VERSION "eCMP INFO-DIV vehicle review 2026-11-03; 125000 bit/s; PSA-RE 67f7581e7622410efdbb29c7eda3b86982b9b450; Apache-2.0"

NS_ :

BS_:

BU_: AAS AMPLI AVP BCM BGP BSG BSI BTA BTEL BTT CDC CMB CRT DIAG_TOOL EDP_C EMF FMUX IC ICSV IDVR IVC_D MATT MDS OVIP PDS_C RAD RBG SDCM VTH WLC

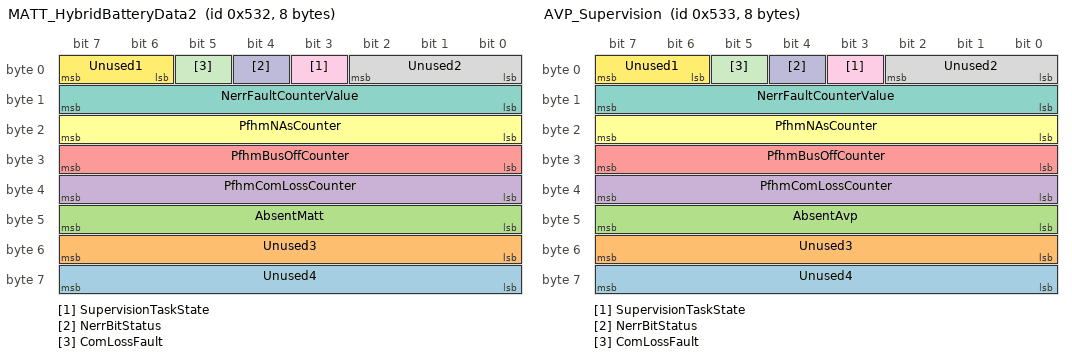
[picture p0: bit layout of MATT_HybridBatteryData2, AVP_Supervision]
BO_ 1330 MATT_HybridBatteryData2: 8 MATT
 SG_ Unused4 : 63|8@0+ (1,0) [0|255] "" Vector__XXX
 SG_ Unused3 : 55|8@0+ (1,0) [0|255] "" Vector__XXX
 SG_ AbsentMatt : 47|8@0+ (1,0) [0|255] "" Vector__XXX
 SG_ PfhmComLossCounter : 39|8@0+ (1,0) [0|255] "" Vector__XXX
 SG_ PfhmBusOffCounter : 31|8@0+ (1,0) [0|255] "" Vector__XXX
 SG_ PfhmNAsCounter : 23|8@0+ (1,0) [0|255] "" Vector__XXX
 SG_ NerrFaultCounterValue : 15|8@0+ (1,0) [0|255] "" Vector__XXX
 SG_ Unused2 : 2|3@0+ (1,0) [0|7] "" Vector__XXX
 SG_ SupervisionTaskState : 3|1@0+ (1,0) [0|1] "" Vector__XXX
 SG_ NerrBitStatus : 4|1@0+ (1,0) [0|1] "" Vector__XXX
 SG_ ComLossFault : 5|1@0+ (1,0) [0|1] "" Vector__XXX
 SG_ Unused1 : 7|2@0+ (1,0) [0|3] "" Vector__XXX

BO_ 1331 AVP_Supervision: 8 AVP
 SG_ Unused4 : 63|8@0+ (1,0) [0|255] "" Vector__XXX
 SG_ Unused3 : 55|8@0+ (1,0) [0|255] "" Vector__XXX
 SG_ AbsentAvp : 47|8@0+ (1,0) [0|255] "" Vector__XXX
 SG_ PfhmComLossCounter : 39|8@0+ (1,0) [0|255] "" Vector__XXX
 SG_ PfhmBusOffCounter : 31|8@0+ (1,0) [0|255] "" Vector__XXX
 SG_ PfhmNAsCounter : 23|8@0+ (1,0) [0|255] "" Vector__XXX
 SG_ NerrFaultCounterValue : 15|8@0+ (1,0) [0|255] "" Vector__XXX
 SG_ Unused2 : 2|3@0+ (1,0) [0|7] "" Vector__XXX
 SG_ SupervisionTaskState : 3|1@0+ (1,0) [0|1] "" Vector__XXX
 SG_ NerrBitStatus : 4|1@0+ (1,0) [0|1] "" Vector__XXX
 SG_ ComLossFault : 5|1@0+ (1,0) [0|1] "" Vector__XXX
 SG_ Unused1 : 7|2@0+ (1,0) [0|3] "" Vector__XXX

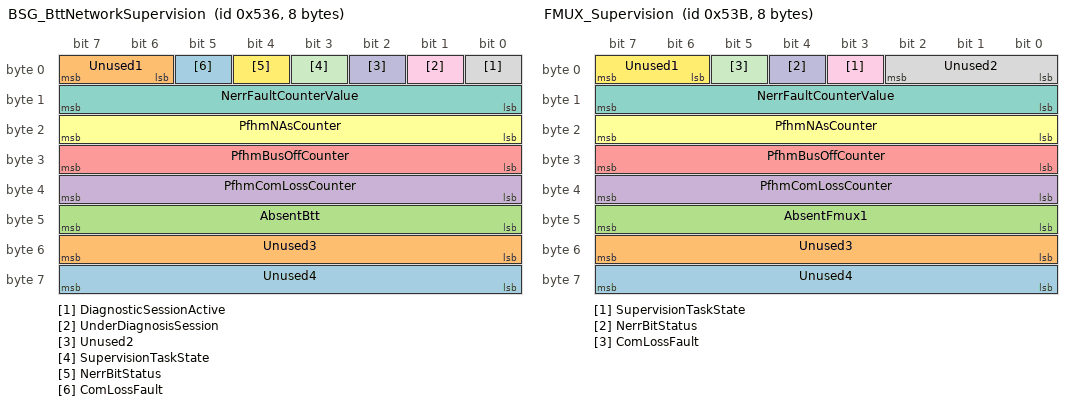
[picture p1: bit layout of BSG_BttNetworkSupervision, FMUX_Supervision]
BO_ 1334 BSG_BttNetworkSupervision: 8 BSG
 SG_ Unused4 : 63|8@0+ (1,0) [0|255] "" Vector__XXX
 SG_ Unused3 : 55|8@0+ (1,0) [0|255] "" Vector__XXX
 SG_ AbsentBtt : 47|8@0+ (1,0) [0|255] "" Vector__XXX
 SG_ PfhmComLossCounter : 39|8@0+ (1,0) [0|255] "" Vector__XXX
 SG_ PfhmBusOffCounter : 31|8@0+ (1,0) [0|255] "" Vector__XXX
 SG_ PfhmNAsCounter : 23|8@0+ (1,0) [0|255] "" Vector__XXX
 SG_ NerrFaultCounterValue : 15|8@0+ (1,0) [0|255] "" Vector__XXX
 SG_ DiagnosticSessionActive : 0|1@0+ (1,0) [0|1] "" Vector__XXX
 SG_ UnderDiagnosisSession : 1|1@0+ (1,0) [0|1] "" Vector__XXX
 SG_ Unused2 : 2|1@0+ (1,0) [0|1] "" Vector__XXX
 SG_ SupervisionTaskState : 3|1@0+ (1,0) [0|1] "" Vector__XXX
 SG_ NerrBitStatus : 4|1@0+ (1,0) [0|1] "" Vector__XXX
 SG_ ComLossFault : 5|1@0+ (1,0) [0|1] "" Vector__XXX
 SG_ Unused1 : 7|2@0+ (1,0) [0|3] "" Vector__XXX

BO_ 1339 FMUX_Supervision: 8 FMUX
 SG_ Unused4 : 63|8@0+ (1,0) [0|255] "" Vector__XXX
 SG_ Unused3 : 55|8@0+ (1,0) [0|255] "" Vector__XXX
 SG_ AbsentFmux1 : 47|8@0+ (1,0) [0|255] "" Vector__XXX
 SG_ PfhmComLossCounter : 39|8@0+ (1,0) [0|255] "" Vector__XXX
 SG_ PfhmBusOffCounter : 31|8@0+ (1,0) [0|255] "" Vector__XXX
 SG_ PfhmNAsCounter : 23|8@0+ (1,0) [0|255] "" Vector__XXX
 SG_ NerrFaultCounterValue : 15|8@0+ (1,0) [0|255] "" Vector__XXX
 SG_ Unused2 : 2|3@0+ (1,0) [0|7] "" Vector__XXX
 SG_ SupervisionTaskState : 3|1@0+ (1,0) [0|1] "" Vector__XXX
 SG_ NerrBitStatus : 4|1@0+ (1,0) [0|1] "" Vector__XXX
 SG_ ComLossFault : 5|1@0+ (1,0) [0|1] "" Vector__XXX
 SG_ Unused1 : 7|2@0+ (1,0) [0|3] "" Vector__XXX

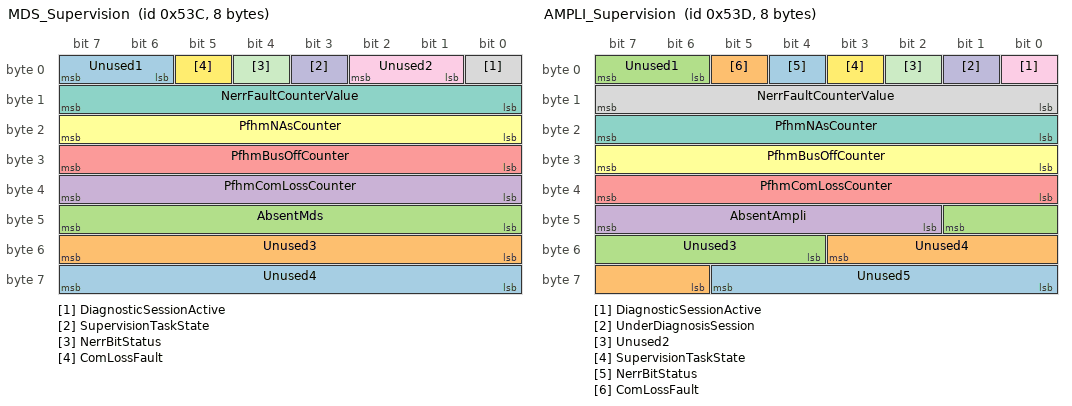
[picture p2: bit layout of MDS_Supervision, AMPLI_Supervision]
BO_ 1340 MDS_Supervision: 8 MDS
 SG_ Unused4 : 63|8@0+ (1,0) [0|255] "" Vector__XXX
 SG_ Unused3 : 55|8@0+ (1,0) [0|255] "" Vector__XXX
 SG_ AbsentMds : 47|8@0+ (1,0) [0|255] "" Vector__XXX
 SG_ PfhmComLossCounter : 39|8@0+ (1,0) [0|255] "" Vector__XXX
 SG_ PfhmBusOffCounter : 31|8@0+ (1,0) [0|255] "" Vector__XXX
 SG_ PfhmNAsCounter : 23|8@0+ (1,0) [0|255] "" Vector__XXX
 SG_ NerrFaultCounterValue : 15|8@0+ (1,0) [0|255] "" Vector__XXX
 SG_ DiagnosticSessionActive : 0|1@0+ (1,0) [0|1] "" Vector__XXX
 SG_ Unused2 : 2|2@0+ (1,0) [0|3] "" Vector__XXX
 SG_ SupervisionTaskState : 3|1@0+ (1,0) [0|1] "" Vector__XXX
 SG_ NerrBitStatus : 4|1@0+ (1,0) [0|1] "" Vector__XXX
 SG_ ComLossFault : 5|1@0+ (1,0) [0|1] "" Vector__XXX
 SG_ Unused1 : 7|2@0+ (1,0) [0|3] "" Vector__XXX

BO_ 1341 AMPLI_Supervision: 8 AMPLI
 SG_ Unused5 : 61|6@0+ (1,0) [0|63] "" Vector__XXX
 SG_ Unused4 : 51|6@0+ (1,0) [0|63] "" Vector__XXX
 SG_ Unused3 : 41|6@0+ (1,0) [0|63] "" Vector__XXX
 SG_ AbsentAmpli : 47|6@0+ (1,0) [0|63] "" Vector__XXX
 SG_ PfhmComLossCounter : 39|8@0+ (1,0) [0|255] "" Vector__XXX
 SG_ PfhmBusOffCounter : 31|8@0+ (1,0) [0|255] "" Vector__XXX
 SG_ PfhmNAsCounter : 23|8@0+ (1,0) [0|255] "" Vector__XXX
 SG_ NerrFaultCounterValue : 15|8@0+ (1,0) [0|255] "" Vector__XXX
 SG_ DiagnosticSessionActive : 0|1@0+ (1,0) [0|1] "" Vector__XXX
 SG_ UnderDiagnosisSession : 1|1@0+ (1,0) [0|1] "" Vector__XXX
 SG_ Unused2 : 2|1@0+ (1,0) [0|1] "" Vector__XXX
 SG_ SupervisionTaskState : 3|1@0+ (1,0) [0|1] "" Vector__XXX
 SG_ NerrBitStatus : 4|1@0+ (1,0) [0|1] "" Vector__XXX
 SG_ ComLossFault : 5|1@0+ (1,0) [0|1] "" Vector__XXX
 SG_ Unused1 : 7|2@0+ (1,0) [0|3] "" Vector__XXX

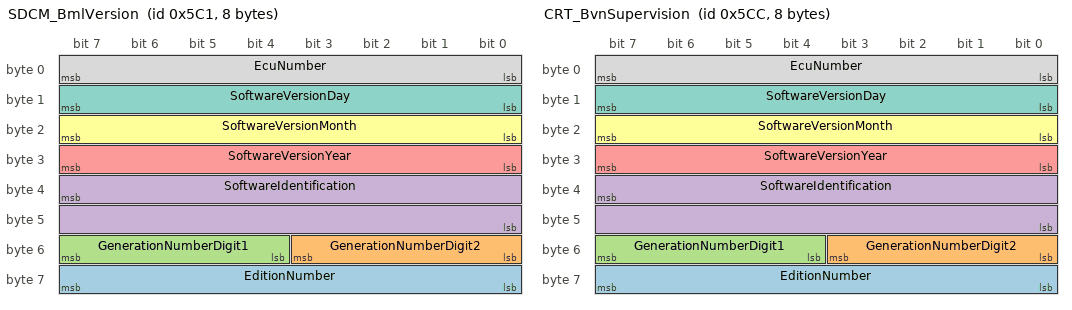
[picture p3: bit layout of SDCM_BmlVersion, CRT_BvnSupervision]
BO_ 1473 SDCM_BmlVersion: 8 SDCM
 SG_ EditionNumber : 63|8@0+ (1,0) [0|254] "" Vector__XXX
 SG_ GenerationNumberDigit2 : 51|4@0+ (1,0) [0|15] "" Vector__XXX
 SG_ GenerationNumberDigit1 : 55|4@0+ (1,0) [0|15] "" Vector__XXX
 SG_ SoftwareIdentification : 39|16@0+ (1,0) [0|65534] "" Vector__XXX
 SG_ SoftwareVersionYear : 31|8@0+ (1,2000) [2000|2200] "" Vector__XXX
 SG_ SoftwareVersionMonth : 23|8@0+ (1,0) [1|12] "month" Vector__XXX
 SG_ SoftwareVersionDay : 15|8@0+ (1,0) [1|31] "day" Vector__XXX
 SG_ EcuNumber : 7|8@0+ (1,0) [0|254] "" Vector__XXX

BO_ 1484 CRT_BvnSupervision: 8 CRT
 SG_ EditionNumber : 63|8@0+ (1,0) [0|254] "" Vector__XXX
 SG_ GenerationNumberDigit2 : 51|4@0+ (1,0) [0|15] "" Vector__XXX
 SG_ GenerationNumberDigit1 : 55|4@0+ (1,0) [0|15] "" Vector__XXX
 SG_ SoftwareIdentification : 39|16@0+ (1,0) [0|65534] "" Vector__XXX
 SG_ SoftwareVersionYear : 31|8@0+ (1,2000) [2000|2200] "" Vector__XXX
 SG_ SoftwareVersionMonth : 23|8@0+ (1,0) [1|12] "month" Vector__XXX
 SG_ SoftwareVersionDay : 15|8@0+ (1,0) [1|31] "day" Vector__XXX
 SG_ EcuNumber : 7|8@0+ (1,0) [0|254] "" Vector__XXX

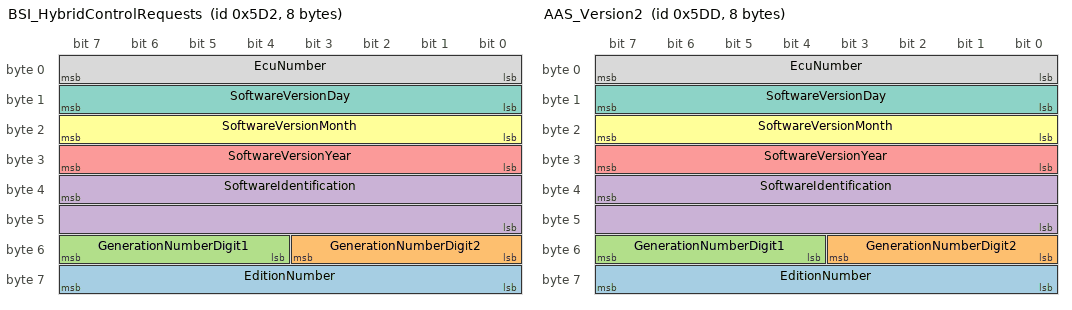
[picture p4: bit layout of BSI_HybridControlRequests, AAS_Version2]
BO_ 1490 BSI_HybridControlRequests: 8 BSI
 SG_ EditionNumber : 63|8@0+ (1,0) [0|254] "" Vector__XXX
 SG_ GenerationNumberDigit2 : 51|4@0+ (1,0) [0|15] "" Vector__XXX
 SG_ GenerationNumberDigit1 : 55|4@0+ (1,0) [0|15] "" Vector__XXX
 SG_ SoftwareIdentification : 39|16@0+ (1,0) [0|65534] "" Vector__XXX
 SG_ SoftwareVersionYear : 31|8@0+ (1,2000) [2000|2200] "" Vector__XXX
 SG_ SoftwareVersionMonth : 23|8@0+ (1,0) [1|12] "month" Vector__XXX
 SG_ SoftwareVersionDay : 15|8@0+ (1,0) [1|31] "day" Vector__XXX
 SG_ EcuNumber : 7|8@0+ (1,0) [0|254] "" Vector__XXX

BO_ 1501 AAS_Version2: 8 AAS
 SG_ EditionNumber : 63|8@0+ (1,0) [0|254] "" Vector__XXX
 SG_ GenerationNumberDigit2 : 51|4@0+ (1,0) [0|15] "" Vector__XXX
 SG_ GenerationNumberDigit1 : 55|4@0+ (1,0) [0|15] "" Vector__XXX
 SG_ SoftwareIdentification : 39|16@0+ (1,0) [0|65534] "" Vector__XXX
 SG_ SoftwareVersionYear : 31|8@0+ (1,2000) [2000|2200] "" Vector__XXX
 SG_ SoftwareVersionMonth : 23|8@0+ (1,0) [1|12] "month" Vector__XXX
 SG_ SoftwareVersionDay : 15|8@0+ (1,0) [1|31] "day" Vector__XXX
 SG_ EcuNumber : 7|8@0+ (1,0) [0|254] "" Vector__XXX

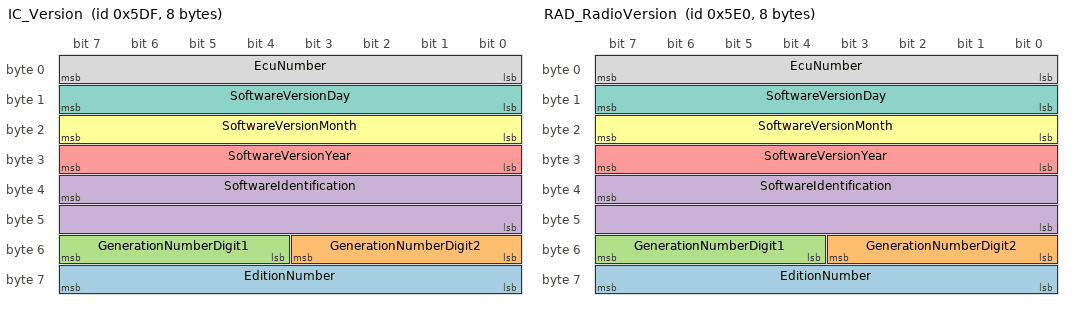
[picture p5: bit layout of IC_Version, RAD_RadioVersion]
BO_ 1503 IC_Version: 8 IC
 SG_ EditionNumber : 63|8@0+ (1,0) [0|254] "" Vector__XXX
 SG_ GenerationNumberDigit2 : 51|4@0+ (1,0) [0|15] "" Vector__XXX
 SG_ GenerationNumberDigit1 : 55|4@0+ (1,0) [0|15] "" Vector__XXX
 SG_ SoftwareIdentification : 39|16@0+ (1,0) [0|65534] "" Vector__XXX
 SG_ SoftwareVersionYear : 31|8@0+ (1,2000) [2000|2200] "" Vector__XXX
 SG_ SoftwareVersionMonth : 23|8@0+ (1,0) [1|12] "month" Vector__XXX
 SG_ SoftwareVersionDay : 15|8@0+ (1,0) [1|31] "day" Vector__XXX
 SG_ EcuNumber : 7|8@0+ (1,0) [0|254] "" Vector__XXX

BO_ 1504 RAD_RadioVersion: 8 RAD
 SG_ EditionNumber : 63|8@0+ (1,0) [0|254] "" Vector__XXX
 SG_ GenerationNumberDigit2 : 51|4@0+ (1,0) [0|15] "" Vector__XXX
 SG_ GenerationNumberDigit1 : 55|4@0+ (1,0) [0|15] "" Vector__XXX
 SG_ SoftwareIdentification : 39|16@0+ (1,0) [0|65534] "" Vector__XXX
 SG_ SoftwareVersionYear : 31|8@0+ (1,2000) [2000|2200] "" Vector__XXX
 SG_ SoftwareVersionMonth : 23|8@0+ (1,0) [1|12] "month" Vector__XXX
 SG_ SoftwareVersionDay : 15|8@0+ (1,0) [1|31] "day" Vector__XXX
 SG_ EcuNumber : 7|8@0+ (1,0) [0|254] "" Vector__XXX

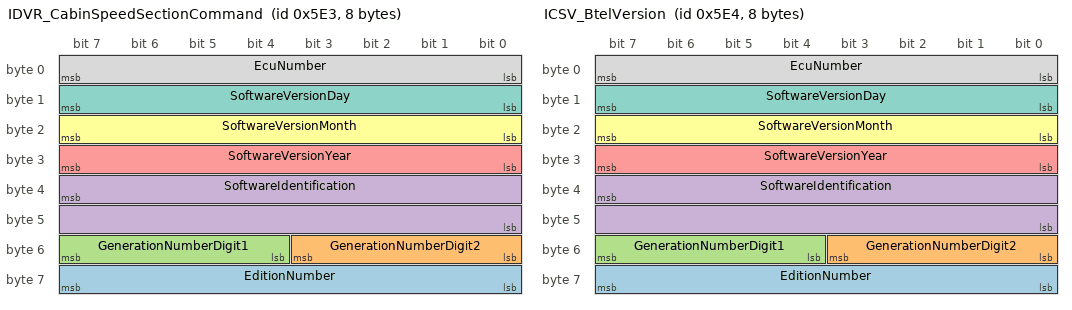
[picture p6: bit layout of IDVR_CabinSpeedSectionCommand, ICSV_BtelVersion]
BO_ 1507 IDVR_CabinSpeedSectionCommand: 8 IDVR
 SG_ EditionNumber : 63|8@0+ (1,0) [0|254] "" Vector__XXX
 SG_ GenerationNumberDigit2 : 51|4@0+ (1,0) [0|15] "" Vector__XXX
 SG_ GenerationNumberDigit1 : 55|4@0+ (1,0) [0|15] "" Vector__XXX
 SG_ SoftwareIdentification : 39|16@0+ (1,0) [0|65534] "" Vector__XXX
 SG_ SoftwareVersionYear : 31|8@0+ (1,2000) [2000|2200] "" Vector__XXX
 SG_ SoftwareVersionMonth : 23|8@0+ (1,0) [1|12] "month" Vector__XXX
 SG_ SoftwareVersionDay : 15|8@0+ (1,0) [1|31] "day" Vector__XXX
 SG_ EcuNumber : 7|8@0+ (1,0) [0|254] "" Vector__XXX

BO_ 1508 ICSV_BtelVersion: 8 ICSV
 SG_ EditionNumber : 63|8@0+ (1,0) [0|254] ""  BSI
 SG_ GenerationNumberDigit2 : 51|4@0+ (1,0) [0|15] ""  BSI
 SG_ GenerationNumberDigit1 : 55|4@0+ (1,0) [0|15] ""  BSI
 SG_ SoftwareIdentification : 39|16@0+ (1,0) [0|65534] ""  BSI
 SG_ SoftwareVersionYear : 31|8@0+ (1,2000) [2000|2200] ""  BSI
 SG_ SoftwareVersionMonth : 23|8@0+ (1,0) [1|12] "month"  BSI
 SG_ SoftwareVersionDay : 15|8@0+ (1,0) [1|31] "day"  BSI
 SG_ EcuNumber : 7|8@0+ (1,0) [0|254] ""  BSI

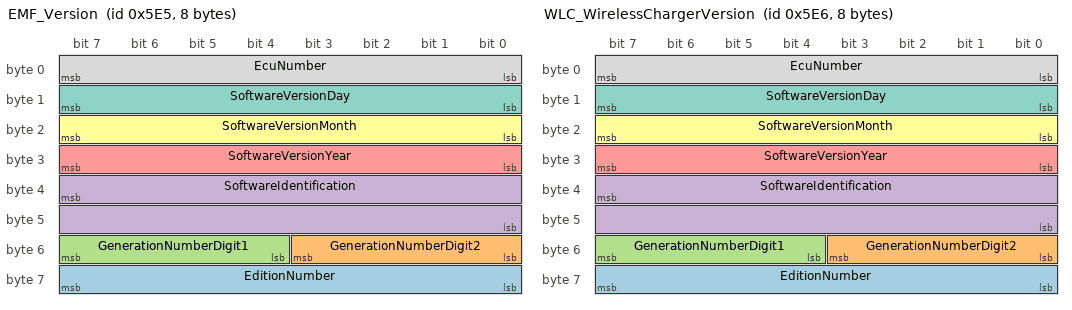
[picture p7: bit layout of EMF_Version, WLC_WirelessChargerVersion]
BO_ 1509 EMF_Version: 8 EMF
 SG_ EditionNumber : 63|8@0+ (1,0) [0|254] "" Vector__XXX
 SG_ GenerationNumberDigit2 : 51|4@0+ (1,0) [0|15] "" Vector__XXX
 SG_ GenerationNumberDigit1 : 55|4@0+ (1,0) [0|15] "" Vector__XXX
 SG_ SoftwareIdentification : 39|16@0+ (1,0) [0|65534] "" Vector__XXX
 SG_ SoftwareVersionYear : 31|8@0+ (1,2000) [2000|2200] "" Vector__XXX
 SG_ SoftwareVersionMonth : 23|8@0+ (1,0) [1|12] "month" Vector__XXX
 SG_ SoftwareVersionDay : 15|8@0+ (1,0) [1|31] "day" Vector__XXX
 SG_ EcuNumber : 7|8@0+ (1,0) [0|254] "" Vector__XXX

BO_ 1510 WLC_WirelessChargerVersion: 8 WLC
 SG_ EditionNumber : 63|8@0+ (1,0) [0|254] "" Vector__XXX
 SG_ GenerationNumberDigit2 : 51|4@0+ (1,0) [0|15] "" Vector__XXX
 SG_ GenerationNumberDigit1 : 55|4@0+ (1,0) [0|15] "" Vector__XXX
 SG_ SoftwareIdentification : 39|16@0+ (1,0) [0|65534] "" Vector__XXX
 SG_ SoftwareVersionYear : 31|8@0+ (1,2000) [2000|2200] "" Vector__XXX
 SG_ SoftwareVersionMonth : 23|8@0+ (1,0) [1|12] "month" Vector__XXX
 SG_ SoftwareVersionDay : 15|8@0+ (1,0) [1|31] "day" Vector__XXX
 SG_ EcuNumber : 7|8@0+ (1,0) [0|254] "" Vector__XXX

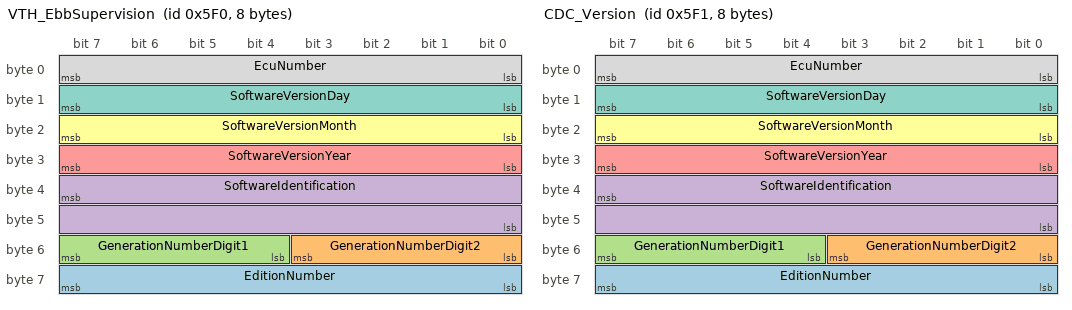
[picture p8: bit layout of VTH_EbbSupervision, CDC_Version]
BO_ 1520 VTH_EbbSupervision: 8 VTH
 SG_ EditionNumber : 63|8@0+ (1,0) [0|254] "" Vector__XXX
 SG_ GenerationNumberDigit2 : 51|4@0+ (1,0) [0|15] "" Vector__XXX
 SG_ GenerationNumberDigit1 : 55|4@0+ (1,0) [0|15] "" Vector__XXX
 SG_ SoftwareIdentification : 39|16@0+ (1,0) [0|65534] "" Vector__XXX
 SG_ SoftwareVersionYear : 31|8@0+ (1,2000) [2000|2200] "" Vector__XXX
 SG_ SoftwareVersionMonth : 23|8@0+ (1,0) [1|12] "month" Vector__XXX
 SG_ SoftwareVersionDay : 15|8@0+ (1,0) [1|31] "day" Vector__XXX
 SG_ EcuNumber : 7|8@0+ (1,0) [0|254] "" Vector__XXX

BO_ 1521 CDC_Version: 8 CDC
 SG_ EditionNumber : 63|8@0+ (1,0) [0|254] "" Vector__XXX
 SG_ GenerationNumberDigit2 : 51|4@0+ (1,0) [0|15] "" Vector__XXX
 SG_ GenerationNumberDigit1 : 55|4@0+ (1,0) [0|15] "" Vector__XXX
 SG_ SoftwareIdentification : 39|16@0+ (1,0) [0|65534] "" Vector__XXX
 SG_ SoftwareVersionYear : 31|8@0+ (1,2000) [2000|2200] "" Vector__XXX
 SG_ SoftwareVersionMonth : 23|8@0+ (1,0) [1|12] "month" Vector__XXX
 SG_ SoftwareVersionDay : 15|8@0+ (1,0) [1|31] "day" Vector__XXX
 SG_ EcuNumber : 7|8@0+ (1,0) [0|254] "" Vector__XXX

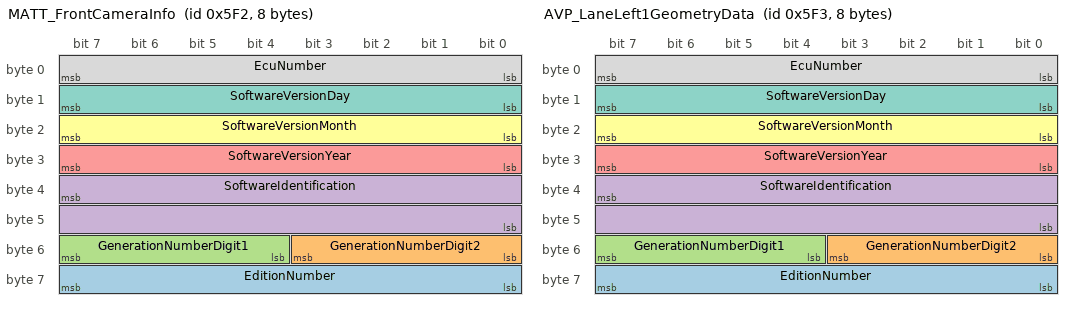
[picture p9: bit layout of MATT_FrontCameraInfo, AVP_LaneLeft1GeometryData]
BO_ 1522 MATT_FrontCameraInfo: 8 MATT
 SG_ EditionNumber : 63|8@0+ (1,0) [0|254] "" Vector__XXX
 SG_ GenerationNumberDigit2 : 51|4@0+ (1,0) [0|15] "" Vector__XXX
 SG_ GenerationNumberDigit1 : 55|4@0+ (1,0) [0|15] "" Vector__XXX
 SG_ SoftwareIdentification : 39|16@0+ (1,0) [0|65534] "" Vector__XXX
 SG_ SoftwareVersionYear : 31|8@0+ (1,2000) [2000|2200] "" Vector__XXX
 SG_ SoftwareVersionMonth : 23|8@0+ (1,0) [1|12] "month" Vector__XXX
 SG_ SoftwareVersionDay : 15|8@0+ (1,0) [1|31] "day" Vector__XXX
 SG_ EcuNumber : 7|8@0+ (1,0) [0|254] "" Vector__XXX

BO_ 1523 AVP_LaneLeft1GeometryData: 8 AVP
 SG_ EditionNumber : 63|8@0+ (1,0) [0|254] "" Vector__XXX
 SG_ GenerationNumberDigit2 : 51|4@0+ (1,0) [0|15] "" Vector__XXX
 SG_ GenerationNumberDigit1 : 55|4@0+ (1,0) [0|15] "" Vector__XXX
 SG_ SoftwareIdentification : 39|16@0+ (1,0) [0|65534] "" Vector__XXX
 SG_ SoftwareVersionYear : 31|8@0+ (1,2000) [2000|2200] "" Vector__XXX
 SG_ SoftwareVersionMonth : 23|8@0+ (1,0) [1|12] "month" Vector__XXX
 SG_ SoftwareVersionDay : 15|8@0+ (1,0) [1|31] "day" Vector__XXX
 SG_ EcuNumber : 7|8@0+ (1,0) [0|254] "" Vector__XXX

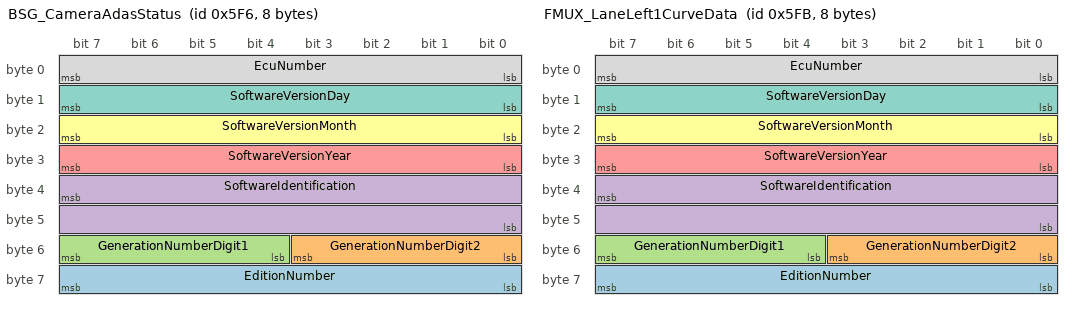
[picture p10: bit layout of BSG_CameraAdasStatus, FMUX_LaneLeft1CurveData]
BO_ 1526 BSG_CameraAdasStatus: 8 BSG
 SG_ EditionNumber : 63|8@0+ (1,0) [0|254] "" Vector__XXX
 SG_ GenerationNumberDigit2 : 51|4@0+ (1,0) [0|15] "" Vector__XXX
 SG_ GenerationNumberDigit1 : 55|4@0+ (1,0) [0|15] "" Vector__XXX
 SG_ SoftwareIdentification : 39|16@0+ (1,0) [0|65534] "" Vector__XXX
 SG_ SoftwareVersionYear : 31|8@0+ (1,2000) [2000|2200] "" Vector__XXX
 SG_ SoftwareVersionMonth : 23|8@0+ (1,0) [1|12] "month" Vector__XXX
 SG_ SoftwareVersionDay : 15|8@0+ (1,0) [1|31] "day" Vector__XXX
 SG_ EcuNumber : 7|8@0+ (1,0) [0|254] "" Vector__XXX

BO_ 1531 FMUX_LaneLeft1CurveData: 8 FMUX
 SG_ EditionNumber : 63|8@0+ (1,0) [0|254] "" Vector__XXX
 SG_ GenerationNumberDigit2 : 51|4@0+ (1,0) [0|15] "" Vector__XXX
 SG_ GenerationNumberDigit1 : 55|4@0+ (1,0) [0|15] "" Vector__XXX
 SG_ SoftwareIdentification : 39|16@0+ (1,0) [0|65534] "" Vector__XXX
 SG_ SoftwareVersionYear : 31|8@0+ (1,2000) [2000|2200] "" Vector__XXX
 SG_ SoftwareVersionMonth : 23|8@0+ (1,0) [1|12] "month" Vector__XXX
 SG_ SoftwareVersionDay : 15|8@0+ (1,0) [1|31] "day" Vector__XXX
 SG_ EcuNumber : 7|8@0+ (1,0) [0|254] "" Vector__XXX

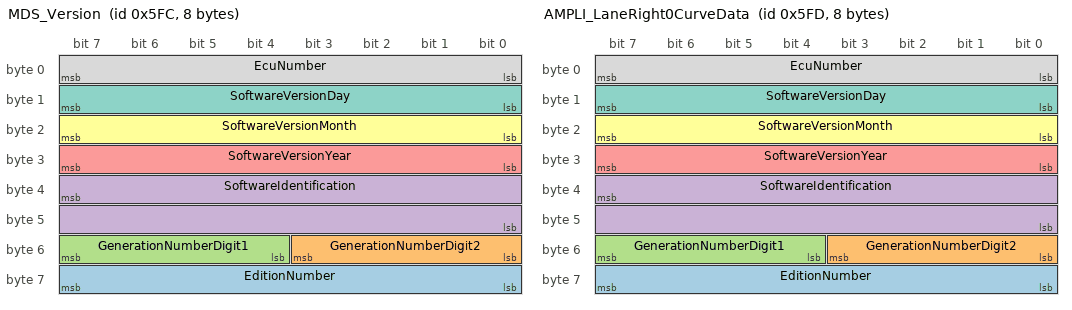
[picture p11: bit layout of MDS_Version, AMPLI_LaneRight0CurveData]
BO_ 1532 MDS_Version: 8 MDS
 SG_ EditionNumber : 63|8@0+ (1,0) [0|254] "" Vector__XXX
 SG_ GenerationNumberDigit2 : 51|4@0+ (1,0) [0|15] "" Vector__XXX
 SG_ GenerationNumberDigit1 : 55|4@0+ (1,0) [0|15] "" Vector__XXX
 SG_ SoftwareIdentification : 39|16@0+ (1,0) [0|65534] "" Vector__XXX
 SG_ SoftwareVersionYear : 31|8@0+ (1,2000) [2000|2200] "" Vector__XXX
 SG_ SoftwareVersionMonth : 23|8@0+ (1,0) [1|12] "month" Vector__XXX
 SG_ SoftwareVersionDay : 15|8@0+ (1,0) [1|31] "day" Vector__XXX
 SG_ EcuNumber : 7|8@0+ (1,0) [0|254] "" Vector__XXX

BO_ 1533 AMPLI_LaneRight0CurveData: 8 AMPLI
 SG_ EditionNumber : 63|8@0+ (1,0) [0|254] "" Vector__XXX
 SG_ GenerationNumberDigit2 : 51|4@0+ (1,0) [0|15] "" Vector__XXX
 SG_ GenerationNumberDigit1 : 55|4@0+ (1,0) [0|15] "" Vector__XXX
 SG_ SoftwareIdentification : 39|16@0+ (1,0) [0|65534] "" Vector__XXX
 SG_ SoftwareVersionYear : 31|8@0+ (1,2000) [2000|2200] "" Vector__XXX
 SG_ SoftwareVersionMonth : 23|8@0+ (1,0) [1|12] "month" Vector__XXX
 SG_ SoftwareVersionDay : 15|8@0+ (1,0) [1|31] "day" Vector__XXX
 SG_ EcuNumber : 7|8@0+ (1,0) [0|254] "" Vector__XXX

BO_ 1576 BSI_DiagResponse: 8 BSI
 SG_ FlowPadding5 m3 : 63|8@0+ (1,0) [0|255] "raw"  MDS
 SG_ FirstData6 m1 : 63|8@0+ (1,0) [0|255] "raw"  MDS
 SG_ UnknownData7 m4 : 63|8@0+ (1,0) [0|255] "raw"  MDS
 SG_ ConsecutiveData7 m2 : 63|8@0+ (1,0) [0|255] "raw"  MDS
 SG_ SingleData7 m0 : 63|8@0+ (1,0) [0|255] "raw"  MDS
 SG_ FlowPadding4 m3 : 55|8@0+ (1,0) [0|255] "raw"  MDS
 SG_ FirstData5 m1 : 55|8@0+ (1,0) [0|255] "raw"  MDS
 SG_ UnknownData6 m4 : 55|8@0+ (1,0) [0|255] "raw"  MDS
 SG_ ConsecutiveData6 m2 : 55|8@0+ (1,0) [0|255] "raw"  MDS
 SG_ SingleData6 m0 : 55|8@0+ (1,0) [0|255] "raw"  MDS
 SG_ FlowPadding3 m3 : 47|8@0+ (1,0) [0|255] "raw"  MDS
 SG_ FirstData4 m1 : 47|8@0+ (1,0) [0|255] "raw"  MDS
 SG_ UnknownData5 m4 : 47|8@0+ (1,0) [0|255] "raw"  MDS
 SG_ ConsecutiveData5 m2 : 47|8@0+ (1,0) [0|255] "raw"  MDS
 SG_ SingleData5 m0 : 47|8@0+ (1,0) [0|255] "raw"  MDS
 SG_ FlowPadding2 m3 : 39|8@0+ (1,0) [0|255] "raw"  MDS
 SG_ FirstData3 m1 : 39|8@0+ (1,0) [0|255] "raw"  MDS
 SG_ UnknownData4 m4 : 39|8@0+ (1,0) [0|255] "raw"  MDS
 SG_ ConsecutiveData4 m2 : 39|8@0+ (1,0) [0|255] "raw"  MDS
 SG_ SingleData4 m0 : 39|8@0+ (1,0) [0|255] "raw"  MDS
 SG_ FlowPadding1 m3 : 31|8@0+ (1,0) [0|255] "raw"  MDS
 SG_ FirstData2 m1 : 31|8@0+ (1,0) [0|255] "raw"  MDS
 SG_ UnknownData3 m4 : 31|8@0+ (1,0) [0|255] "raw"  MDS
 SG_ ConsecutiveData3 m2 : 31|8@0+ (1,0) [0|255] "raw"  MDS
 SG_ SingleData3 m0 : 31|8@0+ (1,0) [0|255] "raw"  MDS
 SG_ FirstData1 m1 : 23|8@0+ (1,0) [0|255] "raw"  MDS
 SG_ UnknownData2 m4 : 23|8@0+ (1,0) [0|255] "raw"  MDS
 SG_ ConsecutiveData2 m2 : 23|8@0+ (1,0) [0|255] "raw"  MDS
 SG_ SingleData2 m0 : 23|8@0+ (1,0) [0|255] "raw"  MDS
 SG_ SeparationTimeRaw m3 : 23|8@0+ (1,0) [0|255] "raw"  MDS
 SG_ UnknownData1 m4 : 15|8@0+ (1,0) [0|255] "raw"  MDS
 SG_ ConsecutiveData1 m2 : 15|8@0+ (1,0) [0|255] "raw"  MDS
 SG_ SingleData1 m0 : 15|8@0+ (1,0) [0|255] "raw"  MDS
 SG_ BlockSize m3 : 15|8@0+ (1,0) [0|255] "raw"  MDS
 SG_ UnknownPciLow m4 : 3|4@0+ (1,0) [0|15] "raw"  MDS
 SG_ FlowStatus m3 : 3|4@0+ (1,0) [0|15] "raw"  MDS
 SG_ ConsecutiveSequence m2 : 3|4@0+ (1,0) [0|15] "raw"  MDS
 SG_ FirstFrameLength m1 : 3|12@0+ (1,0) [0|4095] "raw"  MDS
 SG_ SingleFrameLength m0 : 3|4@0+ (1,0) [0|15] "raw"  MDS
 SG_ IsoTpFrameType M : 7|4@0+ (1,0) [0|15] ""  MDS

BO_ 1601 BSI_DiagResponse_2: 8 BSI
 SG_ FlowPadding5 m3 : 63|8@0+ (1,0) [0|255] "raw"  MDS
 SG_ FirstData6 m1 : 63|8@0+ (1,0) [0|255] "raw"  MDS
 SG_ UnknownData7 m4 : 63|8@0+ (1,0) [0|255] "raw"  MDS
 SG_ ConsecutiveData7 m2 : 63|8@0+ (1,0) [0|255] "raw"  MDS
 SG_ SingleData7 m0 : 63|8@0+ (1,0) [0|255] "raw"  MDS
 SG_ FlowPadding4 m3 : 55|8@0+ (1,0) [0|255] "raw"  MDS
 SG_ FirstData5 m1 : 55|8@0+ (1,0) [0|255] "raw"  MDS
 SG_ UnknownData6 m4 : 55|8@0+ (1,0) [0|255] "raw"  MDS
 SG_ ConsecutiveData6 m2 : 55|8@0+ (1,0) [0|255] "raw"  MDS
 SG_ SingleData6 m0 : 55|8@0+ (1,0) [0|255] "raw"  MDS
 SG_ FlowPadding3 m3 : 47|8@0+ (1,0) [0|255] "raw"  MDS
 SG_ FirstData4 m1 : 47|8@0+ (1,0) [0|255] "raw"  MDS
 SG_ UnknownData5 m4 : 47|8@0+ (1,0) [0|255] "raw"  MDS
 SG_ ConsecutiveData5 m2 : 47|8@0+ (1,0) [0|255] "raw"  MDS
 SG_ SingleData5 m0 : 47|8@0+ (1,0) [0|255] "raw"  MDS
 SG_ FlowPadding2 m3 : 39|8@0+ (1,0) [0|255] "raw"  MDS
 SG_ FirstData3 m1 : 39|8@0+ (1,0) [0|255] "raw"  MDS
 SG_ UnknownData4 m4 : 39|8@0+ (1,0) [0|255] "raw"  MDS
 SG_ ConsecutiveData4 m2 : 39|8@0+ (1,0) [0|255] "raw"  MDS
 SG_ SingleData4 m0 : 39|8@0+ (1,0) [0|255] "raw"  MDS
 SG_ FlowPadding1 m3 : 31|8@0+ (1,0) [0|255] "raw"  MDS
 SG_ FirstData2 m1 : 31|8@0+ (1,0) [0|255] "raw"  MDS
 SG_ UnknownData3 m4 : 31|8@0+ (1,0) [0|255] "raw"  MDS
 SG_ ConsecutiveData3 m2 : 31|8@0+ (1,0) [0|255] "raw"  MDS
 SG_ SingleData3 m0 : 31|8@0+ (1,0) [0|255] "raw"  MDS
 SG_ FirstData1 m1 : 23|8@0+ (1,0) [0|255] "raw"  MDS
 SG_ UnknownData2 m4 : 23|8@0+ (1,0) [0|255] "raw"  MDS
 SG_ ConsecutiveData2 m2 : 23|8@0+ (1,0) [0|255] "raw"  MDS
 SG_ SingleData2 m0 : 23|8@0+ (1,0) [0|255] "raw"  MDS
 SG_ SeparationTimeRaw m3 : 23|8@0+ (1,0) [0|255] "raw"  MDS
 SG_ UnknownData1 m4 : 15|8@0+ (1,0) [0|255] "raw"  MDS
 SG_ ConsecutiveData1 m2 : 15|8@0+ (1,0) [0|255] "raw"  MDS
 SG_ SingleData1 m0 : 15|8@0+ (1,0) [0|255] "raw"  MDS
 SG_ BlockSize m3 : 15|8@0+ (1,0) [0|255] "raw"  MDS
 SG_ UnknownPciLow m4 : 3|4@0+ (1,0) [0|15] "raw"  MDS
 SG_ FlowStatus m3 : 3|4@0+ (1,0) [0|15] "raw"  MDS
 SG_ ConsecutiveSequence m2 : 3|4@0+ (1,0) [0|15] "raw"  MDS
 SG_ FirstFrameLength m1 : 3|12@0+ (1,0) [0|4095] "raw"  MDS
 SG_ SingleFrameLength m0 : 3|4@0+ (1,0) [0|15] "raw"  MDS
 SG_ IsoTpFrameType M : 7|4@0+ (1,0) [0|15] ""  MDS

BO_ 1602 BSI_DiagResponse_3: 8 BSI
 SG_ FlowPadding5 m3 : 63|8@0+ (1,0) [0|255] "raw"  MDS
 SG_ FirstData6 m1 : 63|8@0+ (1,0) [0|255] "raw"  MDS
 SG_ UnknownData7 m4 : 63|8@0+ (1,0) [0|255] "raw"  MDS
 SG_ ConsecutiveData7 m2 : 63|8@0+ (1,0) [0|255] "raw"  MDS
 SG_ SingleData7 m0 : 63|8@0+ (1,0) [0|255] "raw"  MDS
 SG_ FlowPadding4 m3 : 55|8@0+ (1,0) [0|255] "raw"  MDS
 SG_ FirstData5 m1 : 55|8@0+ (1,0) [0|255] "raw"  MDS
 SG_ UnknownData6 m4 : 55|8@0+ (1,0) [0|255] "raw"  MDS
 SG_ ConsecutiveData6 m2 : 55|8@0+ (1,0) [0|255] "raw"  MDS
 SG_ SingleData6 m0 : 55|8@0+ (1,0) [0|255] "raw"  MDS
 SG_ FlowPadding3 m3 : 47|8@0+ (1,0) [0|255] "raw"  MDS
 SG_ FirstData4 m1 : 47|8@0+ (1,0) [0|255] "raw"  MDS
 SG_ UnknownData5 m4 : 47|8@0+ (1,0) [0|255] "raw"  MDS
 SG_ ConsecutiveData5 m2 : 47|8@0+ (1,0) [0|255] "raw"  MDS
 SG_ SingleData5 m0 : 47|8@0+ (1,0) [0|255] "raw"  MDS
 SG_ FlowPadding2 m3 : 39|8@0+ (1,0) [0|255] "raw"  MDS
 SG_ FirstData3 m1 : 39|8@0+ (1,0) [0|255] "raw"  MDS
 SG_ UnknownData4 m4 : 39|8@0+ (1,0) [0|255] "raw"  MDS
 SG_ ConsecutiveData4 m2 : 39|8@0+ (1,0) [0|255] "raw"  MDS
 SG_ SingleData4 m0 : 39|8@0+ (1,0) [0|255] "raw"  MDS
 SG_ FlowPadding1 m3 : 31|8@0+ (1,0) [0|255] "raw"  MDS
 SG_ FirstData2 m1 : 31|8@0+ (1,0) [0|255] "raw"  MDS
 SG_ UnknownData3 m4 : 31|8@0+ (1,0) [0|255] "raw"  MDS
 SG_ ConsecutiveData3 m2 : 31|8@0+ (1,0) [0|255] "raw"  MDS
 SG_ SingleData3 m0 : 31|8@0+ (1,0) [0|255] "raw"  MDS
 SG_ FirstData1 m1 : 23|8@0+ (1,0) [0|255] "raw"  MDS
 SG_ UnknownData2 m4 : 23|8@0+ (1,0) [0|255] "raw"  MDS
 SG_ ConsecutiveData2 m2 : 23|8@0+ (1,0) [0|255] "raw"  MDS
 SG_ SingleData2 m0 : 23|8@0+ (1,0) [0|255] "raw"  MDS
 SG_ SeparationTimeRaw m3 : 23|8@0+ (1,0) [0|255] "raw"  MDS
 SG_ UnknownData1 m4 : 15|8@0+ (1,0) [0|255] "raw"  MDS
 SG_ ConsecutiveData1 m2 : 15|8@0+ (1,0) [0|255] "raw"  MDS
 SG_ SingleData1 m0 : 15|8@0+ (1,0) [0|255] "raw"  MDS
 SG_ BlockSize m3 : 15|8@0+ (1,0) [0|255] "raw"  MDS
 SG_ UnknownPciLow m4 : 3|4@0+ (1,0) [0|15] "raw"  MDS
 SG_ FlowStatus m3 : 3|4@0+ (1,0) [0|15] "raw"  MDS
 SG_ ConsecutiveSequence m2 : 3|4@0+ (1,0) [0|15] "raw"  MDS
 SG_ FirstFrameLength m1 : 3|12@0+ (1,0) [0|4095] "raw"  MDS
 SG_ SingleFrameLength m0 : 3|4@0+ (1,0) [0|15] "raw"  MDS
 SG_ IsoTpFrameType M : 7|4@0+ (1,0) [0|15] ""  MDS

BO_ 1603 OVIP_DiagResponse: 8 OVIP
 SG_ FlowPadding5 m3 : 63|8@0+ (1,0) [0|255] "raw"  BSI,DIAG_TOOL
 SG_ FirstData6 m1 : 63|8@0+ (1,0) [0|255] "raw"  BSI,DIAG_TOOL
 SG_ UnknownData7 m4 : 63|8@0+ (1,0) [0|255] "raw"  BSI,DIAG_TOOL
 SG_ ConsecutiveData7 m2 : 63|8@0+ (1,0) [0|255] "raw"  BSI,DIAG_TOOL
 SG_ SingleData7 m0 : 63|8@0+ (1,0) [0|255] "raw"  BSI,DIAG_TOOL
 SG_ FlowPadding4 m3 : 55|8@0+ (1,0) [0|255] "raw"  BSI,DIAG_TOOL
 SG_ FirstData5 m1 : 55|8@0+ (1,0) [0|255] "raw"  BSI,DIAG_TOOL
 SG_ UnknownData6 m4 : 55|8@0+ (1,0) [0|255] "raw"  BSI,DIAG_TOOL
 SG_ ConsecutiveData6 m2 : 55|8@0+ (1,0) [0|255] "raw"  BSI,DIAG_TOOL
 SG_ SingleData6 m0 : 55|8@0+ (1,0) [0|255] "raw"  BSI,DIAG_TOOL
 SG_ FlowPadding3 m3 : 47|8@0+ (1,0) [0|255] "raw"  BSI,DIAG_TOOL
 SG_ FirstData4 m1 : 47|8@0+ (1,0) [0|255] "raw"  BSI,DIAG_TOOL
 SG_ UnknownData5 m4 : 47|8@0+ (1,0) [0|255] "raw"  BSI,DIAG_TOOL
 SG_ ConsecutiveData5 m2 : 47|8@0+ (1,0) [0|255] "raw"  BSI,DIAG_TOOL
 SG_ SingleData5 m0 : 47|8@0+ (1,0) [0|255] "raw"  BSI,DIAG_TOOL
 SG_ FlowPadding2 m3 : 39|8@0+ (1,0) [0|255] "raw"  BSI,DIAG_TOOL
 SG_ FirstData3 m1 : 39|8@0+ (1,0) [0|255] "raw"  BSI,DIAG_TOOL
 SG_ UnknownData4 m4 : 39|8@0+ (1,0) [0|255] "raw"  BSI,DIAG_TOOL
 SG_ ConsecutiveData4 m2 : 39|8@0+ (1,0) [0|255] "raw"  BSI,DIAG_TOOL
 SG_ SingleData4 m0 : 39|8@0+ (1,0) [0|255] "raw"  BSI,DIAG_TOOL
 SG_ FlowPadding1 m3 : 31|8@0+ (1,0) [0|255] "raw"  BSI,DIAG_TOOL
 SG_ FirstData2 m1 : 31|8@0+ (1,0) [0|255] "raw"  BSI,DIAG_TOOL
 SG_ UnknownData3 m4 : 31|8@0+ (1,0) [0|255] "raw"  BSI,DIAG_TOOL
 SG_ ConsecutiveData3 m2 : 31|8@0+ (1,0) [0|255] "raw"  BSI,DIAG_TOOL
 SG_ SingleData3 m0 : 31|8@0+ (1,0) [0|255] "raw"  BSI,DIAG_TOOL
 SG_ FirstData1 m1 : 23|8@0+ (1,0) [0|255] "raw"  BSI,DIAG_TOOL
 SG_ UnknownData2 m4 : 23|8@0+ (1,0) [0|255] "raw"  BSI,DIAG_TOOL
 SG_ ConsecutiveData2 m2 : 23|8@0+ (1,0) [0|255] "raw"  BSI,DIAG_TOOL
 SG_ SingleData2 m0 : 23|8@0+ (1,0) [0|255] "raw"  BSI,DIAG_TOOL
 SG_ SeparationTimeRaw m3 : 23|8@0+ (1,0) [0|255] "raw"  BSI,DIAG_TOOL
 SG_ UnknownData1 m4 : 15|8@0+ (1,0) [0|255] "raw"  BSI,DIAG_TOOL
 SG_ ConsecutiveData1 m2 : 15|8@0+ (1,0) [0|255] "raw"  BSI,DIAG_TOOL
 SG_ SingleData1 m0 : 15|8@0+ (1,0) [0|255] "raw"  BSI,DIAG_TOOL
 SG_ BlockSize m3 : 15|8@0+ (1,0) [0|255] "raw"  BSI,DIAG_TOOL
 SG_ UnknownPciLow m4 : 3|4@0+ (1,0) [0|15] "raw"  BSI,DIAG_TOOL
 SG_ FlowStatus m3 : 3|4@0+ (1,0) [0|15] "raw"  BSI,DIAG_TOOL
 SG_ ConsecutiveSequence m2 : 3|4@0+ (1,0) [0|15] "raw"  BSI,DIAG_TOOL
 SG_ FirstFrameLength m1 : 3|12@0+ (1,0) [0|4095] "raw"  BSI,DIAG_TOOL
 SG_ SingleFrameLength m0 : 3|4@0+ (1,0) [0|15] "raw"  BSI,DIAG_TOOL
 SG_ IsoTpFrameType M : 7|4@0+ (1,0) [0|15] ""  BSI,DIAG_TOOL

BO_ 1604 BSI_DiagResponse_4: 8 BSI
 SG_ FlowPadding5 m3 : 63|8@0+ (1,0) [0|255] "raw"  MDS
 SG_ FirstData6 m1 : 63|8@0+ (1,0) [0|255] "raw"  MDS
 SG_ UnknownData7 m4 : 63|8@0+ (1,0) [0|255] "raw"  MDS
 SG_ ConsecutiveData7 m2 : 63|8@0+ (1,0) [0|255] "raw"  MDS
 SG_ SingleData7 m0 : 63|8@0+ (1,0) [0|255] "raw"  MDS
 SG_ FlowPadding4 m3 : 55|8@0+ (1,0) [0|255] "raw"  MDS
 SG_ FirstData5 m1 : 55|8@0+ (1,0) [0|255] "raw"  MDS
 SG_ UnknownData6 m4 : 55|8@0+ (1,0) [0|255] "raw"  MDS
 SG_ ConsecutiveData6 m2 : 55|8@0+ (1,0) [0|255] "raw"  MDS
 SG_ SingleData6 m0 : 55|8@0+ (1,0) [0|255] "raw"  MDS
 SG_ FlowPadding3 m3 : 47|8@0+ (1,0) [0|255] "raw"  MDS
 SG_ FirstData4 m1 : 47|8@0+ (1,0) [0|255] "raw"  MDS
 SG_ UnknownData5 m4 : 47|8@0+ (1,0) [0|255] "raw"  MDS
 SG_ ConsecutiveData5 m2 : 47|8@0+ (1,0) [0|255] "raw"  MDS
 SG_ SingleData5 m0 : 47|8@0+ (1,0) [0|255] "raw"  MDS
 SG_ FlowPadding2 m3 : 39|8@0+ (1,0) [0|255] "raw"  MDS
 SG_ FirstData3 m1 : 39|8@0+ (1,0) [0|255] "raw"  MDS
 SG_ UnknownData4 m4 : 39|8@0+ (1,0) [0|255] "raw"  MDS
 SG_ ConsecutiveData4 m2 : 39|8@0+ (1,0) [0|255] "raw"  MDS
 SG_ SingleData4 m0 : 39|8@0+ (1,0) [0|255] "raw"  MDS
 SG_ FlowPadding1 m3 : 31|8@0+ (1,0) [0|255] "raw"  MDS
 SG_ FirstData2 m1 : 31|8@0+ (1,0) [0|255] "raw"  MDS
 SG_ UnknownData3 m4 : 31|8@0+ (1,0) [0|255] "raw"  MDS
 SG_ ConsecutiveData3 m2 : 31|8@0+ (1,0) [0|255] "raw"  MDS
 SG_ SingleData3 m0 : 31|8@0+ (1,0) [0|255] "raw"  MDS
 SG_ FirstData1 m1 : 23|8@0+ (1,0) [0|255] "raw"  MDS
 SG_ UnknownData2 m4 : 23|8@0+ (1,0) [0|255] "raw"  MDS
 SG_ ConsecutiveData2 m2 : 23|8@0+ (1,0) [0|255] "raw"  MDS
 SG_ SingleData2 m0 : 23|8@0+ (1,0) [0|255] "raw"  MDS
 SG_ SeparationTimeRaw m3 : 23|8@0+ (1,0) [0|255] "raw"  MDS
 SG_ UnknownData1 m4 : 15|8@0+ (1,0) [0|255] "raw"  MDS
 SG_ ConsecutiveData1 m2 : 15|8@0+ (1,0) [0|255] "raw"  MDS
 SG_ SingleData1 m0 : 15|8@0+ (1,0) [0|255] "raw"  MDS
 SG_ BlockSize m3 : 15|8@0+ (1,0) [0|255] "raw"  MDS
 SG_ UnknownPciLow m4 : 3|4@0+ (1,0) [0|15] "raw"  MDS
 SG_ FlowStatus m3 : 3|4@0+ (1,0) [0|15] "raw"  MDS
 SG_ ConsecutiveSequence m2 : 3|4@0+ (1,0) [0|15] "raw"  MDS
 SG_ FirstFrameLength m1 : 3|12@0+ (1,0) [0|4095] "raw"  MDS
 SG_ SingleFrameLength m0 : 3|4@0+ (1,0) [0|15] "raw"  MDS
 SG_ IsoTpFrameType M : 7|4@0+ (1,0) [0|15] ""  MDS

BO_ 1605 BSI_DiagResponse_5: 8 BSI
 SG_ FlowPadding5 m3 : 63|8@0+ (1,0) [0|255] "raw"  MDS
 SG_ FirstData6 m1 : 63|8@0+ (1,0) [0|255] "raw"  MDS
 SG_ UnknownData7 m4 : 63|8@0+ (1,0) [0|255] "raw"  MDS
 SG_ ConsecutiveData7 m2 : 63|8@0+ (1,0) [0|255] "raw"  MDS
 SG_ SingleData7 m0 : 63|8@0+ (1,0) [0|255] "raw"  MDS
 SG_ FlowPadding4 m3 : 55|8@0+ (1,0) [0|255] "raw"  MDS
 SG_ FirstData5 m1 : 55|8@0+ (1,0) [0|255] "raw"  MDS
 SG_ UnknownData6 m4 : 55|8@0+ (1,0) [0|255] "raw"  MDS
 SG_ ConsecutiveData6 m2 : 55|8@0+ (1,0) [0|255] "raw"  MDS
 SG_ SingleData6 m0 : 55|8@0+ (1,0) [0|255] "raw"  MDS
 SG_ FlowPadding3 m3 : 47|8@0+ (1,0) [0|255] "raw"  MDS
 SG_ FirstData4 m1 : 47|8@0+ (1,0) [0|255] "raw"  MDS
 SG_ UnknownData5 m4 : 47|8@0+ (1,0) [0|255] "raw"  MDS
 SG_ ConsecutiveData5 m2 : 47|8@0+ (1,0) [0|255] "raw"  MDS
 SG_ SingleData5 m0 : 47|8@0+ (1,0) [0|255] "raw"  MDS
 SG_ FlowPadding2 m3 : 39|8@0+ (1,0) [0|255] "raw"  MDS
 SG_ FirstData3 m1 : 39|8@0+ (1,0) [0|255] "raw"  MDS
 SG_ UnknownData4 m4 : 39|8@0+ (1,0) [0|255] "raw"  MDS
 SG_ ConsecutiveData4 m2 : 39|8@0+ (1,0) [0|255] "raw"  MDS
 SG_ SingleData4 m0 : 39|8@0+ (1,0) [0|255] "raw"  MDS
 SG_ FlowPadding1 m3 : 31|8@0+ (1,0) [0|255] "raw"  MDS
 SG_ FirstData2 m1 : 31|8@0+ (1,0) [0|255] "raw"  MDS
 SG_ UnknownData3 m4 : 31|8@0+ (1,0) [0|255] "raw"  MDS
 SG_ ConsecutiveData3 m2 : 31|8@0+ (1,0) [0|255] "raw"  MDS
 SG_ SingleData3 m0 : 31|8@0+ (1,0) [0|255] "raw"  MDS
 SG_ FirstData1 m1 : 23|8@0+ (1,0) [0|255] "raw"  MDS
 SG_ UnknownData2 m4 : 23|8@0+ (1,0) [0|255] "raw"  MDS
 SG_ ConsecutiveData2 m2 : 23|8@0+ (1,0) [0|255] "raw"  MDS
 SG_ SingleData2 m0 : 23|8@0+ (1,0) [0|255] "raw"  MDS
 SG_ SeparationTimeRaw m3 : 23|8@0+ (1,0) [0|255] "raw"  MDS
 SG_ UnknownData1 m4 : 15|8@0+ (1,0) [0|255] "raw"  MDS
 SG_ ConsecutiveData1 m2 : 15|8@0+ (1,0) [0|255] "raw"  MDS
 SG_ SingleData1 m0 : 15|8@0+ (1,0) [0|255] "raw"  MDS
 SG_ BlockSize m3 : 15|8@0+ (1,0) [0|255] "raw"  MDS
 SG_ UnknownPciLow m4 : 3|4@0+ (1,0) [0|15] "raw"  MDS
 SG_ FlowStatus m3 : 3|4@0+ (1,0) [0|15] "raw"  MDS
 SG_ ConsecutiveSequence m2 : 3|4@0+ (1,0) [0|15] "raw"  MDS
 SG_ FirstFrameLength m1 : 3|12@0+ (1,0) [0|4095] "raw"  MDS
 SG_ SingleFrameLength m0 : 3|4@0+ (1,0) [0|15] "raw"  MDS
 SG_ IsoTpFrameType M : 7|4@0+ (1,0) [0|15] ""  MDS

BO_ 1606 BSI_DiagResponse_6: 8 BSI
 SG_ FlowPadding5 m3 : 63|8@0+ (1,0) [0|255] "raw"  MDS
 SG_ FirstData6 m1 : 63|8@0+ (1,0) [0|255] "raw"  MDS
 SG_ UnknownData7 m4 : 63|8@0+ (1,0) [0|255] "raw"  MDS
 SG_ ConsecutiveData7 m2 : 63|8@0+ (1,0) [0|255] "raw"  MDS
 SG_ SingleData7 m0 : 63|8@0+ (1,0) [0|255] "raw"  MDS
 SG_ FlowPadding4 m3 : 55|8@0+ (1,0) [0|255] "raw"  MDS
 SG_ FirstData5 m1 : 55|8@0+ (1,0) [0|255] "raw"  MDS
 SG_ UnknownData6 m4 : 55|8@0+ (1,0) [0|255] "raw"  MDS
 SG_ ConsecutiveData6 m2 : 55|8@0+ (1,0) [0|255] "raw"  MDS
 SG_ SingleData6 m0 : 55|8@0+ (1,0) [0|255] "raw"  MDS
 SG_ FlowPadding3 m3 : 47|8@0+ (1,0) [0|255] "raw"  MDS
 SG_ FirstData4 m1 : 47|8@0+ (1,0) [0|255] "raw"  MDS
 SG_ UnknownData5 m4 : 47|8@0+ (1,0) [0|255] "raw"  MDS
 SG_ ConsecutiveData5 m2 : 47|8@0+ (1,0) [0|255] "raw"  MDS
 SG_ SingleData5 m0 : 47|8@0+ (1,0) [0|255] "raw"  MDS
 SG_ FlowPadding2 m3 : 39|8@0+ (1,0) [0|255] "raw"  MDS
 SG_ FirstData3 m1 : 39|8@0+ (1,0) [0|255] "raw"  MDS
 SG_ UnknownData4 m4 : 39|8@0+ (1,0) [0|255] "raw"  MDS
 SG_ ConsecutiveData4 m2 : 39|8@0+ (1,0) [0|255] "raw"  MDS
 SG_ SingleData4 m0 : 39|8@0+ (1,0) [0|255] "raw"  MDS
 SG_ FlowPadding1 m3 : 31|8@0+ (1,0) [0|255] "raw"  MDS
 SG_ FirstData2 m1 : 31|8@0+ (1,0) [0|255] "raw"  MDS
 SG_ UnknownData3 m4 : 31|8@0+ (1,0) [0|255] "raw"  MDS
 SG_ ConsecutiveData3 m2 : 31|8@0+ (1,0) [0|255] "raw"  MDS
 SG_ SingleData3 m0 : 31|8@0+ (1,0) [0|255] "raw"  MDS
 SG_ FirstData1 m1 : 23|8@0+ (1,0) [0|255] "raw"  MDS
 SG_ UnknownData2 m4 : 23|8@0+ (1,0) [0|255] "raw"  MDS
 SG_ ConsecutiveData2 m2 : 23|8@0+ (1,0) [0|255] "raw"  MDS
 SG_ SingleData2 m0 : 23|8@0+ (1,0) [0|255] "raw"  MDS
 SG_ SeparationTimeRaw m3 : 23|8@0+ (1,0) [0|255] "raw"  MDS
 SG_ UnknownData1 m4 : 15|8@0+ (1,0) [0|255] "raw"  MDS
 SG_ ConsecutiveData1 m2 : 15|8@0+ (1,0) [0|255] "raw"  MDS
 SG_ SingleData1 m0 : 15|8@0+ (1,0) [0|255] "raw"  MDS
 SG_ BlockSize m3 : 15|8@0+ (1,0) [0|255] "raw"  MDS
 SG_ UnknownPciLow m4 : 3|4@0+ (1,0) [0|15] "raw"  MDS
 SG_ FlowStatus m3 : 3|4@0+ (1,0) [0|15] "raw"  MDS
 SG_ ConsecutiveSequence m2 : 3|4@0+ (1,0) [0|15] "raw"  MDS
 SG_ FirstFrameLength m1 : 3|12@0+ (1,0) [0|4095] "raw"  MDS
 SG_ SingleFrameLength m0 : 3|4@0+ (1,0) [0|15] "raw"  MDS
 SG_ IsoTpFrameType M : 7|4@0+ (1,0) [0|15] ""  MDS

BO_ 1607 BSI_DiagResponse_7: 8 BSI
 SG_ FlowPadding5 m3 : 63|8@0+ (1,0) [0|255] "raw"  MDS
 SG_ FirstData6 m1 : 63|8@0+ (1,0) [0|255] "raw"  MDS
 SG_ UnknownData7 m4 : 63|8@0+ (1,0) [0|255] "raw"  MDS
 SG_ ConsecutiveData7 m2 : 63|8@0+ (1,0) [0|255] "raw"  MDS
 SG_ SingleData7 m0 : 63|8@0+ (1,0) [0|255] "raw"  MDS
 SG_ FlowPadding4 m3 : 55|8@0+ (1,0) [0|255] "raw"  MDS
 SG_ FirstData5 m1 : 55|8@0+ (1,0) [0|255] "raw"  MDS
 SG_ UnknownData6 m4 : 55|8@0+ (1,0) [0|255] "raw"  MDS
 SG_ ConsecutiveData6 m2 : 55|8@0+ (1,0) [0|255] "raw"  MDS
 SG_ SingleData6 m0 : 55|8@0+ (1,0) [0|255] "raw"  MDS
 SG_ FlowPadding3 m3 : 47|8@0+ (1,0) [0|255] "raw"  MDS
 SG_ FirstData4 m1 : 47|8@0+ (1,0) [0|255] "raw"  MDS
 SG_ UnknownData5 m4 : 47|8@0+ (1,0) [0|255] "raw"  MDS
 SG_ ConsecutiveData5 m2 : 47|8@0+ (1,0) [0|255] "raw"  MDS
 SG_ SingleData5 m0 : 47|8@0+ (1,0) [0|255] "raw"  MDS
 SG_ FlowPadding2 m3 : 39|8@0+ (1,0) [0|255] "raw"  MDS
 SG_ FirstData3 m1 : 39|8@0+ (1,0) [0|255] "raw"  MDS
 SG_ UnknownData4 m4 : 39|8@0+ (1,0) [0|255] "raw"  MDS
 SG_ ConsecutiveData4 m2 : 39|8@0+ (1,0) [0|255] "raw"  MDS
 SG_ SingleData4 m0 : 39|8@0+ (1,0) [0|255] "raw"  MDS
 SG_ FlowPadding1 m3 : 31|8@0+ (1,0) [0|255] "raw"  MDS
 SG_ FirstData2 m1 : 31|8@0+ (1,0) [0|255] "raw"  MDS
 SG_ UnknownData3 m4 : 31|8@0+ (1,0) [0|255] "raw"  MDS
 SG_ ConsecutiveData3 m2 : 31|8@0+ (1,0) [0|255] "raw"  MDS
 SG_ SingleData3 m0 : 31|8@0+ (1,0) [0|255] "raw"  MDS
 SG_ FirstData1 m1 : 23|8@0+ (1,0) [0|255] "raw"  MDS
 SG_ UnknownData2 m4 : 23|8@0+ (1,0) [0|255] "raw"  MDS
 SG_ ConsecutiveData2 m2 : 23|8@0+ (1,0) [0|255] "raw"  MDS
 SG_ SingleData2 m0 : 23|8@0+ (1,0) [0|255] "raw"  MDS
 SG_ SeparationTimeRaw m3 : 23|8@0+ (1,0) [0|255] "raw"  MDS
 SG_ UnknownData1 m4 : 15|8@0+ (1,0) [0|255] "raw"  MDS
 SG_ ConsecutiveData1 m2 : 15|8@0+ (1,0) [0|255] "raw"  MDS
 SG_ SingleData1 m0 : 15|8@0+ (1,0) [0|255] "raw"  MDS
 SG_ BlockSize m3 : 15|8@0+ (1,0) [0|255] "raw"  MDS
 SG_ UnknownPciLow m4 : 3|4@0+ (1,0) [0|15] "raw"  MDS
 SG_ FlowStatus m3 : 3|4@0+ (1,0) [0|15] "raw"  MDS
 SG_ ConsecutiveSequence m2 : 3|4@0+ (1,0) [0|15] "raw"  MDS
 SG_ FirstFrameLength m1 : 3|12@0+ (1,0) [0|4095] "raw"  MDS
 SG_ SingleFrameLength m0 : 3|4@0+ (1,0) [0|15] "raw"  MDS
 SG_ IsoTpFrameType M : 7|4@0+ (1,0) [0|15] ""  MDS

BO_ 1608 BSI_DiagResponse_8: 8 BSI
 SG_ FlowPadding5 m3 : 63|8@0+ (1,0) [0|255] "raw"  MDS
 SG_ FirstData6 m1 : 63|8@0+ (1,0) [0|255] "raw"  MDS
 SG_ UnknownData7 m4 : 63|8@0+ (1,0) [0|255] "raw"  MDS
 SG_ ConsecutiveData7 m2 : 63|8@0+ (1,0) [0|255] "raw"  MDS
 SG_ SingleData7 m0 : 63|8@0+ (1,0) [0|255] "raw"  MDS
 SG_ FlowPadding4 m3 : 55|8@0+ (1,0) [0|255] "raw"  MDS
 SG_ FirstData5 m1 : 55|8@0+ (1,0) [0|255] "raw"  MDS
 SG_ UnknownData6 m4 : 55|8@0+ (1,0) [0|255] "raw"  MDS
 SG_ ConsecutiveData6 m2 : 55|8@0+ (1,0) [0|255] "raw"  MDS
 SG_ SingleData6 m0 : 55|8@0+ (1,0) [0|255] "raw"  MDS
 SG_ FlowPadding3 m3 : 47|8@0+ (1,0) [0|255] "raw"  MDS
 SG_ FirstData4 m1 : 47|8@0+ (1,0) [0|255] "raw"  MDS
 SG_ UnknownData5 m4 : 47|8@0+ (1,0) [0|255] "raw"  MDS
 SG_ ConsecutiveData5 m2 : 47|8@0+ (1,0) [0|255] "raw"  MDS
 SG_ SingleData5 m0 : 47|8@0+ (1,0) [0|255] "raw"  MDS
 SG_ FlowPadding2 m3 : 39|8@0+ (1,0) [0|255] "raw"  MDS
 SG_ FirstData3 m1 : 39|8@0+ (1,0) [0|255] "raw"  MDS
 SG_ UnknownData4 m4 : 39|8@0+ (1,0) [0|255] "raw"  MDS
 SG_ ConsecutiveData4 m2 : 39|8@0+ (1,0) [0|255] "raw"  MDS
 SG_ SingleData4 m0 : 39|8@0+ (1,0) [0|255] "raw"  MDS
 SG_ FlowPadding1 m3 : 31|8@0+ (1,0) [0|255] "raw"  MDS
 SG_ FirstData2 m1 : 31|8@0+ (1,0) [0|255] "raw"  MDS
 SG_ UnknownData3 m4 : 31|8@0+ (1,0) [0|255] "raw"  MDS
 SG_ ConsecutiveData3 m2 : 31|8@0+ (1,0) [0|255] "raw"  MDS
 SG_ SingleData3 m0 : 31|8@0+ (1,0) [0|255] "raw"  MDS
 SG_ FirstData1 m1 : 23|8@0+ (1,0) [0|255] "raw"  MDS
 SG_ UnknownData2 m4 : 23|8@0+ (1,0) [0|255] "raw"  MDS
 SG_ ConsecutiveData2 m2 : 23|8@0+ (1,0) [0|255] "raw"  MDS
 SG_ SingleData2 m0 : 23|8@0+ (1,0) [0|255] "raw"  MDS
 SG_ SeparationTimeRaw m3 : 23|8@0+ (1,0) [0|255] "raw"  MDS
 SG_ UnknownData1 m4 : 15|8@0+ (1,0) [0|255] "raw"  MDS
 SG_ ConsecutiveData1 m2 : 15|8@0+ (1,0) [0|255] "raw"  MDS
 SG_ SingleData1 m0 : 15|8@0+ (1,0) [0|255] "raw"  MDS
 SG_ BlockSize m3 : 15|8@0+ (1,0) [0|255] "raw"  MDS
 SG_ UnknownPciLow m4 : 3|4@0+ (1,0) [0|15] "raw"  MDS
 SG_ FlowStatus m3 : 3|4@0+ (1,0) [0|15] "raw"  MDS
 SG_ ConsecutiveSequence m2 : 3|4@0+ (1,0) [0|15] "raw"  MDS
 SG_ FirstFrameLength m1 : 3|12@0+ (1,0) [0|4095] "raw"  MDS
 SG_ SingleFrameLength m0 : 3|4@0+ (1,0) [0|15] "raw"  MDS
 SG_ IsoTpFrameType M : 7|4@0+ (1,0) [0|15] ""  MDS

BO_ 1609 BSI_DiagResponse_9: 8 BSI
 SG_ FlowPadding5 m3 : 63|8@0+ (1,0) [0|255] "raw"  MDS
 SG_ FirstData6 m1 : 63|8@0+ (1,0) [0|255] "raw"  MDS
 SG_ UnknownData7 m4 : 63|8@0+ (1,0) [0|255] "raw"  MDS
 SG_ ConsecutiveData7 m2 : 63|8@0+ (1,0) [0|255] "raw"  MDS
 SG_ SingleData7 m0 : 63|8@0+ (1,0) [0|255] "raw"  MDS
 SG_ FlowPadding4 m3 : 55|8@0+ (1,0) [0|255] "raw"  MDS
 SG_ FirstData5 m1 : 55|8@0+ (1,0) [0|255] "raw"  MDS
 SG_ UnknownData6 m4 : 55|8@0+ (1,0) [0|255] "raw"  MDS
 SG_ ConsecutiveData6 m2 : 55|8@0+ (1,0) [0|255] "raw"  MDS
 SG_ SingleData6 m0 : 55|8@0+ (1,0) [0|255] "raw"  MDS
 SG_ FlowPadding3 m3 : 47|8@0+ (1,0) [0|255] "raw"  MDS
 SG_ FirstData4 m1 : 47|8@0+ (1,0) [0|255] "raw"  MDS
 SG_ UnknownData5 m4 : 47|8@0+ (1,0) [0|255] "raw"  MDS
 SG_ ConsecutiveData5 m2 : 47|8@0+ (1,0) [0|255] "raw"  MDS
 SG_ SingleData5 m0 : 47|8@0+ (1,0) [0|255] "raw"  MDS
 SG_ FlowPadding2 m3 : 39|8@0+ (1,0) [0|255] "raw"  MDS
 SG_ FirstData3 m1 : 39|8@0+ (1,0) [0|255] "raw"  MDS
 SG_ UnknownData4 m4 : 39|8@0+ (1,0) [0|255] "raw"  MDS
 SG_ ConsecutiveData4 m2 : 39|8@0+ (1,0) [0|255] "raw"  MDS
 SG_ SingleData4 m0 : 39|8@0+ (1,0) [0|255] "raw"  MDS
 SG_ FlowPadding1 m3 : 31|8@0+ (1,0) [0|255] "raw"  MDS
 SG_ FirstData2 m1 : 31|8@0+ (1,0) [0|255] "raw"  MDS
 SG_ UnknownData3 m4 : 31|8@0+ (1,0) [0|255] "raw"  MDS
 SG_ ConsecutiveData3 m2 : 31|8@0+ (1,0) [0|255] "raw"  MDS
 SG_ SingleData3 m0 : 31|8@0+ (1,0) [0|255] "raw"  MDS
 SG_ FirstData1 m1 : 23|8@0+ (1,0) [0|255] "raw"  MDS
 SG_ UnknownData2 m4 : 23|8@0+ (1,0) [0|255] "raw"  MDS
 SG_ ConsecutiveData2 m2 : 23|8@0+ (1,0) [0|255] "raw"  MDS
 SG_ SingleData2 m0 : 23|8@0+ (1,0) [0|255] "raw"  MDS
 SG_ SeparationTimeRaw m3 : 23|8@0+ (1,0) [0|255] "raw"  MDS
 SG_ UnknownData1 m4 : 15|8@0+ (1,0) [0|255] "raw"  MDS
 SG_ ConsecutiveData1 m2 : 15|8@0+ (1,0) [0|255] "raw"  MDS
 SG_ SingleData1 m0 : 15|8@0+ (1,0) [0|255] "raw"  MDS
 SG_ BlockSize m3 : 15|8@0+ (1,0) [0|255] "raw"  MDS
 SG_ UnknownPciLow m4 : 3|4@0+ (1,0) [0|15] "raw"  MDS
 SG_ FlowStatus m3 : 3|4@0+ (1,0) [0|15] "raw"  MDS
 SG_ ConsecutiveSequence m2 : 3|4@0+ (1,0) [0|15] "raw"  MDS
 SG_ FirstFrameLength m1 : 3|12@0+ (1,0) [0|4095] "raw"  MDS
 SG_ SingleFrameLength m0 : 3|4@0+ (1,0) [0|15] "raw"  MDS
 SG_ IsoTpFrameType M : 7|4@0+ (1,0) [0|15] ""  MDS

BO_ 1610 BSI_DiagResponse_10: 8 BSI
 SG_ FlowPadding5 m3 : 63|8@0+ (1,0) [0|255] "raw"  MDS
 SG_ FirstData6 m1 : 63|8@0+ (1,0) [0|255] "raw"  MDS
 SG_ UnknownData7 m4 : 63|8@0+ (1,0) [0|255] "raw"  MDS
 SG_ ConsecutiveData7 m2 : 63|8@0+ (1,0) [0|255] "raw"  MDS
 SG_ SingleData7 m0 : 63|8@0+ (1,0) [0|255] "raw"  MDS
 SG_ FlowPadding4 m3 : 55|8@0+ (1,0) [0|255] "raw"  MDS
 SG_ FirstData5 m1 : 55|8@0+ (1,0) [0|255] "raw"  MDS
 SG_ UnknownData6 m4 : 55|8@0+ (1,0) [0|255] "raw"  MDS
 SG_ ConsecutiveData6 m2 : 55|8@0+ (1,0) [0|255] "raw"  MDS
 SG_ SingleData6 m0 : 55|8@0+ (1,0) [0|255] "raw"  MDS
 SG_ FlowPadding3 m3 : 47|8@0+ (1,0) [0|255] "raw"  MDS
 SG_ FirstData4 m1 : 47|8@0+ (1,0) [0|255] "raw"  MDS
 SG_ UnknownData5 m4 : 47|8@0+ (1,0) [0|255] "raw"  MDS
 SG_ ConsecutiveData5 m2 : 47|8@0+ (1,0) [0|255] "raw"  MDS
 SG_ SingleData5 m0 : 47|8@0+ (1,0) [0|255] "raw"  MDS
 SG_ FlowPadding2 m3 : 39|8@0+ (1,0) [0|255] "raw"  MDS
 SG_ FirstData3 m1 : 39|8@0+ (1,0) [0|255] "raw"  MDS
 SG_ UnknownData4 m4 : 39|8@0+ (1,0) [0|255] "raw"  MDS
 SG_ ConsecutiveData4 m2 : 39|8@0+ (1,0) [0|255] "raw"  MDS
 SG_ SingleData4 m0 : 39|8@0+ (1,0) [0|255] "raw"  MDS
 SG_ FlowPadding1 m3 : 31|8@0+ (1,0) [0|255] "raw"  MDS
 SG_ FirstData2 m1 : 31|8@0+ (1,0) [0|255] "raw"  MDS
 SG_ UnknownData3 m4 : 31|8@0+ (1,0) [0|255] "raw"  MDS
 SG_ ConsecutiveData3 m2 : 31|8@0+ (1,0) [0|255] "raw"  MDS
 SG_ SingleData3 m0 : 31|8@0+ (1,0) [0|255] "raw"  MDS
 SG_ FirstData1 m1 : 23|8@0+ (1,0) [0|255] "raw"  MDS
 SG_ UnknownData2 m4 : 23|8@0+ (1,0) [0|255] "raw"  MDS
 SG_ ConsecutiveData2 m2 : 23|8@0+ (1,0) [0|255] "raw"  MDS
 SG_ SingleData2 m0 : 23|8@0+ (1,0) [0|255] "raw"  MDS
 SG_ SeparationTimeRaw m3 : 23|8@0+ (1,0) [0|255] "raw"  MDS
 SG_ UnknownData1 m4 : 15|8@0+ (1,0) [0|255] "raw"  MDS
 SG_ ConsecutiveData1 m2 : 15|8@0+ (1,0) [0|255] "raw"  MDS
 SG_ SingleData1 m0 : 15|8@0+ (1,0) [0|255] "raw"  MDS
 SG_ BlockSize m3 : 15|8@0+ (1,0) [0|255] "raw"  MDS
 SG_ UnknownPciLow m4 : 3|4@0+ (1,0) [0|15] "raw"  MDS
 SG_ FlowStatus m3 : 3|4@0+ (1,0) [0|15] "raw"  MDS
 SG_ ConsecutiveSequence m2 : 3|4@0+ (1,0) [0|15] "raw"  MDS
 SG_ FirstFrameLength m1 : 3|12@0+ (1,0) [0|4095] "raw"  MDS
 SG_ SingleFrameLength m0 : 3|4@0+ (1,0) [0|15] "raw"  MDS
 SG_ IsoTpFrameType M : 7|4@0+ (1,0) [0|15] ""  MDS

BO_TX_BU_ 1341 : AMPLI,BTEL;
BO_TX_BU_ 1504 : RAD,ICSV;
BO_TX_BU_ 1508 : ICSV,BTEL,OVIP;
CM_ BO_ 1330 "DATABASE_CANDIDATE: physical interpretation unverified; capture/layout evidence reported separately. INFO-DIV CAN, 125000 bit/s; CAN ID 0x532. PSA-RE title: HYBRID_BATTERY_DATA_2. Network supervision: diagnostic session, network management state and communication fault counters Source: https://github.com/prototux/PSA-RE/blob/67f7581e7622410efdbb29c7eda3b86982b9b450/buses/AEE2010.full/LS.INFO-DIV/532.yml. Source sender alternatives: MATT; physical TX/gateway forwarding not verified. ";
CM_ SG_ 1330 Unused4 "DATABASE_CANDIDATE: physical interpretation unverified; capture/layout evidence reported separately. PSA-RE bits 8.7-8.0. ";
CM_ SG_ 1330 Unused3 "DATABASE_CANDIDATE: physical interpretation unverified; capture/layout evidence reported separately. PSA-RE bits 7.7-7.0. ";
CM_ SG_ 1330 AbsentMatt "DATABASE_CANDIDATE: physical interpretation unverified; capture/layout evidence reported separately. PSA-RE bits 6.7-6.0. Absent computer(s) supervised by the display matrix. Upstream default raw=0 (not necessarily valid data).";
CM_ SG_ 1330 PfhmComLossCounter "DATABASE_CANDIDATE: physical interpretation unverified; capture/layout evidence reported separately. PSA-RE bits 5.7-5.0. Rolling counter incremented by 1 at each \"communication loss\" transition, reset to 0 at initialization. Upstream default raw=0 (not necessarily valid data).";
CM_ SG_ 1330 PfhmBusOffCounter "DATABASE_CANDIDATE: physical interpretation unverified; capture/layout evidence reported separately. PSA-RE bits 4.7-4.0. Rolling counter incremented by 1 at each \"bus-off\" fault, reset to 0 at initialization. Upstream default raw=0 (not necessarily valid data).";
CM_ SG_ 1330 PfhmNAsCounter "DATABASE_CANDIDATE: physical interpretation unverified; capture/layout evidence reported separately. PSA-RE bits 3.7-3.0. Rolling counter incremented at each \"message not sent\" detection, after 1 attempt on the N_As timeout; reset to 0 at initialization. Upstream default raw=0 (not necessarily valid data).";
CM_ SG_ 1330 NerrFaultCounterValue "DATABASE_CANDIDATE: physical interpretation unverified; capture/layout evidence reported separately. PSA-RE bits 2.7-2.0. Value of the NERR fault counter for the line diagnosis. Upstream default raw=0 (not necessarily valid data).";
CM_ SG_ 1330 Unused2 "DATABASE_CANDIDATE: physical interpretation unverified; capture/layout evidence reported separately. PSA-RE bits 1.2-1.0. ";
CM_ SG_ 1330 SupervisionTaskState "DATABASE_CANDIDATE: physical interpretation unverified; capture/layout evidence reported separately. PSA-RE bits 1.3. Network supervision task state. Upstream default raw=0 (not necessarily valid data).";
CM_ SG_ 1330 NerrBitStatus "DATABASE_CANDIDATE: physical interpretation unverified; capture/layout evidence reported separately. PSA-RE bits 1.4. NERR (network error) bit status. Upstream default raw=0 (not necessarily valid data).";
CM_ SG_ 1330 ComLossFault "DATABASE_CANDIDATE: physical interpretation unverified; capture/layout evidence reported separately. PSA-RE bits 1.5. Communication loss fault. Upstream default raw=0 (not necessarily valid data).";
CM_ SG_ 1330 Unused1 "DATABASE_CANDIDATE: physical interpretation unverified; capture/layout evidence reported separately. PSA-RE bits 1.7-1.6. ";
CM_ BO_ 1331 "DATABASE_CANDIDATE: physical interpretation unverified; capture/layout evidence reported separately. INFO-DIV CAN, 125000 bit/s; CAN ID 0x533. PSA-RE title: AVP_SUPERVISION. Network supervision: diagnostic session, network management state and communication fault counters Source: https://github.com/prototux/PSA-RE/blob/67f7581e7622410efdbb29c7eda3b86982b9b450/buses/AEE2010.full/LS.INFO-DIV/533.yml. Source sender alternatives: AVP; physical TX/gateway forwarding not verified. ";
CM_ SG_ 1331 Unused4 "DATABASE_CANDIDATE: physical interpretation unverified; capture/layout evidence reported separately. PSA-RE bits 8.7-8.0. ";
CM_ SG_ 1331 Unused3 "DATABASE_CANDIDATE: physical interpretation unverified; capture/layout evidence reported separately. PSA-RE bits 7.7-7.0. ";
CM_ SG_ 1331 AbsentAvp "DATABASE_CANDIDATE: physical interpretation unverified; capture/layout evidence reported separately. PSA-RE bits 6.7-6.0. Absent computer(s) supervised by the parking assistance system. Upstream default raw=0 (not necessarily valid data).";
CM_ SG_ 1331 PfhmComLossCounter "DATABASE_CANDIDATE: physical interpretation unverified; capture/layout evidence reported separately. PSA-RE bits 5.7-5.0. Rolling counter incremented by 1 at each \"communication loss\" transition, reset to 0 at initialization. Upstream default raw=0 (not necessarily valid data).";
CM_ SG_ 1331 PfhmBusOffCounter "DATABASE_CANDIDATE: physical interpretation unverified; capture/layout evidence reported separately. PSA-RE bits 4.7-4.0. Rolling counter incremented by 1 at each \"bus-off\" fault, reset to 0 at initialization. Upstream default raw=0 (not necessarily valid data).";
CM_ SG_ 1331 PfhmNAsCounter "DATABASE_CANDIDATE: physical interpretation unverified; capture/layout evidence reported separately. PSA-RE bits 3.7-3.0. Rolling counter incremented at each \"message not sent\" detection, after 1 attempt on the N_As timeout; reset to 0 at initialization. Upstream default raw=0 (not necessarily valid data).";
CM_ SG_ 1331 NerrFaultCounterValue "DATABASE_CANDIDATE: physical interpretation unverified; capture/layout evidence reported separately. PSA-RE bits 2.7-2.0. Value of the NERR fault counter for the line diagnosis. Upstream default raw=0 (not necessarily valid data).";
CM_ SG_ 1331 Unused2 "DATABASE_CANDIDATE: physical interpretation unverified; capture/layout evidence reported separately. PSA-RE bits 1.2-1.0. ";
CM_ SG_ 1331 SupervisionTaskState "DATABASE_CANDIDATE: physical interpretation unverified; capture/layout evidence reported separately. PSA-RE bits 1.3. Network supervision task state. Upstream default raw=0 (not necessarily valid data).";
CM_ SG_ 1331 NerrBitStatus "DATABASE_CANDIDATE: physical interpretation unverified; capture/layout evidence reported separately. PSA-RE bits 1.4. NERR (network error) bit status. Upstream default raw=0 (not necessarily valid data).";
CM_ SG_ 1331 ComLossFault "DATABASE_CANDIDATE: physical interpretation unverified; capture/layout evidence reported separately. PSA-RE bits 1.5. Communication loss fault. Upstream default raw=0 (not necessarily valid data).";
CM_ SG_ 1331 Unused1 "DATABASE_CANDIDATE: physical interpretation unverified; capture/layout evidence reported separately. PSA-RE bits 1.7-1.6. ";
CM_ BO_ 1334 "DATABASE_CANDIDATE: physical interpretation unverified; capture/layout evidence reported separately. INFO-DIV CAN, 125000 bit/s; CAN ID 0x536. PSA-RE title: BTT_NETWORK_SUPERVISION. Network supervision status of the BTT module: bus-off, communication loss and diagnostic session counters. Source: https://github.com/prototux/PSA-RE/blob/67f7581e7622410efdbb29c7eda3b86982b9b450/buses/AEE2010.full/LS.INFO-DIV/536.yml. Source sender alternatives: BSG; physical TX/gateway forwarding not verified. ";
CM_ SG_ 1334 Unused4 "DATABASE_CANDIDATE: physical interpretation unverified; capture/layout evidence reported separately. PSA-RE bits 8.7-8.0. ";
CM_ SG_ 1334 Unused3 "DATABASE_CANDIDATE: physical interpretation unverified; capture/layout evidence reported separately. PSA-RE bits 7.7-7.0. ";
CM_ SG_ 1334 AbsentBtt "DATABASE_CANDIDATE: physical interpretation unverified; capture/layout evidence reported separately. PSA-RE bits 6.7-6.0. Absent computer(s) supervised by BTT.";
CM_ SG_ 1334 PfhmComLossCounter "DATABASE_CANDIDATE: physical interpretation unverified; capture/layout evidence reported separately. PSA-RE bits 5.7-5.0. Rolling counter incremented by 1 at each \"communication loss\" transition, reset to 0 at initialization. Upstream default raw=0 (not necessarily valid data).";
CM_ SG_ 1334 PfhmBusOffCounter "DATABASE_CANDIDATE: physical interpretation unverified; capture/layout evidence reported separately. PSA-RE bits 4.7-4.0. Rolling counter incremented by 1 at each \"bus-off\" fault, reset to 0 at initialization. Upstream default raw=0 (not necessarily valid data).";
CM_ SG_ 1334 PfhmNAsCounter "DATABASE_CANDIDATE: physical interpretation unverified; capture/layout evidence reported separately. PSA-RE bits 3.7-3.0. Rolling counter incremented at each \"message not sent\" detection, after 1 attempt on the N_As timeout; reset to 0 at initialization. Upstream default raw=0 (not necessarily valid data).";
CM_ SG_ 1334 NerrFaultCounterValue "DATABASE_CANDIDATE: physical interpretation unverified; capture/layout evidence reported separately. PSA-RE bits 2.7-2.0. Value of the NERR fault counter for the line diagnosis. Upstream default raw=0 (not necessarily valid data).";
CM_ SG_ 1334 DiagnosticSessionActive "DATABASE_CANDIDATE: physical interpretation unverified; capture/layout evidence reported separately. PSA-RE bits 1.0. System currently performing a diagnostic activity. Upstream default raw=0 (not necessarily valid data).";
CM_ SG_ 1334 UnderDiagnosisSession "DATABASE_CANDIDATE: physical interpretation unverified; capture/layout evidence reported separately. PSA-RE bits 1.1. System currently under a diagnostic session. Upstream default raw=0 (not necessarily valid data).";
CM_ SG_ 1334 Unused2 "DATABASE_CANDIDATE: physical interpretation unverified; capture/layout evidence reported separately. PSA-RE bits 1.2. ";
CM_ SG_ 1334 SupervisionTaskState "DATABASE_CANDIDATE: physical interpretation unverified; capture/layout evidence reported separately. PSA-RE bits 1.3. Network supervision task state. Upstream default raw=0 (not necessarily valid data).";
CM_ SG_ 1334 NerrBitStatus "DATABASE_CANDIDATE: physical interpretation unverified; capture/layout evidence reported separately. PSA-RE bits 1.4. NERR (network error) bit status. Upstream default raw=0 (not necessarily valid data).";
CM_ SG_ 1334 ComLossFault "DATABASE_CANDIDATE: physical interpretation unverified; capture/layout evidence reported separately. PSA-RE bits 1.5. Communication loss fault. Upstream default raw=0 (not necessarily valid data).";
CM_ SG_ 1334 Unused1 "DATABASE_CANDIDATE: physical interpretation unverified; capture/layout evidence reported separately. PSA-RE bits 1.7-1.6. ";
CM_ BO_ 1339 "DATABASE_CANDIDATE: physical interpretation unverified; capture/layout evidence reported separately. INFO-DIV CAN, 125000 bit/s; CAN ID 0x53B. PSA-RE title: FMUX_SUPERVISION. Network supervision: diagnostic session, network management state and communication fault counters Source: https://github.com/prototux/PSA-RE/blob/67f7581e7622410efdbb29c7eda3b86982b9b450/buses/AEE2010.full/LS.INFO-DIV/53B.yml. Source sender alternatives: FMUX; physical TX/gateway forwarding not verified. Observed 587 frames in info_apka.csv,info_buzeni_obc.csv,info_charging.csv,info_standby.csv,info_start_jizda.csv,infocan.csv; DLCs [8]. ";
CM_ SG_ 1339 Unused4 "DATABASE_CANDIDATE: physical interpretation unverified; capture/layout evidence reported separately. PSA-RE bits 8.7-8.0. ";
CM_ SG_ 1339 Unused3 "DATABASE_CANDIDATE: physical interpretation unverified; capture/layout evidence reported separately. PSA-RE bits 7.7-7.0. ";
CM_ SG_ 1339 AbsentFmux1 "DATABASE_CANDIDATE: physical interpretation unverified; capture/layout evidence reported separately. PSA-RE bits 6.7-6.0. Absent computer(s) supervised by the MUX front panel. Upstream default raw=0 (not necessarily valid data).";
CM_ SG_ 1339 PfhmComLossCounter "DATABASE_CANDIDATE: physical interpretation unverified; capture/layout evidence reported separately. PSA-RE bits 5.7-5.0. Rolling counter incremented by 1 at each \"communication loss\" transition, reset to 0 at initialization. Upstream default raw=0 (not necessarily valid data).";
CM_ SG_ 1339 PfhmBusOffCounter "DATABASE_CANDIDATE: physical interpretation unverified; capture/layout evidence reported separately. PSA-RE bits 4.7-4.0. Rolling counter incremented by 1 at each \"bus-off\" fault, reset to 0 at initialization. Upstream default raw=0 (not necessarily valid data).";
CM_ SG_ 1339 PfhmNAsCounter "DATABASE_CANDIDATE: physical interpretation unverified; capture/layout evidence reported separately. PSA-RE bits 3.7-3.0. Rolling counter incremented at each \"message not sent\" detection, after 1 attempt on the N_As timeout; reset to 0 at initialization. Upstream default raw=0 (not necessarily valid data).";
CM_ SG_ 1339 NerrFaultCounterValue "DATABASE_CANDIDATE: physical interpretation unverified; capture/layout evidence reported separately. PSA-RE bits 2.7-2.0. Value of the NERR fault counter for the line diagnosis. Upstream default raw=0 (not necessarily valid data).";
CM_ SG_ 1339 Unused2 "DATABASE_CANDIDATE: physical interpretation unverified; capture/layout evidence reported separately. PSA-RE bits 1.2-1.0. ";
CM_ SG_ 1339 SupervisionTaskState "DATABASE_CANDIDATE: physical interpretation unverified; capture/layout evidence reported separately. PSA-RE bits 1.3. Network supervision task state. Upstream default raw=0 (not necessarily valid data).";
CM_ SG_ 1339 NerrBitStatus "DATABASE_CANDIDATE: physical interpretation unverified; capture/layout evidence reported separately. PSA-RE bits 1.4. NERR (network error) bit status. Upstream default raw=0 (not necessarily valid data).";
CM_ SG_ 1339 ComLossFault "DATABASE_CANDIDATE: physical interpretation unverified; capture/layout evidence reported separately. PSA-RE bits 1.5. Communication loss fault. Upstream default raw=0 (not necessarily valid data).";
CM_ SG_ 1339 Unused1 "DATABASE_CANDIDATE: physical interpretation unverified; capture/layout evidence reported separately. PSA-RE bits 1.7-1.6. ";
CM_ BO_ 1340 "DATABASE_CANDIDATE: physical interpretation unverified; capture/layout evidence reported separately. INFO-DIV CAN, 125000 bit/s; CAN ID 0x53C. PSA-RE title: MDS_SUPERVISION. Network supervision: diagnostic session, network management state and communication fault counters Source: https://github.com/prototux/PSA-RE/blob/67f7581e7622410efdbb29c7eda3b86982b9b450/buses/AEE2010.full/LS.INFO-DIV/53C.yml. Source sender alternatives: MDS; physical TX/gateway forwarding not verified. Observed 587 frames in info_apka.csv,info_buzeni_obc.csv,info_charging.csv,info_standby.csv,info_start_jizda.csv,infocan.csv; DLCs [8]. ";
CM_ SG_ 1340 Unused4 "DATABASE_CANDIDATE: physical interpretation unverified; capture/layout evidence reported separately. PSA-RE bits 8.7-8.0. ";
CM_ SG_ 1340 Unused3 "DATABASE_CANDIDATE: physical interpretation unverified; capture/layout evidence reported separately. PSA-RE bits 7.7-7.0. ";
CM_ SG_ 1340 AbsentMds "DATABASE_CANDIDATE: physical interpretation unverified; capture/layout evidence reported separately. PSA-RE bits 6.7-6.0. Absent computer(s) supervised by MDS. Upstream default raw=0 (not necessarily valid data).";
CM_ SG_ 1340 PfhmComLossCounter "DATABASE_CANDIDATE: physical interpretation unverified; capture/layout evidence reported separately. PSA-RE bits 5.7-5.0. Rolling counter incremented by 1 at each \"communication loss\" transition, reset to 0 at initialization. Upstream default raw=0 (not necessarily valid data).";
CM_ SG_ 1340 PfhmBusOffCounter "DATABASE_CANDIDATE: physical interpretation unverified; capture/layout evidence reported separately. PSA-RE bits 4.7-4.0. Rolling counter incremented by 1 at each \"bus-off\" fault, reset to 0 at initialization. Upstream default raw=0 (not necessarily valid data).";
CM_ SG_ 1340 PfhmNAsCounter "DATABASE_CANDIDATE: physical interpretation unverified; capture/layout evidence reported separately. PSA-RE bits 3.7-3.0. Rolling counter incremented at each \"message not sent\" detection, after 1 attempt on the N_As timeout; reset to 0 at initialization. Upstream default raw=0 (not necessarily valid data).";
CM_ SG_ 1340 NerrFaultCounterValue "DATABASE_CANDIDATE: physical interpretation unverified; capture/layout evidence reported separately. PSA-RE bits 2.7-2.0. Value of the NERR fault counter for the line diagnosis. Upstream default raw=0 (not necessarily valid data).";
CM_ SG_ 1340 DiagnosticSessionActive "DATABASE_CANDIDATE: physical interpretation unverified; capture/layout evidence reported separately. PSA-RE bits 1.0. System currently performing a diagnostic activity. Upstream default raw=0 (not necessarily valid data).";
CM_ SG_ 1340 Unused2 "DATABASE_CANDIDATE: physical interpretation unverified; capture/layout evidence reported separately. PSA-RE bits 1.2-1.1. ";
CM_ SG_ 1340 SupervisionTaskState "DATABASE_CANDIDATE: physical interpretation unverified; capture/layout evidence reported separately. PSA-RE bits 1.3. Network supervision task state. Upstream default raw=0 (not necessarily valid data).";
CM_ SG_ 1340 NerrBitStatus "DATABASE_CANDIDATE: physical interpretation unverified; capture/layout evidence reported separately. PSA-RE bits 1.4. NERR (network error) bit status. Upstream default raw=0 (not necessarily valid data).";
CM_ SG_ 1340 ComLossFault "DATABASE_CANDIDATE: physical interpretation unverified; capture/layout evidence reported separately. PSA-RE bits 1.5. Communication loss fault. Upstream default raw=0 (not necessarily valid data).";
CM_ SG_ 1340 Unused1 "DATABASE_CANDIDATE: physical interpretation unverified; capture/layout evidence reported separately. PSA-RE bits 1.7-1.6. ";
CM_ BO_ 1341 "DATABASE_CANDIDATE: physical interpretation unverified; capture/layout evidence reported separately. INFO-DIV CAN, 125000 bit/s; CAN ID 0x53D. PSA-RE title: AMPLI_SUPERVISION. Network supervision: diagnostic session, network management state and communication fault counters Source: https://github.com/prototux/PSA-RE/blob/67f7581e7622410efdbb29c7eda3b86982b9b450/buses/AEE2010.full/LS.INFO-DIV/53D.yml. Source sender alternatives: AMPLI,BTEL; physical TX/gateway forwarding not verified. ";
CM_ SG_ 1341 Unused5 "DATABASE_CANDIDATE: physical interpretation unverified; capture/layout evidence reported separately. PSA-RE bits 8.5-8.0. ";
CM_ SG_ 1341 Unused4 "DATABASE_CANDIDATE: physical interpretation unverified; capture/layout evidence reported separately. PSA-RE bits 7.3-8.6. ";
CM_ SG_ 1341 Unused3 "DATABASE_CANDIDATE: physical interpretation unverified; capture/layout evidence reported separately. PSA-RE bits 6.1-7.4. ";
CM_ SG_ 1341 AbsentAmpli "DATABASE_CANDIDATE: physical interpretation unverified; capture/layout evidence reported separately. PSA-RE bits 6.7-6.2. Absent computer(s) supervised by the amplifier. Upstream default raw=0 (not necessarily valid data).";
CM_ SG_ 1341 PfhmComLossCounter "DATABASE_CANDIDATE: physical interpretation unverified; capture/layout evidence reported separately. PSA-RE bits 5.7-5.0. Rolling counter incremented by 1 at each \"communication loss\" transition, reset to 0 at initialization. Upstream default raw=0 (not necessarily valid data).";
CM_ SG_ 1341 PfhmBusOffCounter "DATABASE_CANDIDATE: physical interpretation unverified; capture/layout evidence reported separately. PSA-RE bits 4.7-4.0. Rolling counter incremented by 1 at each \"bus-off\" fault, reset to 0 at initialization. Upstream default raw=0 (not necessarily valid data).";
CM_ SG_ 1341 PfhmNAsCounter "DATABASE_CANDIDATE: physical interpretation unverified; capture/layout evidence reported separately. PSA-RE bits 3.7-3.0. Rolling counter incremented at each \"message not sent\" detection, after 1 attempt on the N_As timeout; reset to 0 at initialization. Upstream default raw=0 (not necessarily valid data).";
CM_ SG_ 1341 NerrFaultCounterValue "DATABASE_CANDIDATE: physical interpretation unverified; capture/layout evidence reported separately. PSA-RE bits 2.7-2.0. Value of the NERR fault counter for the line diagnosis. Upstream default raw=0 (not necessarily valid data).";
CM_ SG_ 1341 DiagnosticSessionActive "DATABASE_CANDIDATE: physical interpretation unverified; capture/layout evidence reported separately. PSA-RE bits 1.0. System currently performing a diagnostic activity. Upstream default raw=0 (not necessarily valid data).";
CM_ SG_ 1341 UnderDiagnosisSession "DATABASE_CANDIDATE: physical interpretation unverified; capture/layout evidence reported separately. PSA-RE bits 1.1. System currently under a diagnostic session. Upstream default raw=0 (not necessarily valid data).";
CM_ SG_ 1341 Unused2 "DATABASE_CANDIDATE: physical interpretation unverified; capture/layout evidence reported separately. PSA-RE bits 1.2. ";
CM_ SG_ 1341 SupervisionTaskState "DATABASE_CANDIDATE: physical interpretation unverified; capture/layout evidence reported separately. PSA-RE bits 1.3. Network supervision task state. Upstream default raw=0 (not necessarily valid data).";
CM_ SG_ 1341 NerrBitStatus "DATABASE_CANDIDATE: physical interpretation unverified; capture/layout evidence reported separately. PSA-RE bits 1.4. NERR (network error) bit status. Upstream default raw=0 (not necessarily valid data).";
CM_ SG_ 1341 ComLossFault "DATABASE_CANDIDATE: physical interpretation unverified; capture/layout evidence reported separately. PSA-RE bits 1.5. Communication loss fault. Upstream default raw=0 (not necessarily valid data).";
CM_ SG_ 1341 Unused1 "DATABASE_CANDIDATE: physical interpretation unverified; capture/layout evidence reported separately. PSA-RE bits 1.7-1.6. ";
CM_ BO_ 1473 "DATABASE_CANDIDATE: physical interpretation unverified; capture/layout evidence reported separately. INFO-DIV CAN, 125000 bit/s; CAN ID 0x5C1. PSA-RE title: BML_VERSION. Software and calibration identification of the ECU, sent when the network switches from wake-up to normal state. Source: https://github.com/prototux/PSA-RE/blob/67f7581e7622410efdbb29c7eda3b86982b9b450/buses/AEE2010.full/LS.INFO-DIV/5C1.yml. Source sender alternatives: SDCM; physical TX/gateway forwarding not verified. Observed 12 frames in info_apka.csv,info_buzeni_obc.csv,info_charging.csv,infocan.csv; DLCs [8]. ";
CM_ SG_ 1473 EditionNumber "DATABASE_CANDIDATE: physical interpretation unverified; capture/layout evidence reported separately. PSA-RE bits 8.7-8.0. Edition number. Raw invalid=255; numeric DBC decoders may still scale it: check raw before use.";
CM_ SG_ 1473 GenerationNumberDigit2 "DATABASE_CANDIDATE: physical interpretation unverified; capture/layout evidence reported separately. PSA-RE bits 7.3-7.0. Generation number (2nd digit).";
CM_ SG_ 1473 GenerationNumberDigit1 "DATABASE_CANDIDATE: physical interpretation unverified; capture/layout evidence reported separately. PSA-RE bits 7.7-7.4. Generation number (1st digit).";
CM_ SG_ 1473 SoftwareIdentification "DATABASE_CANDIDATE: physical interpretation unverified; capture/layout evidence reported separately. PSA-RE bits 5.7-6.0. Characterizes the software identification. Raw invalid=65535; numeric DBC decoders may still scale it: check raw before use.";
CM_ SG_ 1473 SoftwareVersionYear "DATABASE_CANDIDATE: physical interpretation unverified; capture/layout evidence reported separately. PSA-RE bits 4.7-4.0. Software version, year.";
CM_ SG_ 1473 SoftwareVersionMonth "DATABASE_CANDIDATE: physical interpretation unverified; capture/layout evidence reported separately. PSA-RE bits 3.7-3.0. Software version, month.";
CM_ SG_ 1473 SoftwareVersionDay "DATABASE_CANDIDATE: physical interpretation unverified; capture/layout evidence reported separately. PSA-RE bits 2.7-2.0. Software version, day.";
CM_ SG_ 1473 EcuNumber "DATABASE_CANDIDATE: physical interpretation unverified; capture/layout evidence reported separately. PSA-RE bits 1.7-1.0. ECU number. Raw invalid=255; numeric DBC decoders may still scale it: check raw before use.";
CM_ BO_ 1484 "DATABASE_CANDIDATE: physical interpretation unverified; capture/layout evidence reported separately. INFO-DIV CAN, 125000 bit/s; CAN ID 0x5CC. PSA-RE title: BVN_SUPERVISION. Software and calibration version identification of the sending ECU Source: https://github.com/prototux/PSA-RE/blob/67f7581e7622410efdbb29c7eda3b86982b9b450/buses/AEE2010.full/LS.INFO-DIV/5CC.yml. Source sender alternatives: CRT; physical TX/gateway forwarding not verified. ";
CM_ SG_ 1484 EditionNumber "DATABASE_CANDIDATE: physical interpretation unverified; capture/layout evidence reported separately. PSA-RE bits 8.7-8.0. Edition number. Raw invalid=255; numeric DBC decoders may still scale it: check raw before use.";
CM_ SG_ 1484 GenerationNumberDigit2 "DATABASE_CANDIDATE: physical interpretation unverified; capture/layout evidence reported separately. PSA-RE bits 7.3-7.0. Generation number (2nd digit).";
CM_ SG_ 1484 GenerationNumberDigit1 "DATABASE_CANDIDATE: physical interpretation unverified; capture/layout evidence reported separately. PSA-RE bits 7.7-7.4. Generation number (1st digit).";
CM_ SG_ 1484 SoftwareIdentification "DATABASE_CANDIDATE: physical interpretation unverified; capture/layout evidence reported separately. PSA-RE bits 5.7-6.0. Characterizes the software identification. Raw invalid=65535; numeric DBC decoders may still scale it: check raw before use.";
CM_ SG_ 1484 SoftwareVersionYear "DATABASE_CANDIDATE: physical interpretation unverified; capture/layout evidence reported separately. PSA-RE bits 4.7-4.0. Software version, year.";
CM_ SG_ 1484 SoftwareVersionMonth "DATABASE_CANDIDATE: physical interpretation unverified; capture/layout evidence reported separately. PSA-RE bits 3.7-3.0. Software version, month.";
CM_ SG_ 1484 SoftwareVersionDay "DATABASE_CANDIDATE: physical interpretation unverified; capture/layout evidence reported separately. PSA-RE bits 2.7-2.0. Software version, day.";
CM_ SG_ 1484 EcuNumber "DATABASE_CANDIDATE: physical interpretation unverified; capture/layout evidence reported separately. PSA-RE bits 1.7-1.0. ECU number. Raw invalid=255; numeric DBC decoders may still scale it: check raw before use.";
CM_ BO_ 1490 "DATABASE_CANDIDATE: physical interpretation unverified; capture/layout evidence reported separately. INFO-DIV CAN, 125000 bit/s; CAN ID 0x5D2. PSA-RE title: HYBRID_CONTROL_REQUESTS. Software and calibration version identification of the sending ECU Source: https://github.com/prototux/PSA-RE/blob/67f7581e7622410efdbb29c7eda3b86982b9b450/buses/AEE2010.full/LS.INFO-DIV/5D2.yml. Source sender alternatives: BSI; physical TX/gateway forwarding not verified. Observed 12 frames in info_apka.csv,info_buzeni_obc.csv,info_charging.csv,infocan.csv; DLCs [8]. ";
CM_ SG_ 1490 EditionNumber "DATABASE_CANDIDATE: physical interpretation unverified; capture/layout evidence reported separately. PSA-RE bits 8.7-8.0. Edition number. Raw invalid=255; numeric DBC decoders may still scale it: check raw before use.";
CM_ SG_ 1490 GenerationNumberDigit2 "DATABASE_CANDIDATE: physical interpretation unverified; capture/layout evidence reported separately. PSA-RE bits 7.3-7.0. Generation number (2nd digit).";
CM_ SG_ 1490 GenerationNumberDigit1 "DATABASE_CANDIDATE: physical interpretation unverified; capture/layout evidence reported separately. PSA-RE bits 7.7-7.4. Generation number (1st digit).";
CM_ SG_ 1490 SoftwareIdentification "DATABASE_CANDIDATE: physical interpretation unverified; capture/layout evidence reported separately. PSA-RE bits 5.7-6.0. Characterizes the software identification. Raw invalid=65535; numeric DBC decoders may still scale it: check raw before use.";
CM_ SG_ 1490 SoftwareVersionYear "DATABASE_CANDIDATE: physical interpretation unverified; capture/layout evidence reported separately. PSA-RE bits 4.7-4.0. Software version, year.";
CM_ SG_ 1490 SoftwareVersionMonth "DATABASE_CANDIDATE: physical interpretation unverified; capture/layout evidence reported separately. PSA-RE bits 3.7-3.0. Software version, month.";
CM_ SG_ 1490 SoftwareVersionDay "DATABASE_CANDIDATE: physical interpretation unverified; capture/layout evidence reported separately. PSA-RE bits 2.7-2.0. Software version, day.";
CM_ SG_ 1490 EcuNumber "DATABASE_CANDIDATE: physical interpretation unverified; capture/layout evidence reported separately. PSA-RE bits 1.7-1.0. ECU number. Raw invalid=255; numeric DBC decoders may still scale it: check raw before use.";
CM_ BO_ 1501 "DATABASE_CANDIDATE: physical interpretation unverified; capture/layout evidence reported separately. INFO-DIV CAN, 125000 bit/s; CAN ID 0x5DD. PSA-RE title: AAS_VERSION_2. Software and calibration version identification of the sending ECU Source: https://github.com/prototux/PSA-RE/blob/67f7581e7622410efdbb29c7eda3b86982b9b450/buses/AEE2010.full/LS.INFO-DIV/5DD.yml. Source sender alternatives: AAS; physical TX/gateway forwarding not verified. ";
CM_ SG_ 1501 EditionNumber "DATABASE_CANDIDATE: physical interpretation unverified; capture/layout evidence reported separately. PSA-RE bits 8.7-8.0. Edition number. Raw invalid=255; numeric DBC decoders may still scale it: check raw before use.";
CM_ SG_ 1501 GenerationNumberDigit2 "DATABASE_CANDIDATE: physical interpretation unverified; capture/layout evidence reported separately. PSA-RE bits 7.3-7.0. Generation number (2nd digit).";
CM_ SG_ 1501 GenerationNumberDigit1 "DATABASE_CANDIDATE: physical interpretation unverified; capture/layout evidence reported separately. PSA-RE bits 7.7-7.4. Generation number (1st digit).";
CM_ SG_ 1501 SoftwareIdentification "DATABASE_CANDIDATE: physical interpretation unverified; capture/layout evidence reported separately. PSA-RE bits 5.7-6.0. Characterizes the software identification. Raw invalid=65535; numeric DBC decoders may still scale it: check raw before use.";
CM_ SG_ 1501 SoftwareVersionYear "DATABASE_CANDIDATE: physical interpretation unverified; capture/layout evidence reported separately. PSA-RE bits 4.7-4.0. Software version, year.";
CM_ SG_ 1501 SoftwareVersionMonth "DATABASE_CANDIDATE: physical interpretation unverified; capture/layout evidence reported separately. PSA-RE bits 3.7-3.0. Software version, month.";
CM_ SG_ 1501 SoftwareVersionDay "DATABASE_CANDIDATE: physical interpretation unverified; capture/layout evidence reported separately. PSA-RE bits 2.7-2.0. Software version, day.";
CM_ SG_ 1501 EcuNumber "DATABASE_CANDIDATE: physical interpretation unverified; capture/layout evidence reported separately. PSA-RE bits 1.7-1.0. ECU number. Raw invalid=255; numeric DBC decoders may still scale it: check raw before use.";
CM_ BO_ 1503 "DATABASE_CANDIDATE: physical interpretation unverified; capture/layout evidence reported separately. INFO-DIV CAN, 125000 bit/s; CAN ID 0x5DF. PSA-RE title: CMB_VERSION. Software and calibration version identification of the sending ECU Source: https://github.com/prototux/PSA-RE/blob/67f7581e7622410efdbb29c7eda3b86982b9b450/buses/AEE2010.full/LS.INFO-DIV/5DF.yml. Source sender alternatives: CMB; physical TX/gateway forwarding not verified. VEHICLE_SOURCE_REVIEW: Owner reports original instrument cluster unit004 connected for info_buzeni_obc.csv and absent in earlier captures. This ID is absent in info_standby.csv and fully operational info_start_jizda.csv; upstream lists CMB among possible senders. Owner approved limiting IC attribution to these nine messages. Scope: Vehicle-specific sender attribution from installation report/capture comparison and compatible source alias; does not validate signal meanings or exclude gateway forwarding. Observed 10 frames in info_buzeni_obc.csv,info_charging.csv; DLCs [8]. ";
CM_ SG_ 1503 EditionNumber "DATABASE_CANDIDATE: physical interpretation unverified; capture/layout evidence reported separately. PSA-RE bits 8.7-8.0. Edition number. Raw invalid=255; numeric DBC decoders may still scale it: check raw before use.";
CM_ SG_ 1503 GenerationNumberDigit2 "DATABASE_CANDIDATE: physical interpretation unverified; capture/layout evidence reported separately. PSA-RE bits 7.3-7.0. Generation number (2nd digit).";
CM_ SG_ 1503 GenerationNumberDigit1 "DATABASE_CANDIDATE: physical interpretation unverified; capture/layout evidence reported separately. PSA-RE bits 7.7-7.4. Generation number (1st digit).";
CM_ SG_ 1503 SoftwareIdentification "DATABASE_CANDIDATE: physical interpretation unverified; capture/layout evidence reported separately. PSA-RE bits 5.7-6.0. Characterizes the software identification. Raw invalid=65535; numeric DBC decoders may still scale it: check raw before use.";
CM_ SG_ 1503 SoftwareVersionYear "DATABASE_CANDIDATE: physical interpretation unverified; capture/layout evidence reported separately. PSA-RE bits 4.7-4.0. Software version, year.";
CM_ SG_ 1503 SoftwareVersionMonth "DATABASE_CANDIDATE: physical interpretation unverified; capture/layout evidence reported separately. PSA-RE bits 3.7-3.0. Software version, month.";
CM_ SG_ 1503 SoftwareVersionDay "DATABASE_CANDIDATE: physical interpretation unverified; capture/layout evidence reported separately. PSA-RE bits 2.7-2.0. Software version, day.";
CM_ SG_ 1503 EcuNumber "DATABASE_CANDIDATE: physical interpretation unverified; capture/layout evidence reported separately. PSA-RE bits 1.7-1.0. ECU number. Raw invalid=255; numeric DBC decoders may still scale it: check raw before use.";
CM_ BO_ 1504 "DATABASE_CANDIDATE: physical interpretation unverified; capture/layout evidence reported separately. INFO-DIV CAN, 125000 bit/s; CAN ID 0x5E0. PSA-RE title: RADIO_VERSION. Software and calibration identification of the ECU, sent once at start-up. Source: https://github.com/prototux/PSA-RE/blob/67f7581e7622410efdbb29c7eda3b86982b9b450/buses/AEE2010.full/LS.INFO-DIV/5E0.yml. Source sender alternatives: RAD,ICSV; physical TX/gateway forwarding not verified. ";
CM_ SG_ 1504 EditionNumber "DATABASE_CANDIDATE: physical interpretation unverified; capture/layout evidence reported separately. PSA-RE bits 8.7-8.0. Edition number. Raw invalid=255; numeric DBC decoders may still scale it: check raw before use.";
CM_ SG_ 1504 GenerationNumberDigit2 "DATABASE_CANDIDATE: physical interpretation unverified; capture/layout evidence reported separately. PSA-RE bits 7.3-7.0. Generation number (2nd digit).";
CM_ SG_ 1504 GenerationNumberDigit1 "DATABASE_CANDIDATE: physical interpretation unverified; capture/layout evidence reported separately. PSA-RE bits 7.7-7.4. Generation number (1st digit).";
CM_ SG_ 1504 SoftwareIdentification "DATABASE_CANDIDATE: physical interpretation unverified; capture/layout evidence reported separately. PSA-RE bits 5.7-6.0. Characterizes the software identification. Raw invalid=65535; numeric DBC decoders may still scale it: check raw before use.";
CM_ SG_ 1504 SoftwareVersionYear "DATABASE_CANDIDATE: physical interpretation unverified; capture/layout evidence reported separately. PSA-RE bits 4.7-4.0. Software version, year.";
CM_ SG_ 1504 SoftwareVersionMonth "DATABASE_CANDIDATE: physical interpretation unverified; capture/layout evidence reported separately. PSA-RE bits 3.7-3.0. Software version, month.";
CM_ SG_ 1504 SoftwareVersionDay "DATABASE_CANDIDATE: physical interpretation unverified; capture/layout evidence reported separately. PSA-RE bits 2.7-2.0. Software version, day.";
CM_ SG_ 1504 EcuNumber "DATABASE_CANDIDATE: physical interpretation unverified; capture/layout evidence reported separately. PSA-RE bits 1.7-1.0. ECU number. Raw invalid=255; numeric DBC decoders may still scale it: check raw before use.";
CM_ BO_ 1507 "DATABASE_CANDIDATE: physical interpretation unverified; capture/layout evidence reported separately. INFO-DIV CAN, 125000 bit/s; CAN ID 0x5E3. PSA-RE title: CABIN_SPEED_SECTION_COMMAND. Software and calibration version identification of the sending ECU Source: https://github.com/prototux/PSA-RE/blob/67f7581e7622410efdbb29c7eda3b86982b9b450/buses/AEE2010.full/LS.INFO-DIV/5E3.yml. Source sender alternatives: IDVR; physical TX/gateway forwarding not verified. ";
CM_ SG_ 1507 EditionNumber "DATABASE_CANDIDATE: physical interpretation unverified; capture/layout evidence reported separately. PSA-RE bits 8.7-8.0. Edition number. Raw invalid=255; numeric DBC decoders may still scale it: check raw before use.";
CM_ SG_ 1507 GenerationNumberDigit2 "DATABASE_CANDIDATE: physical interpretation unverified; capture/layout evidence reported separately. PSA-RE bits 7.3-7.0. Generation number (2nd digit).";
CM_ SG_ 1507 GenerationNumberDigit1 "DATABASE_CANDIDATE: physical interpretation unverified; capture/layout evidence reported separately. PSA-RE bits 7.7-7.4. Generation number (1st digit).";
CM_ SG_ 1507 SoftwareIdentification "DATABASE_CANDIDATE: physical interpretation unverified; capture/layout evidence reported separately. PSA-RE bits 5.7-6.0. Characterizes the software identification. Raw invalid=65535; numeric DBC decoders may still scale it: check raw before use.";
CM_ SG_ 1507 SoftwareVersionYear "DATABASE_CANDIDATE: physical interpretation unverified; capture/layout evidence reported separately. PSA-RE bits 4.7-4.0. Software version, year.";
CM_ SG_ 1507 SoftwareVersionMonth "DATABASE_CANDIDATE: physical interpretation unverified; capture/layout evidence reported separately. PSA-RE bits 3.7-3.0. Software version, month.";
CM_ SG_ 1507 SoftwareVersionDay "DATABASE_CANDIDATE: physical interpretation unverified; capture/layout evidence reported separately. PSA-RE bits 2.7-2.0. Software version, day.";
CM_ SG_ 1507 EcuNumber "DATABASE_CANDIDATE: physical interpretation unverified; capture/layout evidence reported separately. PSA-RE bits 1.7-1.0. ECU number. Raw invalid=255; numeric DBC decoders may still scale it: check raw before use.";
CM_ BO_ 1508 "DATABASE_CANDIDATE: physical interpretation unverified; capture/layout evidence reported separately. INFO-DIV CAN, 125000 bit/s; CAN ID 0x5E4. PSA-RE title: BTEL_VERSION. Software and calibration version identification of the sending ECU Source: https://github.com/prototux/PSA-RE/blob/67f7581e7622410efdbb29c7eda3b86982b9b450/buses/AEE2010.full/LS.INFO-DIV/5E4.yml. Source sender alternatives: ICSV,BTEL,OVIP; physical TX/gateway forwarding not verified. Observed 12 frames in info_apka.csv,info_buzeni_obc.csv,info_charging.csv,infocan.csv; DLCs [8]. ";
CM_ SG_ 1508 EditionNumber "DATABASE_CANDIDATE: physical interpretation unverified; capture/layout evidence reported separately. PSA-RE bits 8.7-8.0. Edition number. Raw invalid=255; numeric DBC decoders may still scale it: check raw before use.";
CM_ SG_ 1508 GenerationNumberDigit2 "DATABASE_CANDIDATE: physical interpretation unverified; capture/layout evidence reported separately. PSA-RE bits 7.3-7.0. Generation number (2nd digit).";
CM_ SG_ 1508 GenerationNumberDigit1 "DATABASE_CANDIDATE: physical interpretation unverified; capture/layout evidence reported separately. PSA-RE bits 7.7-7.4. Generation number (1st digit).";
CM_ SG_ 1508 SoftwareIdentification "DATABASE_CANDIDATE: physical interpretation unverified; capture/layout evidence reported separately. PSA-RE bits 5.7-6.0. Characterizes the software identification. Raw invalid=65535; numeric DBC decoders may still scale it: check raw before use.";
CM_ SG_ 1508 SoftwareVersionYear "DATABASE_CANDIDATE: physical interpretation unverified; capture/layout evidence reported separately. PSA-RE bits 4.7-4.0. Software version, year.";
CM_ SG_ 1508 SoftwareVersionMonth "DATABASE_CANDIDATE: physical interpretation unverified; capture/layout evidence reported separately. PSA-RE bits 3.7-3.0. Software version, month.";
CM_ SG_ 1508 SoftwareVersionDay "DATABASE_CANDIDATE: physical interpretation unverified; capture/layout evidence reported separately. PSA-RE bits 2.7-2.0. Software version, day.";
CM_ SG_ 1508 EcuNumber "DATABASE_CANDIDATE: physical interpretation unverified; capture/layout evidence reported separately. PSA-RE bits 1.7-1.0. ECU number. Raw invalid=255; numeric DBC decoders may still scale it: check raw before use.";
CM_ BO_ 1509 "DATABASE_CANDIDATE: physical interpretation unverified; capture/layout evidence reported separately. INFO-DIV CAN, 125000 bit/s; CAN ID 0x5E5. PSA-RE title: EMF_VERSION. Software and calibration version identification of the sending ECU Source: https://github.com/prototux/PSA-RE/blob/67f7581e7622410efdbb29c7eda3b86982b9b450/buses/AEE2010.full/LS.INFO-DIV/5E5.yml. Source sender alternatives: EMF; physical TX/gateway forwarding not verified. ";
CM_ SG_ 1509 EditionNumber "DATABASE_CANDIDATE: physical interpretation unverified; capture/layout evidence reported separately. PSA-RE bits 8.7-8.0. Edition number. Raw invalid=255; numeric DBC decoders may still scale it: check raw before use.";
CM_ SG_ 1509 GenerationNumberDigit2 "DATABASE_CANDIDATE: physical interpretation unverified; capture/layout evidence reported separately. PSA-RE bits 7.3-7.0. Generation number (2nd digit).";
CM_ SG_ 1509 GenerationNumberDigit1 "DATABASE_CANDIDATE: physical interpretation unverified; capture/layout evidence reported separately. PSA-RE bits 7.7-7.4. Generation number (1st digit).";
CM_ SG_ 1509 SoftwareIdentification "DATABASE_CANDIDATE: physical interpretation unverified; capture/layout evidence reported separately. PSA-RE bits 5.7-6.0. Characterizes the software identification. Raw invalid=65535; numeric DBC decoders may still scale it: check raw before use.";
CM_ SG_ 1509 SoftwareVersionYear "DATABASE_CANDIDATE: physical interpretation unverified; capture/layout evidence reported separately. PSA-RE bits 4.7-4.0. Software version, year.";
CM_ SG_ 1509 SoftwareVersionMonth "DATABASE_CANDIDATE: physical interpretation unverified; capture/layout evidence reported separately. PSA-RE bits 3.7-3.0. Software version, month.";
CM_ SG_ 1509 SoftwareVersionDay "DATABASE_CANDIDATE: physical interpretation unverified; capture/layout evidence reported separately. PSA-RE bits 2.7-2.0. Software version, day.";
CM_ SG_ 1509 EcuNumber "DATABASE_CANDIDATE: physical interpretation unverified; capture/layout evidence reported separately. PSA-RE bits 1.7-1.0. ECU number. Raw invalid=255; numeric DBC decoders may still scale it: check raw before use.";
CM_ BO_ 1510 "DATABASE_CANDIDATE: physical interpretation unverified; capture/layout evidence reported separately. INFO-DIV CAN, 125000 bit/s; CAN ID 0x5E6. PSA-RE title: WIRELESS_CHARGER_VERSION. Software and calibration identification of the ECU, sent once at start-up. Source: https://github.com/prototux/PSA-RE/blob/67f7581e7622410efdbb29c7eda3b86982b9b450/buses/AEE2010.full/LS.INFO-DIV/5E6.yml. Source sender alternatives: WLC; physical TX/gateway forwarding not verified. ";
CM_ SG_ 1510 EditionNumber "DATABASE_CANDIDATE: physical interpretation unverified; capture/layout evidence reported separately. PSA-RE bits 8.7-8.0. Edition number. Raw invalid=255; numeric DBC decoders may still scale it: check raw before use.";
CM_ SG_ 1510 GenerationNumberDigit2 "DATABASE_CANDIDATE: physical interpretation unverified; capture/layout evidence reported separately. PSA-RE bits 7.3-7.0. Generation number (2nd digit).";
CM_ SG_ 1510 GenerationNumberDigit1 "DATABASE_CANDIDATE: physical interpretation unverified; capture/layout evidence reported separately. PSA-RE bits 7.7-7.4. Generation number (1st digit).";
CM_ SG_ 1510 SoftwareIdentification "DATABASE_CANDIDATE: physical interpretation unverified; capture/layout evidence reported separately. PSA-RE bits 5.7-6.0. Characterizes the software identification. Raw invalid=65535; numeric DBC decoders may still scale it: check raw before use.";
CM_ SG_ 1510 SoftwareVersionYear "DATABASE_CANDIDATE: physical interpretation unverified; capture/layout evidence reported separately. PSA-RE bits 4.7-4.0. Software version, year.";
CM_ SG_ 1510 SoftwareVersionMonth "DATABASE_CANDIDATE: physical interpretation unverified; capture/layout evidence reported separately. PSA-RE bits 3.7-3.0. Software version, month.";
CM_ SG_ 1510 SoftwareVersionDay "DATABASE_CANDIDATE: physical interpretation unverified; capture/layout evidence reported separately. PSA-RE bits 2.7-2.0. Software version, day.";
CM_ SG_ 1510 EcuNumber "DATABASE_CANDIDATE: physical interpretation unverified; capture/layout evidence reported separately. PSA-RE bits 1.7-1.0. ECU number. Raw invalid=255; numeric DBC decoders may still scale it: check raw before use.";
CM_ BO_ 1520 "DATABASE_CANDIDATE: physical interpretation unverified; capture/layout evidence reported separately. INFO-DIV CAN, 125000 bit/s; CAN ID 0x5F0. PSA-RE title: EBB_SUPERVISION. Software and calibration identification of the ECU, sent once at start-up. Source: https://github.com/prototux/PSA-RE/blob/67f7581e7622410efdbb29c7eda3b86982b9b450/buses/AEE2010.full/LS.INFO-DIV/5F0.yml. Source sender alternatives: VTH; physical TX/gateway forwarding not verified. ";
CM_ SG_ 1520 EditionNumber "DATABASE_CANDIDATE: physical interpretation unverified; capture/layout evidence reported separately. PSA-RE bits 8.7-8.0. Edition number. Raw invalid=255; numeric DBC decoders may still scale it: check raw before use.";
CM_ SG_ 1520 GenerationNumberDigit2 "DATABASE_CANDIDATE: physical interpretation unverified; capture/layout evidence reported separately. PSA-RE bits 7.3-7.0. Generation number (2nd digit).";
CM_ SG_ 1520 GenerationNumberDigit1 "DATABASE_CANDIDATE: physical interpretation unverified; capture/layout evidence reported separately. PSA-RE bits 7.7-7.4. Generation number (1st digit).";
CM_ SG_ 1520 SoftwareIdentification "DATABASE_CANDIDATE: physical interpretation unverified; capture/layout evidence reported separately. PSA-RE bits 5.7-6.0. Characterizes the software identification. Raw invalid=65535; numeric DBC decoders may still scale it: check raw before use.";
CM_ SG_ 1520 SoftwareVersionYear "DATABASE_CANDIDATE: physical interpretation unverified; capture/layout evidence reported separately. PSA-RE bits 4.7-4.0. Software version, year.";
CM_ SG_ 1520 SoftwareVersionMonth "DATABASE_CANDIDATE: physical interpretation unverified; capture/layout evidence reported separately. PSA-RE bits 3.7-3.0. Software version, month.";
CM_ SG_ 1520 SoftwareVersionDay "DATABASE_CANDIDATE: physical interpretation unverified; capture/layout evidence reported separately. PSA-RE bits 2.7-2.0. Software version, day.";
CM_ SG_ 1520 EcuNumber "DATABASE_CANDIDATE: physical interpretation unverified; capture/layout evidence reported separately. PSA-RE bits 1.7-1.0. ECU number. Raw invalid=255; numeric DBC decoders may still scale it: check raw before use.";
CM_ BO_ 1521 "DATABASE_CANDIDATE: physical interpretation unverified; capture/layout evidence reported separately. INFO-DIV CAN, 125000 bit/s; CAN ID 0x5F1. PSA-RE title: VERSION. Software and calibration version identification of the sending ECU Source: https://github.com/prototux/PSA-RE/blob/67f7581e7622410efdbb29c7eda3b86982b9b450/buses/AEE2010.full/LS.INFO-DIV/5F1.yml. Source sender alternatives: CDC; physical TX/gateway forwarding not verified. ";
CM_ SG_ 1521 EditionNumber "DATABASE_CANDIDATE: physical interpretation unverified; capture/layout evidence reported separately. PSA-RE bits 8.7-8.0. Edition number. Raw invalid=255; numeric DBC decoders may still scale it: check raw before use.";
CM_ SG_ 1521 GenerationNumberDigit2 "DATABASE_CANDIDATE: physical interpretation unverified; capture/layout evidence reported separately. PSA-RE bits 7.3-7.0. Generation number (2nd digit).";
CM_ SG_ 1521 GenerationNumberDigit1 "DATABASE_CANDIDATE: physical interpretation unverified; capture/layout evidence reported separately. PSA-RE bits 7.7-7.4. Generation number (1st digit).";
CM_ SG_ 1521 SoftwareIdentification "DATABASE_CANDIDATE: physical interpretation unverified; capture/layout evidence reported separately. PSA-RE bits 5.7-6.0. Characterizes the software identification. Raw invalid=65535; numeric DBC decoders may still scale it: check raw before use.";
CM_ SG_ 1521 SoftwareVersionYear "DATABASE_CANDIDATE: physical interpretation unverified; capture/layout evidence reported separately. PSA-RE bits 4.7-4.0. Software version, year.";
CM_ SG_ 1521 SoftwareVersionMonth "DATABASE_CANDIDATE: physical interpretation unverified; capture/layout evidence reported separately. PSA-RE bits 3.7-3.0. Software version, month.";
CM_ SG_ 1521 SoftwareVersionDay "DATABASE_CANDIDATE: physical interpretation unverified; capture/layout evidence reported separately. PSA-RE bits 2.7-2.0. Software version, day.";
CM_ SG_ 1521 EcuNumber "DATABASE_CANDIDATE: physical interpretation unverified; capture/layout evidence reported separately. PSA-RE bits 1.7-1.0. ECU number. Raw invalid=255; numeric DBC decoders may still scale it: check raw before use.";
CM_ BO_ 1522 "DATABASE_CANDIDATE: physical interpretation unverified; capture/layout evidence reported separately. INFO-DIV CAN, 125000 bit/s; CAN ID 0x5F2. PSA-RE title: FRONT_CAMERA_INFO. Software and calibration version identification of the sending ECU Source: https://github.com/prototux/PSA-RE/blob/67f7581e7622410efdbb29c7eda3b86982b9b450/buses/AEE2010.full/LS.INFO-DIV/5F2.yml. Source sender alternatives: MATT; physical TX/gateway forwarding not verified. ";
CM_ SG_ 1522 EditionNumber "DATABASE_CANDIDATE: physical interpretation unverified; capture/layout evidence reported separately. PSA-RE bits 8.7-8.0. Edition number. Raw invalid=255; numeric DBC decoders may still scale it: check raw before use.";
CM_ SG_ 1522 GenerationNumberDigit2 "DATABASE_CANDIDATE: physical interpretation unverified; capture/layout evidence reported separately. PSA-RE bits 7.3-7.0. Generation number (2nd digit).";
CM_ SG_ 1522 GenerationNumberDigit1 "DATABASE_CANDIDATE: physical interpretation unverified; capture/layout evidence reported separately. PSA-RE bits 7.7-7.4. Generation number (1st digit).";
CM_ SG_ 1522 SoftwareIdentification "DATABASE_CANDIDATE: physical interpretation unverified; capture/layout evidence reported separately. PSA-RE bits 5.7-6.0. Characterizes the software identification. Raw invalid=65535; numeric DBC decoders may still scale it: check raw before use.";
CM_ SG_ 1522 SoftwareVersionYear "DATABASE_CANDIDATE: physical interpretation unverified; capture/layout evidence reported separately. PSA-RE bits 4.7-4.0. Software version, year.";
CM_ SG_ 1522 SoftwareVersionMonth "DATABASE_CANDIDATE: physical interpretation unverified; capture/layout evidence reported separately. PSA-RE bits 3.7-3.0. Software version, month.";
CM_ SG_ 1522 SoftwareVersionDay "DATABASE_CANDIDATE: physical interpretation unverified; capture/layout evidence reported separately. PSA-RE bits 2.7-2.0. Software version, day.";
CM_ SG_ 1522 EcuNumber "DATABASE_CANDIDATE: physical interpretation unverified; capture/layout evidence reported separately. PSA-RE bits 1.7-1.0. ECU number. Raw invalid=255; numeric DBC decoders may still scale it: check raw before use.";
CM_ BO_ 1523 "DATABASE_CANDIDATE: physical interpretation unverified; capture/layout evidence reported separately. INFO-DIV CAN, 125000 bit/s; CAN ID 0x5F3. PSA-RE title: LANE_LEFT1_GEOMETRY_DATA. Software and calibration version identification of the sending ECU Source: https://github.com/prototux/PSA-RE/blob/67f7581e7622410efdbb29c7eda3b86982b9b450/buses/AEE2010.full/LS.INFO-DIV/5F3.yml. Source sender alternatives: AVP; physical TX/gateway forwarding not verified. ";
CM_ SG_ 1523 EditionNumber "DATABASE_CANDIDATE: physical interpretation unverified; capture/layout evidence reported separately. PSA-RE bits 8.7-8.0. Edition number. Raw invalid=255; numeric DBC decoders may still scale it: check raw before use.";
CM_ SG_ 1523 GenerationNumberDigit2 "DATABASE_CANDIDATE: physical interpretation unverified; capture/layout evidence reported separately. PSA-RE bits 7.3-7.0. Generation number (2nd digit).";
CM_ SG_ 1523 GenerationNumberDigit1 "DATABASE_CANDIDATE: physical interpretation unverified; capture/layout evidence reported separately. PSA-RE bits 7.7-7.4. Generation number (1st digit).";
CM_ SG_ 1523 SoftwareIdentification "DATABASE_CANDIDATE: physical interpretation unverified; capture/layout evidence reported separately. PSA-RE bits 5.7-6.0. Characterizes the software identification. Raw invalid=65535; numeric DBC decoders may still scale it: check raw before use.";
CM_ SG_ 1523 SoftwareVersionYear "DATABASE_CANDIDATE: physical interpretation unverified; capture/layout evidence reported separately. PSA-RE bits 4.7-4.0. Software version, year.";
CM_ SG_ 1523 SoftwareVersionMonth "DATABASE_CANDIDATE: physical interpretation unverified; capture/layout evidence reported separately. PSA-RE bits 3.7-3.0. Software version, month.";
CM_ SG_ 1523 SoftwareVersionDay "DATABASE_CANDIDATE: physical interpretation unverified; capture/layout evidence reported separately. PSA-RE bits 2.7-2.0. Software version, day.";
CM_ SG_ 1523 EcuNumber "DATABASE_CANDIDATE: physical interpretation unverified; capture/layout evidence reported separately. PSA-RE bits 1.7-1.0. ECU number. Raw invalid=255; numeric DBC decoders may still scale it: check raw before use.";
CM_ BO_ 1526 "DATABASE_CANDIDATE: physical interpretation unverified; capture/layout evidence reported separately. INFO-DIV CAN, 125000 bit/s; CAN ID 0x5F6. PSA-RE title: CAMERA_ADAS_STATUS. Software version identification of the BTT module, sent once on network wake-up. Source: https://github.com/prototux/PSA-RE/blob/67f7581e7622410efdbb29c7eda3b86982b9b450/buses/AEE2010.full/LS.INFO-DIV/5F6.yml. Source sender alternatives: BSG; physical TX/gateway forwarding not verified. ";
CM_ SG_ 1526 EditionNumber "DATABASE_CANDIDATE: physical interpretation unverified; capture/layout evidence reported separately. PSA-RE bits 8.7-8.0. Edition number. Raw invalid=255; numeric DBC decoders may still scale it: check raw before use.";
CM_ SG_ 1526 GenerationNumberDigit2 "DATABASE_CANDIDATE: physical interpretation unverified; capture/layout evidence reported separately. PSA-RE bits 7.3-7.0. Generation number (2nd digit).";
CM_ SG_ 1526 GenerationNumberDigit1 "DATABASE_CANDIDATE: physical interpretation unverified; capture/layout evidence reported separately. PSA-RE bits 7.7-7.4. Generation number (1st digit).";
CM_ SG_ 1526 SoftwareIdentification "DATABASE_CANDIDATE: physical interpretation unverified; capture/layout evidence reported separately. PSA-RE bits 5.7-6.0. Characterizes the software identification. Raw invalid=65535; numeric DBC decoders may still scale it: check raw before use.";
CM_ SG_ 1526 SoftwareVersionYear "DATABASE_CANDIDATE: physical interpretation unverified; capture/layout evidence reported separately. PSA-RE bits 4.7-4.0. Software version, year.";
CM_ SG_ 1526 SoftwareVersionMonth "DATABASE_CANDIDATE: physical interpretation unverified; capture/layout evidence reported separately. PSA-RE bits 3.7-3.0. Software version, month.";
CM_ SG_ 1526 SoftwareVersionDay "DATABASE_CANDIDATE: physical interpretation unverified; capture/layout evidence reported separately. PSA-RE bits 2.7-2.0. Software version, day.";
CM_ SG_ 1526 EcuNumber "DATABASE_CANDIDATE: physical interpretation unverified; capture/layout evidence reported separately. PSA-RE bits 1.7-1.0. ECU number. Raw invalid=255; numeric DBC decoders may still scale it: check raw before use.";
CM_ BO_ 1531 "DATABASE_CANDIDATE: physical interpretation unverified; capture/layout evidence reported separately. INFO-DIV CAN, 125000 bit/s; CAN ID 0x5FB. PSA-RE title: LANE_LEFT1_CURVE_DATA. Software and calibration version identification of the sending ECU Source: https://github.com/prototux/PSA-RE/blob/67f7581e7622410efdbb29c7eda3b86982b9b450/buses/AEE2010.full/LS.INFO-DIV/5FB.yml. Source sender alternatives: FMUX; physical TX/gateway forwarding not verified. Observed 12 frames in info_apka.csv,info_buzeni_obc.csv,info_charging.csv,infocan.csv; DLCs [8]. ";
CM_ SG_ 1531 EditionNumber "DATABASE_CANDIDATE: physical interpretation unverified; capture/layout evidence reported separately. PSA-RE bits 8.7-8.0. Edition number. Raw invalid=255; numeric DBC decoders may still scale it: check raw before use.";
CM_ SG_ 1531 GenerationNumberDigit2 "DATABASE_CANDIDATE: physical interpretation unverified; capture/layout evidence reported separately. PSA-RE bits 7.3-7.0. Generation number (2nd digit).";
CM_ SG_ 1531 GenerationNumberDigit1 "DATABASE_CANDIDATE: physical interpretation unverified; capture/layout evidence reported separately. PSA-RE bits 7.7-7.4. Generation number (1st digit).";
CM_ SG_ 1531 SoftwareIdentification "DATABASE_CANDIDATE: physical interpretation unverified; capture/layout evidence reported separately. PSA-RE bits 5.7-6.0. Characterizes the software identification. Raw invalid=65535; numeric DBC decoders may still scale it: check raw before use.";
CM_ SG_ 1531 SoftwareVersionYear "DATABASE_CANDIDATE: physical interpretation unverified; capture/layout evidence reported separately. PSA-RE bits 4.7-4.0. Software version, year.";
CM_ SG_ 1531 SoftwareVersionMonth "DATABASE_CANDIDATE: physical interpretation unverified; capture/layout evidence reported separately. PSA-RE bits 3.7-3.0. Software version, month.";
CM_ SG_ 1531 SoftwareVersionDay "DATABASE_CANDIDATE: physical interpretation unverified; capture/layout evidence reported separately. PSA-RE bits 2.7-2.0. Software version, day.";
CM_ SG_ 1531 EcuNumber "DATABASE_CANDIDATE: physical interpretation unverified; capture/layout evidence reported separately. PSA-RE bits 1.7-1.0. ECU number. Raw invalid=255; numeric DBC decoders may still scale it: check raw before use.";
CM_ BO_ 1532 "DATABASE_CANDIDATE: physical interpretation unverified; capture/layout evidence reported separately. INFO-DIV CAN, 125000 bit/s; CAN ID 0x5FC. PSA-RE title: LANE_LEFT0_GEOMETRY_DATA. Software and calibration version identification of the sending ECU Source: https://github.com/prototux/PSA-RE/blob/67f7581e7622410efdbb29c7eda3b86982b9b450/buses/AEE2010.full/LS.INFO-DIV/5FC.yml. Source sender alternatives: MDS; physical TX/gateway forwarding not verified. Observed 12 frames in info_apka.csv,info_buzeni_obc.csv,info_charging.csv,infocan.csv; DLCs [8]. ";
CM_ SG_ 1532 EditionNumber "DATABASE_CANDIDATE: physical interpretation unverified; capture/layout evidence reported separately. PSA-RE bits 8.7-8.0. Edition number. Raw invalid=255; numeric DBC decoders may still scale it: check raw before use.";
CM_ SG_ 1532 GenerationNumberDigit2 "DATABASE_CANDIDATE: physical interpretation unverified; capture/layout evidence reported separately. PSA-RE bits 7.3-7.0. Generation number (2nd digit).";
CM_ SG_ 1532 GenerationNumberDigit1 "DATABASE_CANDIDATE: physical interpretation unverified; capture/layout evidence reported separately. PSA-RE bits 7.7-7.4. Generation number (1st digit).";
CM_ SG_ 1532 SoftwareIdentification "DATABASE_CANDIDATE: physical interpretation unverified; capture/layout evidence reported separately. PSA-RE bits 5.7-6.0. Characterizes the software identification. Raw invalid=65535; numeric DBC decoders may still scale it: check raw before use.";
CM_ SG_ 1532 SoftwareVersionYear "DATABASE_CANDIDATE: physical interpretation unverified; capture/layout evidence reported separately. PSA-RE bits 4.7-4.0. Software version, year.";
CM_ SG_ 1532 SoftwareVersionMonth "DATABASE_CANDIDATE: physical interpretation unverified; capture/layout evidence reported separately. PSA-RE bits 3.7-3.0. Software version, month.";
CM_ SG_ 1532 SoftwareVersionDay "DATABASE_CANDIDATE: physical interpretation unverified; capture/layout evidence reported separately. PSA-RE bits 2.7-2.0. Software version, day.";
CM_ SG_ 1532 EcuNumber "DATABASE_CANDIDATE: physical interpretation unverified; capture/layout evidence reported separately. PSA-RE bits 1.7-1.0. ECU number. Raw invalid=255; numeric DBC decoders may still scale it: check raw before use.";
CM_ BO_ 1533 "DATABASE_CANDIDATE: physical interpretation unverified; capture/layout evidence reported separately. INFO-DIV CAN, 125000 bit/s; CAN ID 0x5FD. PSA-RE title: LANE_RIGHT0_CURVE_DATA. Software and calibration version identification of the sending ECU Source: https://github.com/prototux/PSA-RE/blob/67f7581e7622410efdbb29c7eda3b86982b9b450/buses/AEE2010.full/LS.INFO-DIV/5FD.yml. Source sender alternatives: AMPLI; physical TX/gateway forwarding not verified. ";
CM_ SG_ 1533 EditionNumber "DATABASE_CANDIDATE: physical interpretation unverified; capture/layout evidence reported separately. PSA-RE bits 8.7-8.0. Edition number. Raw invalid=255; numeric DBC decoders may still scale it: check raw before use.";
CM_ SG_ 1533 GenerationNumberDigit2 "DATABASE_CANDIDATE: physical interpretation unverified; capture/layout evidence reported separately. PSA-RE bits 7.3-7.0. Generation number (2nd digit).";
CM_ SG_ 1533 GenerationNumberDigit1 "DATABASE_CANDIDATE: physical interpretation unverified; capture/layout evidence reported separately. PSA-RE bits 7.7-7.4. Generation number (1st digit).";
CM_ SG_ 1533 SoftwareIdentification "DATABASE_CANDIDATE: physical interpretation unverified; capture/layout evidence reported separately. PSA-RE bits 5.7-6.0. Characterizes the software identification. Raw invalid=65535; numeric DBC decoders may still scale it: check raw before use.";
CM_ SG_ 1533 SoftwareVersionYear "DATABASE_CANDIDATE: physical interpretation unverified; capture/layout evidence reported separately. PSA-RE bits 4.7-4.0. Software version, year.";
CM_ SG_ 1533 SoftwareVersionMonth "DATABASE_CANDIDATE: physical interpretation unverified; capture/layout evidence reported separately. PSA-RE bits 3.7-3.0. Software version, month.";
CM_ SG_ 1533 SoftwareVersionDay "DATABASE_CANDIDATE: physical interpretation unverified; capture/layout evidence reported separately. PSA-RE bits 2.7-2.0. Software version, day.";
CM_ SG_ 1533 EcuNumber "DATABASE_CANDIDATE: physical interpretation unverified; capture/layout evidence reported separately. PSA-RE bits 1.7-1.0. ECU number. Raw invalid=255; numeric DBC decoders may still scale it: check raw before use.";
CM_ BO_ 1576 "DATABASE_CANDIDATE: physical interpretation unverified; capture/layout evidence reported separately. INFO-DIV CAN, 125000 bit/s; CAN ID 0x628. PSA-RE title: HDC_VCI_DIAG_RESPONSE. Diagnostic response sent by the HDC_VCI ECU. Source: https://github.com/prototux/PSA-RE/blob/67f7581e7622410efdbb29c7eda3b86982b9b450/buses/AEE2010.full/LS.INFO-DIV/628.yml. Source sender alternatives: BSI; physical TX/gateway forwarding not verified. WIRE ISO-TP ONLY: normal addressing candidate, maximum Classical CAN DLC 8; actual DLC may be shorter. Data includes padding. No reassembly, text, DID or application-layer decoding. Original application layouts are preserved in source JSON; do not decode them at wire offsets. ";
CM_ SG_ 1576 FlowPadding5 "TRANSPORT_CANDIDATE: normal-addressing ISO-TP. PSA-RE bits 8.7-8.0. ";
CM_ SG_ 1576 FirstData6 "TRANSPORT_CANDIDATE: normal-addressing ISO-TP. PSA-RE bits 8.7-8.0. ";
CM_ SG_ 1576 UnknownData7 "TRANSPORT_CANDIDATE: normal-addressing ISO-TP. PSA-RE bits 8.7-8.0. ";
CM_ SG_ 1576 ConsecutiveData7 "TRANSPORT_CANDIDATE: normal-addressing ISO-TP. PSA-RE bits 8.7-8.0. ";
CM_ SG_ 1576 SingleData7 "TRANSPORT_CANDIDATE: normal-addressing ISO-TP. PSA-RE bits 8.7-8.0. ";
CM_ SG_ 1576 FlowPadding4 "TRANSPORT_CANDIDATE: normal-addressing ISO-TP. PSA-RE bits 7.7-7.0. ";
CM_ SG_ 1576 FirstData5 "TRANSPORT_CANDIDATE: normal-addressing ISO-TP. PSA-RE bits 7.7-7.0. ";
CM_ SG_ 1576 UnknownData6 "TRANSPORT_CANDIDATE: normal-addressing ISO-TP. PSA-RE bits 7.7-7.0. ";
CM_ SG_ 1576 ConsecutiveData6 "TRANSPORT_CANDIDATE: normal-addressing ISO-TP. PSA-RE bits 7.7-7.0. ";
CM_ SG_ 1576 SingleData6 "TRANSPORT_CANDIDATE: normal-addressing ISO-TP. PSA-RE bits 7.7-7.0. ";
CM_ SG_ 1576 FlowPadding3 "TRANSPORT_CANDIDATE: normal-addressing ISO-TP. PSA-RE bits 6.7-6.0. ";
CM_ SG_ 1576 FirstData4 "TRANSPORT_CANDIDATE: normal-addressing ISO-TP. PSA-RE bits 6.7-6.0. ";
CM_ SG_ 1576 UnknownData5 "TRANSPORT_CANDIDATE: normal-addressing ISO-TP. PSA-RE bits 6.7-6.0. ";
CM_ SG_ 1576 ConsecutiveData5 "TRANSPORT_CANDIDATE: normal-addressing ISO-TP. PSA-RE bits 6.7-6.0. ";
CM_ SG_ 1576 SingleData5 "TRANSPORT_CANDIDATE: normal-addressing ISO-TP. PSA-RE bits 6.7-6.0. ";
CM_ SG_ 1576 FlowPadding2 "TRANSPORT_CANDIDATE: normal-addressing ISO-TP. PSA-RE bits 5.7-5.0. ";
CM_ SG_ 1576 FirstData3 "TRANSPORT_CANDIDATE: normal-addressing ISO-TP. PSA-RE bits 5.7-5.0. ";
CM_ SG_ 1576 UnknownData4 "TRANSPORT_CANDIDATE: normal-addressing ISO-TP. PSA-RE bits 5.7-5.0. ";
CM_ SG_ 1576 ConsecutiveData4 "TRANSPORT_CANDIDATE: normal-addressing ISO-TP. PSA-RE bits 5.7-5.0. ";
CM_ SG_ 1576 SingleData4 "TRANSPORT_CANDIDATE: normal-addressing ISO-TP. PSA-RE bits 5.7-5.0. ";
CM_ SG_ 1576 FlowPadding1 "TRANSPORT_CANDIDATE: normal-addressing ISO-TP. PSA-RE bits 4.7-4.0. ";
CM_ SG_ 1576 FirstData2 "TRANSPORT_CANDIDATE: normal-addressing ISO-TP. PSA-RE bits 4.7-4.0. ";
CM_ SG_ 1576 UnknownData3 "TRANSPORT_CANDIDATE: normal-addressing ISO-TP. PSA-RE bits 4.7-4.0. ";
CM_ SG_ 1576 ConsecutiveData3 "TRANSPORT_CANDIDATE: normal-addressing ISO-TP. PSA-RE bits 4.7-4.0. ";
CM_ SG_ 1576 SingleData3 "TRANSPORT_CANDIDATE: normal-addressing ISO-TP. PSA-RE bits 4.7-4.0. ";
CM_ SG_ 1576 FirstData1 "TRANSPORT_CANDIDATE: normal-addressing ISO-TP. PSA-RE bits 3.7-3.0. ";
CM_ SG_ 1576 UnknownData2 "TRANSPORT_CANDIDATE: normal-addressing ISO-TP. PSA-RE bits 3.7-3.0. ";
CM_ SG_ 1576 ConsecutiveData2 "TRANSPORT_CANDIDATE: normal-addressing ISO-TP. PSA-RE bits 3.7-3.0. ";
CM_ SG_ 1576 SingleData2 "TRANSPORT_CANDIDATE: normal-addressing ISO-TP. PSA-RE bits 3.7-3.0. ";
CM_ SG_ 1576 SeparationTimeRaw "TRANSPORT_CANDIDATE: normal-addressing ISO-TP. PSA-RE bits 3.7-3.0. Raw STmin code; 0xF1..0xF9 are not milliseconds.";
CM_ SG_ 1576 UnknownData1 "TRANSPORT_CANDIDATE: normal-addressing ISO-TP. PSA-RE bits 2.7-2.0. ";
CM_ SG_ 1576 ConsecutiveData1 "TRANSPORT_CANDIDATE: normal-addressing ISO-TP. PSA-RE bits 2.7-2.0. ";
CM_ SG_ 1576 SingleData1 "TRANSPORT_CANDIDATE: normal-addressing ISO-TP. PSA-RE bits 2.7-2.0. ";
CM_ SG_ 1576 BlockSize "TRANSPORT_CANDIDATE: normal-addressing ISO-TP. PSA-RE bits 2.7-2.0. ";
CM_ SG_ 1576 UnknownPciLow "TRANSPORT_CANDIDATE: normal-addressing ISO-TP. PSA-RE bits 1.3-1.0. ";
CM_ SG_ 1576 FlowStatus "TRANSPORT_CANDIDATE: normal-addressing ISO-TP. PSA-RE bits 1.3-1.0. ";
CM_ SG_ 1576 ConsecutiveSequence "TRANSPORT_CANDIDATE: normal-addressing ISO-TP. PSA-RE bits 1.3-1.0. ";
CM_ SG_ 1576 FirstFrameLength "TRANSPORT_CANDIDATE: normal-addressing ISO-TP. PSA-RE bits 1.3-2.0. 12-bit declared PDU length; not a reassembled value.";
CM_ SG_ 1576 SingleFrameLength "TRANSPORT_CANDIDATE: normal-addressing ISO-TP. PSA-RE bits 1.3-1.0. Declared data length; not a validity check.";
CM_ SG_ 1576 IsoTpFrameType "TRANSPORT_CANDIDATE: normal-addressing ISO-TP. PSA-RE bits 1.7-1.4. PCI high nibble; normal addressing candidate.";
CM_ BO_ 1601 "DATABASE_CANDIDATE: physical interpretation unverified; capture/layout evidence reported separately. INFO-DIV CAN, 125000 bit/s; CAN ID 0x641. PSA-RE title: BML_DIAG_RESPONSE_2. Diagnostic response sent by the BML ECU. Source: https://github.com/prototux/PSA-RE/blob/67f7581e7622410efdbb29c7eda3b86982b9b450/buses/AEE2010.full/LS.INFO-DIV/641_BML_DIAG_RESPONSE_2.yml. Source sender alternatives: BSI; physical TX/gateway forwarding not verified. WIRE ISO-TP ONLY: normal addressing candidate, maximum Classical CAN DLC 8; actual DLC may be shorter. Data includes padding. No reassembly, text, DID or application-layer decoding. Original application layouts are preserved in source JSON; do not decode them at wire offsets. Unresolved alternative source layouts preserved in source JSON. ";
CM_ SG_ 1601 FlowPadding5 "TRANSPORT_CANDIDATE: normal-addressing ISO-TP. PSA-RE bits 8.7-8.0. ";
CM_ SG_ 1601 FirstData6 "TRANSPORT_CANDIDATE: normal-addressing ISO-TP. PSA-RE bits 8.7-8.0. ";
CM_ SG_ 1601 UnknownData7 "TRANSPORT_CANDIDATE: normal-addressing ISO-TP. PSA-RE bits 8.7-8.0. ";
CM_ SG_ 1601 ConsecutiveData7 "TRANSPORT_CANDIDATE: normal-addressing ISO-TP. PSA-RE bits 8.7-8.0. ";
CM_ SG_ 1601 SingleData7 "TRANSPORT_CANDIDATE: normal-addressing ISO-TP. PSA-RE bits 8.7-8.0. ";
CM_ SG_ 1601 FlowPadding4 "TRANSPORT_CANDIDATE: normal-addressing ISO-TP. PSA-RE bits 7.7-7.0. ";
CM_ SG_ 1601 FirstData5 "TRANSPORT_CANDIDATE: normal-addressing ISO-TP. PSA-RE bits 7.7-7.0. ";
CM_ SG_ 1601 UnknownData6 "TRANSPORT_CANDIDATE: normal-addressing ISO-TP. PSA-RE bits 7.7-7.0. ";
CM_ SG_ 1601 ConsecutiveData6 "TRANSPORT_CANDIDATE: normal-addressing ISO-TP. PSA-RE bits 7.7-7.0. ";
CM_ SG_ 1601 SingleData6 "TRANSPORT_CANDIDATE: normal-addressing ISO-TP. PSA-RE bits 7.7-7.0. ";
CM_ SG_ 1601 FlowPadding3 "TRANSPORT_CANDIDATE: normal-addressing ISO-TP. PSA-RE bits 6.7-6.0. ";
CM_ SG_ 1601 FirstData4 "TRANSPORT_CANDIDATE: normal-addressing ISO-TP. PSA-RE bits 6.7-6.0. ";
CM_ SG_ 1601 UnknownData5 "TRANSPORT_CANDIDATE: normal-addressing ISO-TP. PSA-RE bits 6.7-6.0. ";
CM_ SG_ 1601 ConsecutiveData5 "TRANSPORT_CANDIDATE: normal-addressing ISO-TP. PSA-RE bits 6.7-6.0. ";
CM_ SG_ 1601 SingleData5 "TRANSPORT_CANDIDATE: normal-addressing ISO-TP. PSA-RE bits 6.7-6.0. ";
CM_ SG_ 1601 FlowPadding2 "TRANSPORT_CANDIDATE: normal-addressing ISO-TP. PSA-RE bits 5.7-5.0. ";
CM_ SG_ 1601 FirstData3 "TRANSPORT_CANDIDATE: normal-addressing ISO-TP. PSA-RE bits 5.7-5.0. ";
CM_ SG_ 1601 UnknownData4 "TRANSPORT_CANDIDATE: normal-addressing ISO-TP. PSA-RE bits 5.7-5.0. ";
CM_ SG_ 1601 ConsecutiveData4 "TRANSPORT_CANDIDATE: normal-addressing ISO-TP. PSA-RE bits 5.7-5.0. ";
CM_ SG_ 1601 SingleData4 "TRANSPORT_CANDIDATE: normal-addressing ISO-TP. PSA-RE bits 5.7-5.0. ";
CM_ SG_ 1601 FlowPadding1 "TRANSPORT_CANDIDATE: normal-addressing ISO-TP. PSA-RE bits 4.7-4.0. ";
CM_ SG_ 1601 FirstData2 "TRANSPORT_CANDIDATE: normal-addressing ISO-TP. PSA-RE bits 4.7-4.0. ";
CM_ SG_ 1601 UnknownData3 "TRANSPORT_CANDIDATE: normal-addressing ISO-TP. PSA-RE bits 4.7-4.0. ";
CM_ SG_ 1601 ConsecutiveData3 "TRANSPORT_CANDIDATE: normal-addressing ISO-TP. PSA-RE bits 4.7-4.0. ";
CM_ SG_ 1601 SingleData3 "TRANSPORT_CANDIDATE: normal-addressing ISO-TP. PSA-RE bits 4.7-4.0. ";
CM_ SG_ 1601 FirstData1 "TRANSPORT_CANDIDATE: normal-addressing ISO-TP. PSA-RE bits 3.7-3.0. ";
CM_ SG_ 1601 UnknownData2 "TRANSPORT_CANDIDATE: normal-addressing ISO-TP. PSA-RE bits 3.7-3.0. ";
CM_ SG_ 1601 ConsecutiveData2 "TRANSPORT_CANDIDATE: normal-addressing ISO-TP. PSA-RE bits 3.7-3.0. ";
CM_ SG_ 1601 SingleData2 "TRANSPORT_CANDIDATE: normal-addressing ISO-TP. PSA-RE bits 3.7-3.0. ";
CM_ SG_ 1601 SeparationTimeRaw "TRANSPORT_CANDIDATE: normal-addressing ISO-TP. PSA-RE bits 3.7-3.0. Raw STmin code; 0xF1..0xF9 are not milliseconds.";
CM_ SG_ 1601 UnknownData1 "TRANSPORT_CANDIDATE: normal-addressing ISO-TP. PSA-RE bits 2.7-2.0. ";
CM_ SG_ 1601 ConsecutiveData1 "TRANSPORT_CANDIDATE: normal-addressing ISO-TP. PSA-RE bits 2.7-2.0. ";
CM_ SG_ 1601 SingleData1 "TRANSPORT_CANDIDATE: normal-addressing ISO-TP. PSA-RE bits 2.7-2.0. ";
CM_ SG_ 1601 BlockSize "TRANSPORT_CANDIDATE: normal-addressing ISO-TP. PSA-RE bits 2.7-2.0. ";
CM_ SG_ 1601 UnknownPciLow "TRANSPORT_CANDIDATE: normal-addressing ISO-TP. PSA-RE bits 1.3-1.0. ";
CM_ SG_ 1601 FlowStatus "TRANSPORT_CANDIDATE: normal-addressing ISO-TP. PSA-RE bits 1.3-1.0. ";
CM_ SG_ 1601 ConsecutiveSequence "TRANSPORT_CANDIDATE: normal-addressing ISO-TP. PSA-RE bits 1.3-1.0. ";
CM_ SG_ 1601 FirstFrameLength "TRANSPORT_CANDIDATE: normal-addressing ISO-TP. PSA-RE bits 1.3-2.0. 12-bit declared PDU length; not a reassembled value.";
CM_ SG_ 1601 SingleFrameLength "TRANSPORT_CANDIDATE: normal-addressing ISO-TP. PSA-RE bits 1.3-1.0. Declared data length; not a validity check.";
CM_ SG_ 1601 IsoTpFrameType "TRANSPORT_CANDIDATE: normal-addressing ISO-TP. PSA-RE bits 1.7-1.4. PCI high nibble; normal addressing candidate.";
CM_ BO_ 1602 "DATABASE_CANDIDATE: physical interpretation unverified; capture/layout evidence reported separately. INFO-DIV CAN, 125000 bit/s; CAN ID 0x642. PSA-RE title: HDC_DIAG_RESPONSE. Diagnostic response sent by the HDC ECU. Source: https://github.com/prototux/PSA-RE/blob/67f7581e7622410efdbb29c7eda3b86982b9b450/buses/AEE2010.full/LS.INFO-DIV/642.yml. Source sender alternatives: BSI; physical TX/gateway forwarding not verified. WIRE ISO-TP ONLY: normal addressing candidate, maximum Classical CAN DLC 8; actual DLC may be shorter. Data includes padding. No reassembly, text, DID or application-layer decoding. Original application layouts are preserved in source JSON; do not decode them at wire offsets. ";
CM_ SG_ 1602 FlowPadding5 "TRANSPORT_CANDIDATE: normal-addressing ISO-TP. PSA-RE bits 8.7-8.0. ";
CM_ SG_ 1602 FirstData6 "TRANSPORT_CANDIDATE: normal-addressing ISO-TP. PSA-RE bits 8.7-8.0. ";
CM_ SG_ 1602 UnknownData7 "TRANSPORT_CANDIDATE: normal-addressing ISO-TP. PSA-RE bits 8.7-8.0. ";
CM_ SG_ 1602 ConsecutiveData7 "TRANSPORT_CANDIDATE: normal-addressing ISO-TP. PSA-RE bits 8.7-8.0. ";
CM_ SG_ 1602 SingleData7 "TRANSPORT_CANDIDATE: normal-addressing ISO-TP. PSA-RE bits 8.7-8.0. ";
CM_ SG_ 1602 FlowPadding4 "TRANSPORT_CANDIDATE: normal-addressing ISO-TP. PSA-RE bits 7.7-7.0. ";
CM_ SG_ 1602 FirstData5 "TRANSPORT_CANDIDATE: normal-addressing ISO-TP. PSA-RE bits 7.7-7.0. ";
CM_ SG_ 1602 UnknownData6 "TRANSPORT_CANDIDATE: normal-addressing ISO-TP. PSA-RE bits 7.7-7.0. ";
CM_ SG_ 1602 ConsecutiveData6 "TRANSPORT_CANDIDATE: normal-addressing ISO-TP. PSA-RE bits 7.7-7.0. ";
CM_ SG_ 1602 SingleData6 "TRANSPORT_CANDIDATE: normal-addressing ISO-TP. PSA-RE bits 7.7-7.0. ";
CM_ SG_ 1602 FlowPadding3 "TRANSPORT_CANDIDATE: normal-addressing ISO-TP. PSA-RE bits 6.7-6.0. ";
CM_ SG_ 1602 FirstData4 "TRANSPORT_CANDIDATE: normal-addressing ISO-TP. PSA-RE bits 6.7-6.0. ";
CM_ SG_ 1602 UnknownData5 "TRANSPORT_CANDIDATE: normal-addressing ISO-TP. PSA-RE bits 6.7-6.0. ";
CM_ SG_ 1602 ConsecutiveData5 "TRANSPORT_CANDIDATE: normal-addressing ISO-TP. PSA-RE bits 6.7-6.0. ";
CM_ SG_ 1602 SingleData5 "TRANSPORT_CANDIDATE: normal-addressing ISO-TP. PSA-RE bits 6.7-6.0. ";
CM_ SG_ 1602 FlowPadding2 "TRANSPORT_CANDIDATE: normal-addressing ISO-TP. PSA-RE bits 5.7-5.0. ";
CM_ SG_ 1602 FirstData3 "TRANSPORT_CANDIDATE: normal-addressing ISO-TP. PSA-RE bits 5.7-5.0. ";
CM_ SG_ 1602 UnknownData4 "TRANSPORT_CANDIDATE: normal-addressing ISO-TP. PSA-RE bits 5.7-5.0. ";
CM_ SG_ 1602 ConsecutiveData4 "TRANSPORT_CANDIDATE: normal-addressing ISO-TP. PSA-RE bits 5.7-5.0. ";
CM_ SG_ 1602 SingleData4 "TRANSPORT_CANDIDATE: normal-addressing ISO-TP. PSA-RE bits 5.7-5.0. ";
CM_ SG_ 1602 FlowPadding1 "TRANSPORT_CANDIDATE: normal-addressing ISO-TP. PSA-RE bits 4.7-4.0. ";
CM_ SG_ 1602 FirstData2 "TRANSPORT_CANDIDATE: normal-addressing ISO-TP. PSA-RE bits 4.7-4.0. ";
CM_ SG_ 1602 UnknownData3 "TRANSPORT_CANDIDATE: normal-addressing ISO-TP. PSA-RE bits 4.7-4.0. ";
CM_ SG_ 1602 ConsecutiveData3 "TRANSPORT_CANDIDATE: normal-addressing ISO-TP. PSA-RE bits 4.7-4.0. ";
CM_ SG_ 1602 SingleData3 "TRANSPORT_CANDIDATE: normal-addressing ISO-TP. PSA-RE bits 4.7-4.0. ";
CM_ SG_ 1602 FirstData1 "TRANSPORT_CANDIDATE: normal-addressing ISO-TP. PSA-RE bits 3.7-3.0. ";
CM_ SG_ 1602 UnknownData2 "TRANSPORT_CANDIDATE: normal-addressing ISO-TP. PSA-RE bits 3.7-3.0. ";
CM_ SG_ 1602 ConsecutiveData2 "TRANSPORT_CANDIDATE: normal-addressing ISO-TP. PSA-RE bits 3.7-3.0. ";
CM_ SG_ 1602 SingleData2 "TRANSPORT_CANDIDATE: normal-addressing ISO-TP. PSA-RE bits 3.7-3.0. ";
CM_ SG_ 1602 SeparationTimeRaw "TRANSPORT_CANDIDATE: normal-addressing ISO-TP. PSA-RE bits 3.7-3.0. Raw STmin code; 0xF1..0xF9 are not milliseconds.";
CM_ SG_ 1602 UnknownData1 "TRANSPORT_CANDIDATE: normal-addressing ISO-TP. PSA-RE bits 2.7-2.0. ";
CM_ SG_ 1602 ConsecutiveData1 "TRANSPORT_CANDIDATE: normal-addressing ISO-TP. PSA-RE bits 2.7-2.0. ";
CM_ SG_ 1602 SingleData1 "TRANSPORT_CANDIDATE: normal-addressing ISO-TP. PSA-RE bits 2.7-2.0. ";
CM_ SG_ 1602 BlockSize "TRANSPORT_CANDIDATE: normal-addressing ISO-TP. PSA-RE bits 2.7-2.0. ";
CM_ SG_ 1602 UnknownPciLow "TRANSPORT_CANDIDATE: normal-addressing ISO-TP. PSA-RE bits 1.3-1.0. ";
CM_ SG_ 1602 FlowStatus "TRANSPORT_CANDIDATE: normal-addressing ISO-TP. PSA-RE bits 1.3-1.0. ";
CM_ SG_ 1602 ConsecutiveSequence "TRANSPORT_CANDIDATE: normal-addressing ISO-TP. PSA-RE bits 1.3-1.0. ";
CM_ SG_ 1602 FirstFrameLength "TRANSPORT_CANDIDATE: normal-addressing ISO-TP. PSA-RE bits 1.3-2.0. 12-bit declared PDU length; not a reassembled value.";
CM_ SG_ 1602 SingleFrameLength "TRANSPORT_CANDIDATE: normal-addressing ISO-TP. PSA-RE bits 1.3-1.0. Declared data length; not a validity check.";
CM_ SG_ 1602 IsoTpFrameType "TRANSPORT_CANDIDATE: normal-addressing ISO-TP. PSA-RE bits 1.7-1.4. PCI high nibble; normal addressing candidate.";
CM_ BO_ 1603 "DATABASE_CANDIDATE: physical interpretation unverified; capture/layout evidence reported separately. INFO-DIV CAN, 125000 bit/s; CAN ID 0x643. PSA-RE title: LVDS_DIAG_RESPONSE. Diagnostic response sent by the LVDS ECU. Source: https://github.com/prototux/PSA-RE/blob/67f7581e7622410efdbb29c7eda3b86982b9b450/buses/AEE2010.full/LS.INFO-DIV/643.yml. Source sender alternatives: OVIP; physical TX/gateway forwarding not verified. WIRE ISO-TP ONLY: normal addressing candidate, maximum Classical CAN DLC 8; actual DLC may be shorter. Data includes padding. No reassembly, text, DID or application-layer decoding. Original application layouts are preserved in source JSON; do not decode them at wire offsets. ";
CM_ SG_ 1603 FlowPadding5 "TRANSPORT_CANDIDATE: normal-addressing ISO-TP. PSA-RE bits 8.7-8.0. ";
CM_ SG_ 1603 FirstData6 "TRANSPORT_CANDIDATE: normal-addressing ISO-TP. PSA-RE bits 8.7-8.0. ";
CM_ SG_ 1603 UnknownData7 "TRANSPORT_CANDIDATE: normal-addressing ISO-TP. PSA-RE bits 8.7-8.0. ";
CM_ SG_ 1603 ConsecutiveData7 "TRANSPORT_CANDIDATE: normal-addressing ISO-TP. PSA-RE bits 8.7-8.0. ";
CM_ SG_ 1603 SingleData7 "TRANSPORT_CANDIDATE: normal-addressing ISO-TP. PSA-RE bits 8.7-8.0. ";
CM_ SG_ 1603 FlowPadding4 "TRANSPORT_CANDIDATE: normal-addressing ISO-TP. PSA-RE bits 7.7-7.0. ";
CM_ SG_ 1603 FirstData5 "TRANSPORT_CANDIDATE: normal-addressing ISO-TP. PSA-RE bits 7.7-7.0. ";
CM_ SG_ 1603 UnknownData6 "TRANSPORT_CANDIDATE: normal-addressing ISO-TP. PSA-RE bits 7.7-7.0. ";
CM_ SG_ 1603 ConsecutiveData6 "TRANSPORT_CANDIDATE: normal-addressing ISO-TP. PSA-RE bits 7.7-7.0. ";
CM_ SG_ 1603 SingleData6 "TRANSPORT_CANDIDATE: normal-addressing ISO-TP. PSA-RE bits 7.7-7.0. ";
CM_ SG_ 1603 FlowPadding3 "TRANSPORT_CANDIDATE: normal-addressing ISO-TP. PSA-RE bits 6.7-6.0. ";
CM_ SG_ 1603 FirstData4 "TRANSPORT_CANDIDATE: normal-addressing ISO-TP. PSA-RE bits 6.7-6.0. ";
CM_ SG_ 1603 UnknownData5 "TRANSPORT_CANDIDATE: normal-addressing ISO-TP. PSA-RE bits 6.7-6.0. ";
CM_ SG_ 1603 ConsecutiveData5 "TRANSPORT_CANDIDATE: normal-addressing ISO-TP. PSA-RE bits 6.7-6.0. ";
CM_ SG_ 1603 SingleData5 "TRANSPORT_CANDIDATE: normal-addressing ISO-TP. PSA-RE bits 6.7-6.0. ";
CM_ SG_ 1603 FlowPadding2 "TRANSPORT_CANDIDATE: normal-addressing ISO-TP. PSA-RE bits 5.7-5.0. ";
CM_ SG_ 1603 FirstData3 "TRANSPORT_CANDIDATE: normal-addressing ISO-TP. PSA-RE bits 5.7-5.0. ";
CM_ SG_ 1603 UnknownData4 "TRANSPORT_CANDIDATE: normal-addressing ISO-TP. PSA-RE bits 5.7-5.0. ";
CM_ SG_ 1603 ConsecutiveData4 "TRANSPORT_CANDIDATE: normal-addressing ISO-TP. PSA-RE bits 5.7-5.0. ";
CM_ SG_ 1603 SingleData4 "TRANSPORT_CANDIDATE: normal-addressing ISO-TP. PSA-RE bits 5.7-5.0. ";
CM_ SG_ 1603 FlowPadding1 "TRANSPORT_CANDIDATE: normal-addressing ISO-TP. PSA-RE bits 4.7-4.0. ";
CM_ SG_ 1603 FirstData2 "TRANSPORT_CANDIDATE: normal-addressing ISO-TP. PSA-RE bits 4.7-4.0. ";
CM_ SG_ 1603 UnknownData3 "TRANSPORT_CANDIDATE: normal-addressing ISO-TP. PSA-RE bits 4.7-4.0. ";
CM_ SG_ 1603 ConsecutiveData3 "TRANSPORT_CANDIDATE: normal-addressing ISO-TP. PSA-RE bits 4.7-4.0. ";
CM_ SG_ 1603 SingleData3 "TRANSPORT_CANDIDATE: normal-addressing ISO-TP. PSA-RE bits 4.7-4.0. ";
CM_ SG_ 1603 FirstData1 "TRANSPORT_CANDIDATE: normal-addressing ISO-TP. PSA-RE bits 3.7-3.0. ";
CM_ SG_ 1603 UnknownData2 "TRANSPORT_CANDIDATE: normal-addressing ISO-TP. PSA-RE bits 3.7-3.0. ";
CM_ SG_ 1603 ConsecutiveData2 "TRANSPORT_CANDIDATE: normal-addressing ISO-TP. PSA-RE bits 3.7-3.0. ";
CM_ SG_ 1603 SingleData2 "TRANSPORT_CANDIDATE: normal-addressing ISO-TP. PSA-RE bits 3.7-3.0. ";
CM_ SG_ 1603 SeparationTimeRaw "TRANSPORT_CANDIDATE: normal-addressing ISO-TP. PSA-RE bits 3.7-3.0. Raw STmin code; 0xF1..0xF9 are not milliseconds.";
CM_ SG_ 1603 UnknownData1 "TRANSPORT_CANDIDATE: normal-addressing ISO-TP. PSA-RE bits 2.7-2.0. ";
CM_ SG_ 1603 ConsecutiveData1 "TRANSPORT_CANDIDATE: normal-addressing ISO-TP. PSA-RE bits 2.7-2.0. ";
CM_ SG_ 1603 SingleData1 "TRANSPORT_CANDIDATE: normal-addressing ISO-TP. PSA-RE bits 2.7-2.0. ";
CM_ SG_ 1603 BlockSize "TRANSPORT_CANDIDATE: normal-addressing ISO-TP. PSA-RE bits 2.7-2.0. ";
CM_ SG_ 1603 UnknownPciLow "TRANSPORT_CANDIDATE: normal-addressing ISO-TP. PSA-RE bits 1.3-1.0. ";
CM_ SG_ 1603 FlowStatus "TRANSPORT_CANDIDATE: normal-addressing ISO-TP. PSA-RE bits 1.3-1.0. ";
CM_ SG_ 1603 ConsecutiveSequence "TRANSPORT_CANDIDATE: normal-addressing ISO-TP. PSA-RE bits 1.3-1.0. ";
CM_ SG_ 1603 FirstFrameLength "TRANSPORT_CANDIDATE: normal-addressing ISO-TP. PSA-RE bits 1.3-2.0. 12-bit declared PDU length; not a reassembled value.";
CM_ SG_ 1603 SingleFrameLength "TRANSPORT_CANDIDATE: normal-addressing ISO-TP. PSA-RE bits 1.3-1.0. Declared data length; not a validity check.";
CM_ SG_ 1603 IsoTpFrameType "TRANSPORT_CANDIDATE: normal-addressing ISO-TP. PSA-RE bits 1.7-1.4. PCI high nibble; normal addressing candidate.";
CM_ BO_ 1604 "DATABASE_CANDIDATE: physical interpretation unverified; capture/layout evidence reported separately. INFO-DIV CAN, 125000 bit/s; CAN ID 0x644. PSA-RE title: ON_CAN_DIAG_RESPONSE_6. Diagnostic response sent by the RBG ECU. Source: https://github.com/prototux/PSA-RE/blob/67f7581e7622410efdbb29c7eda3b86982b9b450/buses/AEE2010.full/LS.INFO-DIV/644.yml. Source sender alternatives: BSI; physical TX/gateway forwarding not verified. WIRE ISO-TP ONLY: normal addressing candidate, maximum Classical CAN DLC 8; actual DLC may be shorter. Data includes padding. No reassembly, text, DID or application-layer decoding. Original application layouts are preserved in source JSON; do not decode them at wire offsets. ";
CM_ SG_ 1604 FlowPadding5 "TRANSPORT_CANDIDATE: normal-addressing ISO-TP. PSA-RE bits 8.7-8.0. ";
CM_ SG_ 1604 FirstData6 "TRANSPORT_CANDIDATE: normal-addressing ISO-TP. PSA-RE bits 8.7-8.0. ";
CM_ SG_ 1604 UnknownData7 "TRANSPORT_CANDIDATE: normal-addressing ISO-TP. PSA-RE bits 8.7-8.0. ";
CM_ SG_ 1604 ConsecutiveData7 "TRANSPORT_CANDIDATE: normal-addressing ISO-TP. PSA-RE bits 8.7-8.0. ";
CM_ SG_ 1604 SingleData7 "TRANSPORT_CANDIDATE: normal-addressing ISO-TP. PSA-RE bits 8.7-8.0. ";
CM_ SG_ 1604 FlowPadding4 "TRANSPORT_CANDIDATE: normal-addressing ISO-TP. PSA-RE bits 7.7-7.0. ";
CM_ SG_ 1604 FirstData5 "TRANSPORT_CANDIDATE: normal-addressing ISO-TP. PSA-RE bits 7.7-7.0. ";
CM_ SG_ 1604 UnknownData6 "TRANSPORT_CANDIDATE: normal-addressing ISO-TP. PSA-RE bits 7.7-7.0. ";
CM_ SG_ 1604 ConsecutiveData6 "TRANSPORT_CANDIDATE: normal-addressing ISO-TP. PSA-RE bits 7.7-7.0. ";
CM_ SG_ 1604 SingleData6 "TRANSPORT_CANDIDATE: normal-addressing ISO-TP. PSA-RE bits 7.7-7.0. ";
CM_ SG_ 1604 FlowPadding3 "TRANSPORT_CANDIDATE: normal-addressing ISO-TP. PSA-RE bits 6.7-6.0. ";
CM_ SG_ 1604 FirstData4 "TRANSPORT_CANDIDATE: normal-addressing ISO-TP. PSA-RE bits 6.7-6.0. ";
CM_ SG_ 1604 UnknownData5 "TRANSPORT_CANDIDATE: normal-addressing ISO-TP. PSA-RE bits 6.7-6.0. ";
CM_ SG_ 1604 ConsecutiveData5 "TRANSPORT_CANDIDATE: normal-addressing ISO-TP. PSA-RE bits 6.7-6.0. ";
CM_ SG_ 1604 SingleData5 "TRANSPORT_CANDIDATE: normal-addressing ISO-TP. PSA-RE bits 6.7-6.0. ";
CM_ SG_ 1604 FlowPadding2 "TRANSPORT_CANDIDATE: normal-addressing ISO-TP. PSA-RE bits 5.7-5.0. ";
CM_ SG_ 1604 FirstData3 "TRANSPORT_CANDIDATE: normal-addressing ISO-TP. PSA-RE bits 5.7-5.0. ";
CM_ SG_ 1604 UnknownData4 "TRANSPORT_CANDIDATE: normal-addressing ISO-TP. PSA-RE bits 5.7-5.0. ";
CM_ SG_ 1604 ConsecutiveData4 "TRANSPORT_CANDIDATE: normal-addressing ISO-TP. PSA-RE bits 5.7-5.0. ";
CM_ SG_ 1604 SingleData4 "TRANSPORT_CANDIDATE: normal-addressing ISO-TP. PSA-RE bits 5.7-5.0. ";
CM_ SG_ 1604 FlowPadding1 "TRANSPORT_CANDIDATE: normal-addressing ISO-TP. PSA-RE bits 4.7-4.0. ";
CM_ SG_ 1604 FirstData2 "TRANSPORT_CANDIDATE: normal-addressing ISO-TP. PSA-RE bits 4.7-4.0. ";
CM_ SG_ 1604 UnknownData3 "TRANSPORT_CANDIDATE: normal-addressing ISO-TP. PSA-RE bits 4.7-4.0. ";
CM_ SG_ 1604 ConsecutiveData3 "TRANSPORT_CANDIDATE: normal-addressing ISO-TP. PSA-RE bits 4.7-4.0. ";
CM_ SG_ 1604 SingleData3 "TRANSPORT_CANDIDATE: normal-addressing ISO-TP. PSA-RE bits 4.7-4.0. ";
CM_ SG_ 1604 FirstData1 "TRANSPORT_CANDIDATE: normal-addressing ISO-TP. PSA-RE bits 3.7-3.0. ";
CM_ SG_ 1604 UnknownData2 "TRANSPORT_CANDIDATE: normal-addressing ISO-TP. PSA-RE bits 3.7-3.0. ";
CM_ SG_ 1604 ConsecutiveData2 "TRANSPORT_CANDIDATE: normal-addressing ISO-TP. PSA-RE bits 3.7-3.0. ";
CM_ SG_ 1604 SingleData2 "TRANSPORT_CANDIDATE: normal-addressing ISO-TP. PSA-RE bits 3.7-3.0. ";
CM_ SG_ 1604 SeparationTimeRaw "TRANSPORT_CANDIDATE: normal-addressing ISO-TP. PSA-RE bits 3.7-3.0. Raw STmin code; 0xF1..0xF9 are not milliseconds.";
CM_ SG_ 1604 UnknownData1 "TRANSPORT_CANDIDATE: normal-addressing ISO-TP. PSA-RE bits 2.7-2.0. ";
CM_ SG_ 1604 ConsecutiveData1 "TRANSPORT_CANDIDATE: normal-addressing ISO-TP. PSA-RE bits 2.7-2.0. ";
CM_ SG_ 1604 SingleData1 "TRANSPORT_CANDIDATE: normal-addressing ISO-TP. PSA-RE bits 2.7-2.0. ";
CM_ SG_ 1604 BlockSize "TRANSPORT_CANDIDATE: normal-addressing ISO-TP. PSA-RE bits 2.7-2.0. ";
CM_ SG_ 1604 UnknownPciLow "TRANSPORT_CANDIDATE: normal-addressing ISO-TP. PSA-RE bits 1.3-1.0. ";
CM_ SG_ 1604 FlowStatus "TRANSPORT_CANDIDATE: normal-addressing ISO-TP. PSA-RE bits 1.3-1.0. ";
CM_ SG_ 1604 ConsecutiveSequence "TRANSPORT_CANDIDATE: normal-addressing ISO-TP. PSA-RE bits 1.3-1.0. ";
CM_ SG_ 1604 FirstFrameLength "TRANSPORT_CANDIDATE: normal-addressing ISO-TP. PSA-RE bits 1.3-2.0. 12-bit declared PDU length; not a reassembled value.";
CM_ SG_ 1604 SingleFrameLength "TRANSPORT_CANDIDATE: normal-addressing ISO-TP. PSA-RE bits 1.3-1.0. Declared data length; not a validity check.";
CM_ SG_ 1604 IsoTpFrameType "TRANSPORT_CANDIDATE: normal-addressing ISO-TP. PSA-RE bits 1.7-1.4. PCI high nibble; normal addressing candidate.";
CM_ BO_ 1605 "DATABASE_CANDIDATE: physical interpretation unverified; capture/layout evidence reported separately. INFO-DIV CAN, 125000 bit/s; CAN ID 0x645. PSA-RE title: LCE_DIAG_RESPONSE. Diagnostic response sent by the LCE ECU. Source: https://github.com/prototux/PSA-RE/blob/67f7581e7622410efdbb29c7eda3b86982b9b450/buses/AEE2010.full/LS.INFO-DIV/645.yml. Source sender alternatives: BSI; physical TX/gateway forwarding not verified. WIRE ISO-TP ONLY: normal addressing candidate, maximum Classical CAN DLC 8; actual DLC may be shorter. Data includes padding. No reassembly, text, DID or application-layer decoding. Original application layouts are preserved in source JSON; do not decode them at wire offsets. ";
CM_ SG_ 1605 FlowPadding5 "TRANSPORT_CANDIDATE: normal-addressing ISO-TP. PSA-RE bits 8.7-8.0. ";
CM_ SG_ 1605 FirstData6 "TRANSPORT_CANDIDATE: normal-addressing ISO-TP. PSA-RE bits 8.7-8.0. ";
CM_ SG_ 1605 UnknownData7 "TRANSPORT_CANDIDATE: normal-addressing ISO-TP. PSA-RE bits 8.7-8.0. ";
CM_ SG_ 1605 ConsecutiveData7 "TRANSPORT_CANDIDATE: normal-addressing ISO-TP. PSA-RE bits 8.7-8.0. ";
CM_ SG_ 1605 SingleData7 "TRANSPORT_CANDIDATE: normal-addressing ISO-TP. PSA-RE bits 8.7-8.0. ";
CM_ SG_ 1605 FlowPadding4 "TRANSPORT_CANDIDATE: normal-addressing ISO-TP. PSA-RE bits 7.7-7.0. ";
CM_ SG_ 1605 FirstData5 "TRANSPORT_CANDIDATE: normal-addressing ISO-TP. PSA-RE bits 7.7-7.0. ";
CM_ SG_ 1605 UnknownData6 "TRANSPORT_CANDIDATE: normal-addressing ISO-TP. PSA-RE bits 7.7-7.0. ";
CM_ SG_ 1605 ConsecutiveData6 "TRANSPORT_CANDIDATE: normal-addressing ISO-TP. PSA-RE bits 7.7-7.0. ";
CM_ SG_ 1605 SingleData6 "TRANSPORT_CANDIDATE: normal-addressing ISO-TP. PSA-RE bits 7.7-7.0. ";
CM_ SG_ 1605 FlowPadding3 "TRANSPORT_CANDIDATE: normal-addressing ISO-TP. PSA-RE bits 6.7-6.0. ";
CM_ SG_ 1605 FirstData4 "TRANSPORT_CANDIDATE: normal-addressing ISO-TP. PSA-RE bits 6.7-6.0. ";
CM_ SG_ 1605 UnknownData5 "TRANSPORT_CANDIDATE: normal-addressing ISO-TP. PSA-RE bits 6.7-6.0. ";
CM_ SG_ 1605 ConsecutiveData5 "TRANSPORT_CANDIDATE: normal-addressing ISO-TP. PSA-RE bits 6.7-6.0. ";
CM_ SG_ 1605 SingleData5 "TRANSPORT_CANDIDATE: normal-addressing ISO-TP. PSA-RE bits 6.7-6.0. ";
CM_ SG_ 1605 FlowPadding2 "TRANSPORT_CANDIDATE: normal-addressing ISO-TP. PSA-RE bits 5.7-5.0. ";
CM_ SG_ 1605 FirstData3 "TRANSPORT_CANDIDATE: normal-addressing ISO-TP. PSA-RE bits 5.7-5.0. ";
CM_ SG_ 1605 UnknownData4 "TRANSPORT_CANDIDATE: normal-addressing ISO-TP. PSA-RE bits 5.7-5.0. ";
CM_ SG_ 1605 ConsecutiveData4 "TRANSPORT_CANDIDATE: normal-addressing ISO-TP. PSA-RE bits 5.7-5.0. ";
CM_ SG_ 1605 SingleData4 "TRANSPORT_CANDIDATE: normal-addressing ISO-TP. PSA-RE bits 5.7-5.0. ";
CM_ SG_ 1605 FlowPadding1 "TRANSPORT_CANDIDATE: normal-addressing ISO-TP. PSA-RE bits 4.7-4.0. ";
CM_ SG_ 1605 FirstData2 "TRANSPORT_CANDIDATE: normal-addressing ISO-TP. PSA-RE bits 4.7-4.0. ";
CM_ SG_ 1605 UnknownData3 "TRANSPORT_CANDIDATE: normal-addressing ISO-TP. PSA-RE bits 4.7-4.0. ";
CM_ SG_ 1605 ConsecutiveData3 "TRANSPORT_CANDIDATE: normal-addressing ISO-TP. PSA-RE bits 4.7-4.0. ";
CM_ SG_ 1605 SingleData3 "TRANSPORT_CANDIDATE: normal-addressing ISO-TP. PSA-RE bits 4.7-4.0. ";
CM_ SG_ 1605 FirstData1 "TRANSPORT_CANDIDATE: normal-addressing ISO-TP. PSA-RE bits 3.7-3.0. ";
CM_ SG_ 1605 UnknownData2 "TRANSPORT_CANDIDATE: normal-addressing ISO-TP. PSA-RE bits 3.7-3.0. ";
CM_ SG_ 1605 ConsecutiveData2 "TRANSPORT_CANDIDATE: normal-addressing ISO-TP. PSA-RE bits 3.7-3.0. ";
CM_ SG_ 1605 SingleData2 "TRANSPORT_CANDIDATE: normal-addressing ISO-TP. PSA-RE bits 3.7-3.0. ";
CM_ SG_ 1605 SeparationTimeRaw "TRANSPORT_CANDIDATE: normal-addressing ISO-TP. PSA-RE bits 3.7-3.0. Raw STmin code; 0xF1..0xF9 are not milliseconds.";
CM_ SG_ 1605 UnknownData1 "TRANSPORT_CANDIDATE: normal-addressing ISO-TP. PSA-RE bits 2.7-2.0. ";
CM_ SG_ 1605 ConsecutiveData1 "TRANSPORT_CANDIDATE: normal-addressing ISO-TP. PSA-RE bits 2.7-2.0. ";
CM_ SG_ 1605 SingleData1 "TRANSPORT_CANDIDATE: normal-addressing ISO-TP. PSA-RE bits 2.7-2.0. ";
CM_ SG_ 1605 BlockSize "TRANSPORT_CANDIDATE: normal-addressing ISO-TP. PSA-RE bits 2.7-2.0. ";
CM_ SG_ 1605 UnknownPciLow "TRANSPORT_CANDIDATE: normal-addressing ISO-TP. PSA-RE bits 1.3-1.0. ";
CM_ SG_ 1605 FlowStatus "TRANSPORT_CANDIDATE: normal-addressing ISO-TP. PSA-RE bits 1.3-1.0. ";
CM_ SG_ 1605 ConsecutiveSequence "TRANSPORT_CANDIDATE: normal-addressing ISO-TP. PSA-RE bits 1.3-1.0. ";
CM_ SG_ 1605 FirstFrameLength "TRANSPORT_CANDIDATE: normal-addressing ISO-TP. PSA-RE bits 1.3-2.0. 12-bit declared PDU length; not a reassembled value.";
CM_ SG_ 1605 SingleFrameLength "TRANSPORT_CANDIDATE: normal-addressing ISO-TP. PSA-RE bits 1.3-1.0. Declared data length; not a validity check.";
CM_ SG_ 1605 IsoTpFrameType "TRANSPORT_CANDIDATE: normal-addressing ISO-TP. PSA-RE bits 1.7-1.4. PCI high nibble; normal addressing candidate.";
CM_ BO_ 1606 "DATABASE_CANDIDATE: physical interpretation unverified; capture/layout evidence reported separately. INFO-DIV CAN, 125000 bit/s; CAN ID 0x646. PSA-RE title: RHF_DIAG_RESPONSE. Diagnostic response sent by the RHF ECU. Source: https://github.com/prototux/PSA-RE/blob/67f7581e7622410efdbb29c7eda3b86982b9b450/buses/AEE2010.full/LS.INFO-DIV/646.yml. Source sender alternatives: BSI; physical TX/gateway forwarding not verified. WIRE ISO-TP ONLY: normal addressing candidate, maximum Classical CAN DLC 8; actual DLC may be shorter. Data includes padding. No reassembly, text, DID or application-layer decoding. Original application layouts are preserved in source JSON; do not decode them at wire offsets. ";
CM_ SG_ 1606 FlowPadding5 "TRANSPORT_CANDIDATE: normal-addressing ISO-TP. PSA-RE bits 8.7-8.0. ";
CM_ SG_ 1606 FirstData6 "TRANSPORT_CANDIDATE: normal-addressing ISO-TP. PSA-RE bits 8.7-8.0. ";
CM_ SG_ 1606 UnknownData7 "TRANSPORT_CANDIDATE: normal-addressing ISO-TP. PSA-RE bits 8.7-8.0. ";
CM_ SG_ 1606 ConsecutiveData7 "TRANSPORT_CANDIDATE: normal-addressing ISO-TP. PSA-RE bits 8.7-8.0. ";
CM_ SG_ 1606 SingleData7 "TRANSPORT_CANDIDATE: normal-addressing ISO-TP. PSA-RE bits 8.7-8.0. ";
CM_ SG_ 1606 FlowPadding4 "TRANSPORT_CANDIDATE: normal-addressing ISO-TP. PSA-RE bits 7.7-7.0. ";
CM_ SG_ 1606 FirstData5 "TRANSPORT_CANDIDATE: normal-addressing ISO-TP. PSA-RE bits 7.7-7.0. ";
CM_ SG_ 1606 UnknownData6 "TRANSPORT_CANDIDATE: normal-addressing ISO-TP. PSA-RE bits 7.7-7.0. ";
CM_ SG_ 1606 ConsecutiveData6 "TRANSPORT_CANDIDATE: normal-addressing ISO-TP. PSA-RE bits 7.7-7.0. ";
CM_ SG_ 1606 SingleData6 "TRANSPORT_CANDIDATE: normal-addressing ISO-TP. PSA-RE bits 7.7-7.0. ";
CM_ SG_ 1606 FlowPadding3 "TRANSPORT_CANDIDATE: normal-addressing ISO-TP. PSA-RE bits 6.7-6.0. ";
CM_ SG_ 1606 FirstData4 "TRANSPORT_CANDIDATE: normal-addressing ISO-TP. PSA-RE bits 6.7-6.0. ";
CM_ SG_ 1606 UnknownData5 "TRANSPORT_CANDIDATE: normal-addressing ISO-TP. PSA-RE bits 6.7-6.0. ";
CM_ SG_ 1606 ConsecutiveData5 "TRANSPORT_CANDIDATE: normal-addressing ISO-TP. PSA-RE bits 6.7-6.0. ";
CM_ SG_ 1606 SingleData5 "TRANSPORT_CANDIDATE: normal-addressing ISO-TP. PSA-RE bits 6.7-6.0. ";
CM_ SG_ 1606 FlowPadding2 "TRANSPORT_CANDIDATE: normal-addressing ISO-TP. PSA-RE bits 5.7-5.0. ";
CM_ SG_ 1606 FirstData3 "TRANSPORT_CANDIDATE: normal-addressing ISO-TP. PSA-RE bits 5.7-5.0. ";
CM_ SG_ 1606 UnknownData4 "TRANSPORT_CANDIDATE: normal-addressing ISO-TP. PSA-RE bits 5.7-5.0. ";
CM_ SG_ 1606 ConsecutiveData4 "TRANSPORT_CANDIDATE: normal-addressing ISO-TP. PSA-RE bits 5.7-5.0. ";
CM_ SG_ 1606 SingleData4 "TRANSPORT_CANDIDATE: normal-addressing ISO-TP. PSA-RE bits 5.7-5.0. ";
CM_ SG_ 1606 FlowPadding1 "TRANSPORT_CANDIDATE: normal-addressing ISO-TP. PSA-RE bits 4.7-4.0. ";
CM_ SG_ 1606 FirstData2 "TRANSPORT_CANDIDATE: normal-addressing ISO-TP. PSA-RE bits 4.7-4.0. ";
CM_ SG_ 1606 UnknownData3 "TRANSPORT_CANDIDATE: normal-addressing ISO-TP. PSA-RE bits 4.7-4.0. ";
CM_ SG_ 1606 ConsecutiveData3 "TRANSPORT_CANDIDATE: normal-addressing ISO-TP. PSA-RE bits 4.7-4.0. ";
CM_ SG_ 1606 SingleData3 "TRANSPORT_CANDIDATE: normal-addressing ISO-TP. PSA-RE bits 4.7-4.0. ";
CM_ SG_ 1606 FirstData1 "TRANSPORT_CANDIDATE: normal-addressing ISO-TP. PSA-RE bits 3.7-3.0. ";
CM_ SG_ 1606 UnknownData2 "TRANSPORT_CANDIDATE: normal-addressing ISO-TP. PSA-RE bits 3.7-3.0. ";
CM_ SG_ 1606 ConsecutiveData2 "TRANSPORT_CANDIDATE: normal-addressing ISO-TP. PSA-RE bits 3.7-3.0. ";
CM_ SG_ 1606 SingleData2 "TRANSPORT_CANDIDATE: normal-addressing ISO-TP. PSA-RE bits 3.7-3.0. ";
CM_ SG_ 1606 SeparationTimeRaw "TRANSPORT_CANDIDATE: normal-addressing ISO-TP. PSA-RE bits 3.7-3.0. Raw STmin code; 0xF1..0xF9 are not milliseconds.";
CM_ SG_ 1606 UnknownData1 "TRANSPORT_CANDIDATE: normal-addressing ISO-TP. PSA-RE bits 2.7-2.0. ";
CM_ SG_ 1606 ConsecutiveData1 "TRANSPORT_CANDIDATE: normal-addressing ISO-TP. PSA-RE bits 2.7-2.0. ";
CM_ SG_ 1606 SingleData1 "TRANSPORT_CANDIDATE: normal-addressing ISO-TP. PSA-RE bits 2.7-2.0. ";
CM_ SG_ 1606 BlockSize "TRANSPORT_CANDIDATE: normal-addressing ISO-TP. PSA-RE bits 2.7-2.0. ";
CM_ SG_ 1606 UnknownPciLow "TRANSPORT_CANDIDATE: normal-addressing ISO-TP. PSA-RE bits 1.3-1.0. ";
CM_ SG_ 1606 FlowStatus "TRANSPORT_CANDIDATE: normal-addressing ISO-TP. PSA-RE bits 1.3-1.0. ";
CM_ SG_ 1606 ConsecutiveSequence "TRANSPORT_CANDIDATE: normal-addressing ISO-TP. PSA-RE bits 1.3-1.0. ";
CM_ SG_ 1606 FirstFrameLength "TRANSPORT_CANDIDATE: normal-addressing ISO-TP. PSA-RE bits 1.3-2.0. 12-bit declared PDU length; not a reassembled value.";
CM_ SG_ 1606 SingleFrameLength "TRANSPORT_CANDIDATE: normal-addressing ISO-TP. PSA-RE bits 1.3-1.0. Declared data length; not a validity check.";
CM_ SG_ 1606 IsoTpFrameType "TRANSPORT_CANDIDATE: normal-addressing ISO-TP. PSA-RE bits 1.7-1.4. PCI high nibble; normal addressing candidate.";
CM_ BO_ 1607 "DATABASE_CANDIDATE: physical interpretation unverified; capture/layout evidence reported separately. INFO-DIV CAN, 125000 bit/s; CAN ID 0x647. PSA-RE title: BSM_DIAG_RESPONSE. Diagnostic response sent by the BSM ECU. Source: https://github.com/prototux/PSA-RE/blob/67f7581e7622410efdbb29c7eda3b86982b9b450/buses/AEE2010.full/LS.INFO-DIV/647.yml. Source sender alternatives: BSI; physical TX/gateway forwarding not verified. WIRE ISO-TP ONLY: normal addressing candidate, maximum Classical CAN DLC 8; actual DLC may be shorter. Data includes padding. No reassembly, text, DID or application-layer decoding. Original application layouts are preserved in source JSON; do not decode them at wire offsets. ";
CM_ SG_ 1607 FlowPadding5 "TRANSPORT_CANDIDATE: normal-addressing ISO-TP. PSA-RE bits 8.7-8.0. ";
CM_ SG_ 1607 FirstData6 "TRANSPORT_CANDIDATE: normal-addressing ISO-TP. PSA-RE bits 8.7-8.0. ";
CM_ SG_ 1607 UnknownData7 "TRANSPORT_CANDIDATE: normal-addressing ISO-TP. PSA-RE bits 8.7-8.0. ";
CM_ SG_ 1607 ConsecutiveData7 "TRANSPORT_CANDIDATE: normal-addressing ISO-TP. PSA-RE bits 8.7-8.0. ";
CM_ SG_ 1607 SingleData7 "TRANSPORT_CANDIDATE: normal-addressing ISO-TP. PSA-RE bits 8.7-8.0. ";
CM_ SG_ 1607 FlowPadding4 "TRANSPORT_CANDIDATE: normal-addressing ISO-TP. PSA-RE bits 7.7-7.0. ";
CM_ SG_ 1607 FirstData5 "TRANSPORT_CANDIDATE: normal-addressing ISO-TP. PSA-RE bits 7.7-7.0. ";
CM_ SG_ 1607 UnknownData6 "TRANSPORT_CANDIDATE: normal-addressing ISO-TP. PSA-RE bits 7.7-7.0. ";
CM_ SG_ 1607 ConsecutiveData6 "TRANSPORT_CANDIDATE: normal-addressing ISO-TP. PSA-RE bits 7.7-7.0. ";
CM_ SG_ 1607 SingleData6 "TRANSPORT_CANDIDATE: normal-addressing ISO-TP. PSA-RE bits 7.7-7.0. ";
CM_ SG_ 1607 FlowPadding3 "TRANSPORT_CANDIDATE: normal-addressing ISO-TP. PSA-RE bits 6.7-6.0. ";
CM_ SG_ 1607 FirstData4 "TRANSPORT_CANDIDATE: normal-addressing ISO-TP. PSA-RE bits 6.7-6.0. ";
CM_ SG_ 1607 UnknownData5 "TRANSPORT_CANDIDATE: normal-addressing ISO-TP. PSA-RE bits 6.7-6.0. ";
CM_ SG_ 1607 ConsecutiveData5 "TRANSPORT_CANDIDATE: normal-addressing ISO-TP. PSA-RE bits 6.7-6.0. ";
CM_ SG_ 1607 SingleData5 "TRANSPORT_CANDIDATE: normal-addressing ISO-TP. PSA-RE bits 6.7-6.0. ";
CM_ SG_ 1607 FlowPadding2 "TRANSPORT_CANDIDATE: normal-addressing ISO-TP. PSA-RE bits 5.7-5.0. ";
CM_ SG_ 1607 FirstData3 "TRANSPORT_CANDIDATE: normal-addressing ISO-TP. PSA-RE bits 5.7-5.0. ";
CM_ SG_ 1607 UnknownData4 "TRANSPORT_CANDIDATE: normal-addressing ISO-TP. PSA-RE bits 5.7-5.0. ";
CM_ SG_ 1607 ConsecutiveData4 "TRANSPORT_CANDIDATE: normal-addressing ISO-TP. PSA-RE bits 5.7-5.0. ";
CM_ SG_ 1607 SingleData4 "TRANSPORT_CANDIDATE: normal-addressing ISO-TP. PSA-RE bits 5.7-5.0. ";
CM_ SG_ 1607 FlowPadding1 "TRANSPORT_CANDIDATE: normal-addressing ISO-TP. PSA-RE bits 4.7-4.0. ";
CM_ SG_ 1607 FirstData2 "TRANSPORT_CANDIDATE: normal-addressing ISO-TP. PSA-RE bits 4.7-4.0. ";
CM_ SG_ 1607 UnknownData3 "TRANSPORT_CANDIDATE: normal-addressing ISO-TP. PSA-RE bits 4.7-4.0. ";
CM_ SG_ 1607 ConsecutiveData3 "TRANSPORT_CANDIDATE: normal-addressing ISO-TP. PSA-RE bits 4.7-4.0. ";
CM_ SG_ 1607 SingleData3 "TRANSPORT_CANDIDATE: normal-addressing ISO-TP. PSA-RE bits 4.7-4.0. ";
CM_ SG_ 1607 FirstData1 "TRANSPORT_CANDIDATE: normal-addressing ISO-TP. PSA-RE bits 3.7-3.0. ";
CM_ SG_ 1607 UnknownData2 "TRANSPORT_CANDIDATE: normal-addressing ISO-TP. PSA-RE bits 3.7-3.0. ";
CM_ SG_ 1607 ConsecutiveData2 "TRANSPORT_CANDIDATE: normal-addressing ISO-TP. PSA-RE bits 3.7-3.0. ";
CM_ SG_ 1607 SingleData2 "TRANSPORT_CANDIDATE: normal-addressing ISO-TP. PSA-RE bits 3.7-3.0. ";
CM_ SG_ 1607 SeparationTimeRaw "TRANSPORT_CANDIDATE: normal-addressing ISO-TP. PSA-RE bits 3.7-3.0. Raw STmin code; 0xF1..0xF9 are not milliseconds.";
CM_ SG_ 1607 UnknownData1 "TRANSPORT_CANDIDATE: normal-addressing ISO-TP. PSA-RE bits 2.7-2.0. ";
CM_ SG_ 1607 ConsecutiveData1 "TRANSPORT_CANDIDATE: normal-addressing ISO-TP. PSA-RE bits 2.7-2.0. ";
CM_ SG_ 1607 SingleData1 "TRANSPORT_CANDIDATE: normal-addressing ISO-TP. PSA-RE bits 2.7-2.0. ";
CM_ SG_ 1607 BlockSize "TRANSPORT_CANDIDATE: normal-addressing ISO-TP. PSA-RE bits 2.7-2.0. ";
CM_ SG_ 1607 UnknownPciLow "TRANSPORT_CANDIDATE: normal-addressing ISO-TP. PSA-RE bits 1.3-1.0. ";
CM_ SG_ 1607 FlowStatus "TRANSPORT_CANDIDATE: normal-addressing ISO-TP. PSA-RE bits 1.3-1.0. ";
CM_ SG_ 1607 ConsecutiveSequence "TRANSPORT_CANDIDATE: normal-addressing ISO-TP. PSA-RE bits 1.3-1.0. ";
CM_ SG_ 1607 FirstFrameLength "TRANSPORT_CANDIDATE: normal-addressing ISO-TP. PSA-RE bits 1.3-2.0. 12-bit declared PDU length; not a reassembled value.";
CM_ SG_ 1607 SingleFrameLength "TRANSPORT_CANDIDATE: normal-addressing ISO-TP. PSA-RE bits 1.3-1.0. Declared data length; not a validity check.";
CM_ SG_ 1607 IsoTpFrameType "TRANSPORT_CANDIDATE: normal-addressing ISO-TP. PSA-RE bits 1.7-1.4. PCI high nibble; normal addressing candidate.";
CM_ BO_ 1608 "DATABASE_CANDIDATE: physical interpretation unverified; capture/layout evidence reported separately. INFO-DIV CAN, 125000 bit/s; CAN ID 0x648. PSA-RE title: BSG_TC_DIAG_RESPONSE. Diagnostic response sent by the BSG ECU. Source: https://github.com/prototux/PSA-RE/blob/67f7581e7622410efdbb29c7eda3b86982b9b450/buses/AEE2010.full/LS.INFO-DIV/648.yml. Source sender alternatives: BSI; physical TX/gateway forwarding not verified. WIRE ISO-TP ONLY: normal addressing candidate, maximum Classical CAN DLC 8; actual DLC may be shorter. Data includes padding. No reassembly, text, DID or application-layer decoding. Original application layouts are preserved in source JSON; do not decode them at wire offsets. ";
CM_ SG_ 1608 FlowPadding5 "TRANSPORT_CANDIDATE: normal-addressing ISO-TP. PSA-RE bits 8.7-8.0. ";
CM_ SG_ 1608 FirstData6 "TRANSPORT_CANDIDATE: normal-addressing ISO-TP. PSA-RE bits 8.7-8.0. ";
CM_ SG_ 1608 UnknownData7 "TRANSPORT_CANDIDATE: normal-addressing ISO-TP. PSA-RE bits 8.7-8.0. ";
CM_ SG_ 1608 ConsecutiveData7 "TRANSPORT_CANDIDATE: normal-addressing ISO-TP. PSA-RE bits 8.7-8.0. ";
CM_ SG_ 1608 SingleData7 "TRANSPORT_CANDIDATE: normal-addressing ISO-TP. PSA-RE bits 8.7-8.0. ";
CM_ SG_ 1608 FlowPadding4 "TRANSPORT_CANDIDATE: normal-addressing ISO-TP. PSA-RE bits 7.7-7.0. ";
CM_ SG_ 1608 FirstData5 "TRANSPORT_CANDIDATE: normal-addressing ISO-TP. PSA-RE bits 7.7-7.0. ";
CM_ SG_ 1608 UnknownData6 "TRANSPORT_CANDIDATE: normal-addressing ISO-TP. PSA-RE bits 7.7-7.0. ";
CM_ SG_ 1608 ConsecutiveData6 "TRANSPORT_CANDIDATE: normal-addressing ISO-TP. PSA-RE bits 7.7-7.0. ";
CM_ SG_ 1608 SingleData6 "TRANSPORT_CANDIDATE: normal-addressing ISO-TP. PSA-RE bits 7.7-7.0. ";
CM_ SG_ 1608 FlowPadding3 "TRANSPORT_CANDIDATE: normal-addressing ISO-TP. PSA-RE bits 6.7-6.0. ";
CM_ SG_ 1608 FirstData4 "TRANSPORT_CANDIDATE: normal-addressing ISO-TP. PSA-RE bits 6.7-6.0. ";
CM_ SG_ 1608 UnknownData5 "TRANSPORT_CANDIDATE: normal-addressing ISO-TP. PSA-RE bits 6.7-6.0. ";
CM_ SG_ 1608 ConsecutiveData5 "TRANSPORT_CANDIDATE: normal-addressing ISO-TP. PSA-RE bits 6.7-6.0. ";
CM_ SG_ 1608 SingleData5 "TRANSPORT_CANDIDATE: normal-addressing ISO-TP. PSA-RE bits 6.7-6.0. ";
CM_ SG_ 1608 FlowPadding2 "TRANSPORT_CANDIDATE: normal-addressing ISO-TP. PSA-RE bits 5.7-5.0. ";
CM_ SG_ 1608 FirstData3 "TRANSPORT_CANDIDATE: normal-addressing ISO-TP. PSA-RE bits 5.7-5.0. ";
CM_ SG_ 1608 UnknownData4 "TRANSPORT_CANDIDATE: normal-addressing ISO-TP. PSA-RE bits 5.7-5.0. ";
CM_ SG_ 1608 ConsecutiveData4 "TRANSPORT_CANDIDATE: normal-addressing ISO-TP. PSA-RE bits 5.7-5.0. ";
CM_ SG_ 1608 SingleData4 "TRANSPORT_CANDIDATE: normal-addressing ISO-TP. PSA-RE bits 5.7-5.0. ";
CM_ SG_ 1608 FlowPadding1 "TRANSPORT_CANDIDATE: normal-addressing ISO-TP. PSA-RE bits 4.7-4.0. ";
CM_ SG_ 1608 FirstData2 "TRANSPORT_CANDIDATE: normal-addressing ISO-TP. PSA-RE bits 4.7-4.0. ";
CM_ SG_ 1608 UnknownData3 "TRANSPORT_CANDIDATE: normal-addressing ISO-TP. PSA-RE bits 4.7-4.0. ";
CM_ SG_ 1608 ConsecutiveData3 "TRANSPORT_CANDIDATE: normal-addressing ISO-TP. PSA-RE bits 4.7-4.0. ";
CM_ SG_ 1608 SingleData3 "TRANSPORT_CANDIDATE: normal-addressing ISO-TP. PSA-RE bits 4.7-4.0. ";
CM_ SG_ 1608 FirstData1 "TRANSPORT_CANDIDATE: normal-addressing ISO-TP. PSA-RE bits 3.7-3.0. ";
CM_ SG_ 1608 UnknownData2 "TRANSPORT_CANDIDATE: normal-addressing ISO-TP. PSA-RE bits 3.7-3.0. ";
CM_ SG_ 1608 ConsecutiveData2 "TRANSPORT_CANDIDATE: normal-addressing ISO-TP. PSA-RE bits 3.7-3.0. ";
CM_ SG_ 1608 SingleData2 "TRANSPORT_CANDIDATE: normal-addressing ISO-TP. PSA-RE bits 3.7-3.0. ";
CM_ SG_ 1608 SeparationTimeRaw "TRANSPORT_CANDIDATE: normal-addressing ISO-TP. PSA-RE bits 3.7-3.0. Raw STmin code; 0xF1..0xF9 are not milliseconds.";
CM_ SG_ 1608 UnknownData1 "TRANSPORT_CANDIDATE: normal-addressing ISO-TP. PSA-RE bits 2.7-2.0. ";
CM_ SG_ 1608 ConsecutiveData1 "TRANSPORT_CANDIDATE: normal-addressing ISO-TP. PSA-RE bits 2.7-2.0. ";
CM_ SG_ 1608 SingleData1 "TRANSPORT_CANDIDATE: normal-addressing ISO-TP. PSA-RE bits 2.7-2.0. ";
CM_ SG_ 1608 BlockSize "TRANSPORT_CANDIDATE: normal-addressing ISO-TP. PSA-RE bits 2.7-2.0. ";
CM_ SG_ 1608 UnknownPciLow "TRANSPORT_CANDIDATE: normal-addressing ISO-TP. PSA-RE bits 1.3-1.0. ";
CM_ SG_ 1608 FlowStatus "TRANSPORT_CANDIDATE: normal-addressing ISO-TP. PSA-RE bits 1.3-1.0. ";
CM_ SG_ 1608 ConsecutiveSequence "TRANSPORT_CANDIDATE: normal-addressing ISO-TP. PSA-RE bits 1.3-1.0. ";
CM_ SG_ 1608 FirstFrameLength "TRANSPORT_CANDIDATE: normal-addressing ISO-TP. PSA-RE bits 1.3-2.0. 12-bit declared PDU length; not a reassembled value.";
CM_ SG_ 1608 SingleFrameLength "TRANSPORT_CANDIDATE: normal-addressing ISO-TP. PSA-RE bits 1.3-1.0. Declared data length; not a validity check.";
CM_ SG_ 1608 IsoTpFrameType "TRANSPORT_CANDIDATE: normal-addressing ISO-TP. PSA-RE bits 1.7-1.4. PCI high nibble; normal addressing candidate.";
CM_ BO_ 1609 "DATABASE_CANDIDATE: physical interpretation unverified; capture/layout evidence reported separately. INFO-DIV CAN, 125000 bit/s; CAN ID 0x649. PSA-RE title: BDCP_DIAG_RESPONSE. Diagnostic response sent by the BDCP ECU. Source: https://github.com/prototux/PSA-RE/blob/67f7581e7622410efdbb29c7eda3b86982b9b450/buses/AEE2010.full/LS.INFO-DIV/649.yml. Source sender alternatives: BSI; physical TX/gateway forwarding not verified. WIRE ISO-TP ONLY: normal addressing candidate, maximum Classical CAN DLC 8; actual DLC may be shorter. Data includes padding. No reassembly, text, DID or application-layer decoding. Original application layouts are preserved in source JSON; do not decode them at wire offsets. ";
CM_ SG_ 1609 FlowPadding5 "TRANSPORT_CANDIDATE: normal-addressing ISO-TP. PSA-RE bits 8.7-8.0. ";
CM_ SG_ 1609 FirstData6 "TRANSPORT_CANDIDATE: normal-addressing ISO-TP. PSA-RE bits 8.7-8.0. ";
CM_ SG_ 1609 UnknownData7 "TRANSPORT_CANDIDATE: normal-addressing ISO-TP. PSA-RE bits 8.7-8.0. ";
CM_ SG_ 1609 ConsecutiveData7 "TRANSPORT_CANDIDATE: normal-addressing ISO-TP. PSA-RE bits 8.7-8.0. ";
CM_ SG_ 1609 SingleData7 "TRANSPORT_CANDIDATE: normal-addressing ISO-TP. PSA-RE bits 8.7-8.0. ";
CM_ SG_ 1609 FlowPadding4 "TRANSPORT_CANDIDATE: normal-addressing ISO-TP. PSA-RE bits 7.7-7.0. ";
CM_ SG_ 1609 FirstData5 "TRANSPORT_CANDIDATE: normal-addressing ISO-TP. PSA-RE bits 7.7-7.0. ";
CM_ SG_ 1609 UnknownData6 "TRANSPORT_CANDIDATE: normal-addressing ISO-TP. PSA-RE bits 7.7-7.0. ";
CM_ SG_ 1609 ConsecutiveData6 "TRANSPORT_CANDIDATE: normal-addressing ISO-TP. PSA-RE bits 7.7-7.0. ";
CM_ SG_ 1609 SingleData6 "TRANSPORT_CANDIDATE: normal-addressing ISO-TP. PSA-RE bits 7.7-7.0. ";
CM_ SG_ 1609 FlowPadding3 "TRANSPORT_CANDIDATE: normal-addressing ISO-TP. PSA-RE bits 6.7-6.0. ";
CM_ SG_ 1609 FirstData4 "TRANSPORT_CANDIDATE: normal-addressing ISO-TP. PSA-RE bits 6.7-6.0. ";
CM_ SG_ 1609 UnknownData5 "TRANSPORT_CANDIDATE: normal-addressing ISO-TP. PSA-RE bits 6.7-6.0. ";
CM_ SG_ 1609 ConsecutiveData5 "TRANSPORT_CANDIDATE: normal-addressing ISO-TP. PSA-RE bits 6.7-6.0. ";
CM_ SG_ 1609 SingleData5 "TRANSPORT_CANDIDATE: normal-addressing ISO-TP. PSA-RE bits 6.7-6.0. ";
CM_ SG_ 1609 FlowPadding2 "TRANSPORT_CANDIDATE: normal-addressing ISO-TP. PSA-RE bits 5.7-5.0. ";
CM_ SG_ 1609 FirstData3 "TRANSPORT_CANDIDATE: normal-addressing ISO-TP. PSA-RE bits 5.7-5.0. ";
CM_ SG_ 1609 UnknownData4 "TRANSPORT_CANDIDATE: normal-addressing ISO-TP. PSA-RE bits 5.7-5.0. ";
CM_ SG_ 1609 ConsecutiveData4 "TRANSPORT_CANDIDATE: normal-addressing ISO-TP. PSA-RE bits 5.7-5.0. ";
CM_ SG_ 1609 SingleData4 "TRANSPORT_CANDIDATE: normal-addressing ISO-TP. PSA-RE bits 5.7-5.0. ";
CM_ SG_ 1609 FlowPadding1 "TRANSPORT_CANDIDATE: normal-addressing ISO-TP. PSA-RE bits 4.7-4.0. ";
CM_ SG_ 1609 FirstData2 "TRANSPORT_CANDIDATE: normal-addressing ISO-TP. PSA-RE bits 4.7-4.0. ";
CM_ SG_ 1609 UnknownData3 "TRANSPORT_CANDIDATE: normal-addressing ISO-TP. PSA-RE bits 4.7-4.0. ";
CM_ SG_ 1609 ConsecutiveData3 "TRANSPORT_CANDIDATE: normal-addressing ISO-TP. PSA-RE bits 4.7-4.0. ";
CM_ SG_ 1609 SingleData3 "TRANSPORT_CANDIDATE: normal-addressing ISO-TP. PSA-RE bits 4.7-4.0. ";
CM_ SG_ 1609 FirstData1 "TRANSPORT_CANDIDATE: normal-addressing ISO-TP. PSA-RE bits 3.7-3.0. ";
CM_ SG_ 1609 UnknownData2 "TRANSPORT_CANDIDATE: normal-addressing ISO-TP. PSA-RE bits 3.7-3.0. ";
CM_ SG_ 1609 ConsecutiveData2 "TRANSPORT_CANDIDATE: normal-addressing ISO-TP. PSA-RE bits 3.7-3.0. ";
CM_ SG_ 1609 SingleData2 "TRANSPORT_CANDIDATE: normal-addressing ISO-TP. PSA-RE bits 3.7-3.0. ";
CM_ SG_ 1609 SeparationTimeRaw "TRANSPORT_CANDIDATE: normal-addressing ISO-TP. PSA-RE bits 3.7-3.0. Raw STmin code; 0xF1..0xF9 are not milliseconds.";
CM_ SG_ 1609 UnknownData1 "TRANSPORT_CANDIDATE: normal-addressing ISO-TP. PSA-RE bits 2.7-2.0. ";
CM_ SG_ 1609 ConsecutiveData1 "TRANSPORT_CANDIDATE: normal-addressing ISO-TP. PSA-RE bits 2.7-2.0. ";
CM_ SG_ 1609 SingleData1 "TRANSPORT_CANDIDATE: normal-addressing ISO-TP. PSA-RE bits 2.7-2.0. ";
CM_ SG_ 1609 BlockSize "TRANSPORT_CANDIDATE: normal-addressing ISO-TP. PSA-RE bits 2.7-2.0. ";
CM_ SG_ 1609 UnknownPciLow "TRANSPORT_CANDIDATE: normal-addressing ISO-TP. PSA-RE bits 1.3-1.0. ";
CM_ SG_ 1609 FlowStatus "TRANSPORT_CANDIDATE: normal-addressing ISO-TP. PSA-RE bits 1.3-1.0. ";
CM_ SG_ 1609 ConsecutiveSequence "TRANSPORT_CANDIDATE: normal-addressing ISO-TP. PSA-RE bits 1.3-1.0. ";
CM_ SG_ 1609 FirstFrameLength "TRANSPORT_CANDIDATE: normal-addressing ISO-TP. PSA-RE bits 1.3-2.0. 12-bit declared PDU length; not a reassembled value.";
CM_ SG_ 1609 SingleFrameLength "TRANSPORT_CANDIDATE: normal-addressing ISO-TP. PSA-RE bits 1.3-1.0. Declared data length; not a validity check.";
CM_ SG_ 1609 IsoTpFrameType "TRANSPORT_CANDIDATE: normal-addressing ISO-TP. PSA-RE bits 1.7-1.4. PCI high nibble; normal addressing candidate.";
CM_ BO_ 1610 "DATABASE_CANDIDATE: physical interpretation unverified; capture/layout evidence reported separately. INFO-DIV CAN, 125000 bit/s; CAN ID 0x64A. PSA-RE title: ON_CAN_DIAG_RESPONSE_7. Diagnostic response sent by the CDPL_CMF ECU. Source: https://github.com/prototux/PSA-RE/blob/67f7581e7622410efdbb29c7eda3b86982b9b450/buses/AEE2010.full/LS.INFO-DIV/64A.yml. Source sender alternatives: BSI; physical TX/gateway forwarding not verified. WIRE ISO-TP ONLY: normal addressing candidate, maximum Classical CAN DLC 8; actual DLC may be shorter. Data includes padding. No reassembly, text, DID or application-layer decoding. Original application layouts are preserved in source JSON; do not decode them at wire offsets. ";
CM_ SG_ 1610 FlowPadding5 "TRANSPORT_CANDIDATE: normal-addressing ISO-TP. PSA-RE bits 8.7-8.0. ";
CM_ SG_ 1610 FirstData6 "TRANSPORT_CANDIDATE: normal-addressing ISO-TP. PSA-RE bits 8.7-8.0. ";
CM_ SG_ 1610 UnknownData7 "TRANSPORT_CANDIDATE: normal-addressing ISO-TP. PSA-RE bits 8.7-8.0. ";
CM_ SG_ 1610 ConsecutiveData7 "TRANSPORT_CANDIDATE: normal-addressing ISO-TP. PSA-RE bits 8.7-8.0. ";
CM_ SG_ 1610 SingleData7 "TRANSPORT_CANDIDATE: normal-addressing ISO-TP. PSA-RE bits 8.7-8.0. ";
CM_ SG_ 1610 FlowPadding4 "TRANSPORT_CANDIDATE: normal-addressing ISO-TP. PSA-RE bits 7.7-7.0. ";
CM_ SG_ 1610 FirstData5 "TRANSPORT_CANDIDATE: normal-addressing ISO-TP. PSA-RE bits 7.7-7.0. ";
CM_ SG_ 1610 UnknownData6 "TRANSPORT_CANDIDATE: normal-addressing ISO-TP. PSA-RE bits 7.7-7.0. ";
CM_ SG_ 1610 ConsecutiveData6 "TRANSPORT_CANDIDATE: normal-addressing ISO-TP. PSA-RE bits 7.7-7.0. ";
CM_ SG_ 1610 SingleData6 "TRANSPORT_CANDIDATE: normal-addressing ISO-TP. PSA-RE bits 7.7-7.0. ";
CM_ SG_ 1610 FlowPadding3 "TRANSPORT_CANDIDATE: normal-addressing ISO-TP. PSA-RE bits 6.7-6.0. ";
CM_ SG_ 1610 FirstData4 "TRANSPORT_CANDIDATE: normal-addressing ISO-TP. PSA-RE bits 6.7-6.0. ";
CM_ SG_ 1610 UnknownData5 "TRANSPORT_CANDIDATE: normal-addressing ISO-TP. PSA-RE bits 6.7-6.0. ";
CM_ SG_ 1610 ConsecutiveData5 "TRANSPORT_CANDIDATE: normal-addressing ISO-TP. PSA-RE bits 6.7-6.0. ";
CM_ SG_ 1610 SingleData5 "TRANSPORT_CANDIDATE: normal-addressing ISO-TP. PSA-RE bits 6.7-6.0. ";
CM_ SG_ 1610 FlowPadding2 "TRANSPORT_CANDIDATE: normal-addressing ISO-TP. PSA-RE bits 5.7-5.0. ";
CM_ SG_ 1610 FirstData3 "TRANSPORT_CANDIDATE: normal-addressing ISO-TP. PSA-RE bits 5.7-5.0. ";
CM_ SG_ 1610 UnknownData4 "TRANSPORT_CANDIDATE: normal-addressing ISO-TP. PSA-RE bits 5.7-5.0. ";
CM_ SG_ 1610 ConsecutiveData4 "TRANSPORT_CANDIDATE: normal-addressing ISO-TP. PSA-RE bits 5.7-5.0. ";
CM_ SG_ 1610 SingleData4 "TRANSPORT_CANDIDATE: normal-addressing ISO-TP. PSA-RE bits 5.7-5.0. ";
CM_ SG_ 1610 FlowPadding1 "TRANSPORT_CANDIDATE: normal-addressing ISO-TP. PSA-RE bits 4.7-4.0. ";
CM_ SG_ 1610 FirstData2 "TRANSPORT_CANDIDATE: normal-addressing ISO-TP. PSA-RE bits 4.7-4.0. ";
CM_ SG_ 1610 UnknownData3 "TRANSPORT_CANDIDATE: normal-addressing ISO-TP. PSA-RE bits 4.7-4.0. ";
CM_ SG_ 1610 ConsecutiveData3 "TRANSPORT_CANDIDATE: normal-addressing ISO-TP. PSA-RE bits 4.7-4.0. ";
CM_ SG_ 1610 SingleData3 "TRANSPORT_CANDIDATE: normal-addressing ISO-TP. PSA-RE bits 4.7-4.0. ";
CM_ SG_ 1610 FirstData1 "TRANSPORT_CANDIDATE: normal-addressing ISO-TP. PSA-RE bits 3.7-3.0. ";
CM_ SG_ 1610 UnknownData2 "TRANSPORT_CANDIDATE: normal-addressing ISO-TP. PSA-RE bits 3.7-3.0. ";
CM_ SG_ 1610 ConsecutiveData2 "TRANSPORT_CANDIDATE: normal-addressing ISO-TP. PSA-RE bits 3.7-3.0. ";
CM_ SG_ 1610 SingleData2 "TRANSPORT_CANDIDATE: normal-addressing ISO-TP. PSA-RE bits 3.7-3.0. ";
CM_ SG_ 1610 SeparationTimeRaw "TRANSPORT_CANDIDATE: normal-addressing ISO-TP. PSA-RE bits 3.7-3.0. Raw STmin code; 0xF1..0xF9 are not milliseconds.";
CM_ SG_ 1610 UnknownData1 "TRANSPORT_CANDIDATE: normal-addressing ISO-TP. PSA-RE bits 2.7-2.0. ";
CM_ SG_ 1610 ConsecutiveData1 "TRANSPORT_CANDIDATE: normal-addressing ISO-TP. PSA-RE bits 2.7-2.0. ";
CM_ SG_ 1610 SingleData1 "TRANSPORT_CANDIDATE: normal-addressing ISO-TP. PSA-RE bits 2.7-2.0. ";
CM_ SG_ 1610 BlockSize "TRANSPORT_CANDIDATE: normal-addressing ISO-TP. PSA-RE bits 2.7-2.0. ";
CM_ SG_ 1610 UnknownPciLow "TRANSPORT_CANDIDATE: normal-addressing ISO-TP. PSA-RE bits 1.3-1.0. ";
CM_ SG_ 1610 FlowStatus "TRANSPORT_CANDIDATE: normal-addressing ISO-TP. PSA-RE bits 1.3-1.0. ";
CM_ SG_ 1610 ConsecutiveSequence "TRANSPORT_CANDIDATE: normal-addressing ISO-TP. PSA-RE bits 1.3-1.0. ";
CM_ SG_ 1610 FirstFrameLength "TRANSPORT_CANDIDATE: normal-addressing ISO-TP. PSA-RE bits 1.3-2.0. 12-bit declared PDU length; not a reassembled value.";
CM_ SG_ 1610 SingleFrameLength "TRANSPORT_CANDIDATE: normal-addressing ISO-TP. PSA-RE bits 1.3-1.0. Declared data length; not a validity check.";
CM_ SG_ 1610 IsoTpFrameType "TRANSPORT_CANDIDATE: normal-addressing ISO-TP. PSA-RE bits 1.7-1.4. PCI high nibble; normal addressing candidate.";
VAL_ 1330 AbsentMatt 0 "No control unit absent" 18 "BSI absent" ;
VAL_ 1330 SupervisionTaskState 0 "NM disabled" 1 "NM enabled" ;
VAL_ 1330 NerrBitStatus 0 "No fault detected" 1 "Fault present" ;
VAL_ 1330 ComLossFault 0 "No fault detected" 1 "Fault present" ;
VAL_ 1331 AbsentAvp 0 "No control unit absent" 18 "BSI absent" ;
VAL_ 1331 SupervisionTaskState 0 "NM disabled" 1 "NM enabled" ;
VAL_ 1331 NerrBitStatus 0 "No fault detected" 1 "Fault present" ;
VAL_ 1331 ComLossFault 0 "No fault detected" 1 "Fault present" ;
VAL_ 1334 AbsentBtt 0 "No control unit absent" 18 "BSI absent" ;
VAL_ 1334 DiagnosticSessionActive 0 "Excluding diagnostic activity" 1 "Diagnostic activity in progress" ;
VAL_ 1334 UnderDiagnosisSession 0 "Outside diagnostic mode" 1 "Under diagnostic" ;
VAL_ 1334 SupervisionTaskState 0 "NM disabled" 1 "NM enabled" ;
VAL_ 1334 NerrBitStatus 0 "No fault detected" 1 "Fault present" ;
VAL_ 1334 ComLossFault 0 "No fault detected" 1 "Fault present" ;
VAL_ 1339 AbsentFmux1 0 "No control unit absent" 18 "BSI absent" ;
VAL_ 1339 SupervisionTaskState 0 "NM disabled" 1 "NM enabled" ;
VAL_ 1339 NerrBitStatus 0 "No fault detected" 1 "Fault present" ;
VAL_ 1339 ComLossFault 0 "No fault detected" 1 "Fault present" ;
VAL_ 1340 AbsentMds 0 "No control unit absent" 18 "BSI absent" ;
VAL_ 1340 DiagnosticSessionActive 0 "Excluding diagnostic activity" 1 "Diagnostic activity in progress" ;
VAL_ 1340 SupervisionTaskState 0 "NM disabled" 1 "NM enabled" ;
VAL_ 1340 NerrBitStatus 0 "No fault detected" 1 "Fault present" ;
VAL_ 1340 ComLossFault 0 "No fault detected" 1 "Fault present" ;
VAL_ 1341 AbsentAmpli 0 "No control unit absent" 18 "Body computer absent" ;
VAL_ 1341 DiagnosticSessionActive 0 "Excluding diagnostic activity" 1 "Diagnostic activity in progress" ;
VAL_ 1341 UnderDiagnosisSession 0 "Outside diagnostic mode" 1 "Under diagnostic" ;
VAL_ 1341 SupervisionTaskState 0 "NM disabled" 1 "NM enabled" ;
VAL_ 1341 NerrBitStatus 0 "No fault detected" 1 "Fault present" ;
VAL_ 1341 ComLossFault 0 "No fault detected" 1 "Fault present" ;
VAL_ 1473 EditionNumber 255 "Not_available" ;
VAL_ 1473 GenerationNumberDigit2 15 "Forced value" ;
VAL_ 1473 SoftwareIdentification 65535 "Not_available" ;
VAL_ 1473 EcuNumber 255 "Not_available" ;
VAL_ 1484 EditionNumber 255 "Not_available" ;
VAL_ 1484 GenerationNumberDigit2 15 "Forced value" ;
VAL_ 1484 SoftwareIdentification 65535 "Not_available" ;
VAL_ 1484 EcuNumber 255 "Not_available" ;
VAL_ 1490 EditionNumber 255 "Not_available" ;
VAL_ 1490 GenerationNumberDigit2 15 "Forced value" ;
VAL_ 1490 SoftwareIdentification 65535 "Not_available" ;
VAL_ 1490 EcuNumber 255 "Not_available" ;
VAL_ 1501 EditionNumber 255 "Not_available" ;
VAL_ 1501 GenerationNumberDigit2 15 "Forced value" ;
VAL_ 1501 SoftwareIdentification 65535 "Not_available" ;
VAL_ 1501 EcuNumber 255 "Not_available" ;
VAL_ 1503 EditionNumber 255 "Not_available" ;
VAL_ 1503 GenerationNumberDigit2 15 "Forced value" ;
VAL_ 1503 SoftwareIdentification 65535 "Not_available" ;
VAL_ 1503 EcuNumber 255 "Not_available" ;
VAL_ 1504 EditionNumber 255 "Not_available" ;
VAL_ 1504 GenerationNumberDigit2 15 "Forced value" ;
VAL_ 1504 SoftwareIdentification 65535 "Not_available" ;
VAL_ 1504 EcuNumber 255 "Not_available" ;
VAL_ 1507 EditionNumber 255 "Not_available" ;
VAL_ 1507 GenerationNumberDigit2 15 "Forced value" ;
VAL_ 1507 SoftwareIdentification 65535 "Not_available" ;
VAL_ 1507 EcuNumber 255 "Not_available" ;
VAL_ 1508 EditionNumber 255 "Not_available" ;
VAL_ 1508 GenerationNumberDigit2 15 "Forced value" ;
VAL_ 1508 SoftwareIdentification 65535 "Not_available" ;
VAL_ 1508 EcuNumber 255 "Not_available" ;
VAL_ 1509 EditionNumber 255 "Not_available" ;
VAL_ 1509 GenerationNumberDigit2 15 "Forced value" ;
VAL_ 1509 SoftwareIdentification 65535 "Not_available" ;
VAL_ 1509 EcuNumber 255 "Not_available" ;
VAL_ 1510 EditionNumber 255 "Not_available" ;
VAL_ 1510 GenerationNumberDigit2 15 "Forced value" ;
VAL_ 1510 SoftwareIdentification 65535 "Not_available" ;
VAL_ 1510 EcuNumber 255 "Not_available" ;
VAL_ 1520 EditionNumber 255 "Not_available" ;
VAL_ 1520 GenerationNumberDigit2 15 "Forced value" ;
VAL_ 1520 SoftwareIdentification 65535 "Not_available" ;
VAL_ 1520 EcuNumber 255 "Not_available" ;
VAL_ 1521 EditionNumber 255 "Not_available" ;
VAL_ 1521 GenerationNumberDigit2 15 "Forced value" ;
VAL_ 1521 SoftwareIdentification 65535 "Not_available" ;
VAL_ 1521 EcuNumber 255 "Not_available" ;
VAL_ 1522 EditionNumber 255 "Not_available" ;
VAL_ 1522 GenerationNumberDigit2 15 "Forced value" ;
VAL_ 1522 SoftwareIdentification 65535 "Not_available" ;
VAL_ 1522 EcuNumber 255 "Not_available" ;
VAL_ 1523 EditionNumber 255 "Not_available" ;
VAL_ 1523 GenerationNumberDigit2 15 "Forced value" ;
VAL_ 1523 SoftwareIdentification 65535 "Not_available" ;
VAL_ 1523 EcuNumber 255 "Not_available" ;
VAL_ 1526 EditionNumber 255 "Not_available" ;
VAL_ 1526 GenerationNumberDigit2 15 "Forced value" ;
VAL_ 1526 SoftwareIdentification 65535 "Not_available" ;
VAL_ 1526 EcuNumber 255 "Not_available" ;
VAL_ 1531 EditionNumber 255 "Not_available" ;
VAL_ 1531 GenerationNumberDigit2 15 "Forced value" ;
VAL_ 1531 SoftwareIdentification 65535 "Not_available" ;
VAL_ 1531 EcuNumber 255 "Not_available" ;
VAL_ 1532 EditionNumber 255 "Not_available" ;
VAL_ 1532 GenerationNumberDigit2 15 "Forced value" ;
VAL_ 1532 SoftwareIdentification 65535 "Not_available" ;
VAL_ 1532 EcuNumber 255 "Not_available" ;
VAL_ 1533 EditionNumber 255 "Not_available" ;
VAL_ 1533 GenerationNumberDigit2 15 "Forced value" ;
VAL_ 1533 SoftwareIdentification 65535 "Not_available" ;
VAL_ 1533 EcuNumber 255 "Not_available" ;
VAL_ 1576 FlowStatus 0 "ContinueToSend" 1 "Wait" 2 "Overflow" ;
VAL_ 1576 IsoTpFrameType 0 "SingleFrame" 1 "FirstFrame" 2 "ConsecutiveFrame" 3 "FlowControl" ;
VAL_ 1601 FlowStatus 0 "ContinueToSend" 1 "Wait" 2 "Overflow" ;
VAL_ 1601 IsoTpFrameType 0 "SingleFrame" 1 "FirstFrame" 2 "ConsecutiveFrame" 3 "FlowControl" ;
VAL_ 1602 FlowStatus 0 "ContinueToSend" 1 "Wait" 2 "Overflow" ;
VAL_ 1602 IsoTpFrameType 0 "SingleFrame" 1 "FirstFrame" 2 "ConsecutiveFrame" 3 "FlowControl" ;
VAL_ 1603 FlowStatus 0 "ContinueToSend" 1 "Wait" 2 "Overflow" ;
VAL_ 1603 IsoTpFrameType 0 "SingleFrame" 1 "FirstFrame" 2 "ConsecutiveFrame" 3 "FlowControl" ;
VAL_ 1604 FlowStatus 0 "ContinueToSend" 1 "Wait" 2 "Overflow" ;
VAL_ 1604 IsoTpFrameType 0 "SingleFrame" 1 "FirstFrame" 2 "ConsecutiveFrame" 3 "FlowControl" ;
VAL_ 1605 FlowStatus 0 "ContinueToSend" 1 "Wait" 2 "Overflow" ;
VAL_ 1605 IsoTpFrameType 0 "SingleFrame" 1 "FirstFrame" 2 "ConsecutiveFrame" 3 "FlowControl" ;
VAL_ 1606 FlowStatus 0 "ContinueToSend" 1 "Wait" 2 "Overflow" ;
VAL_ 1606 IsoTpFrameType 0 "SingleFrame" 1 "FirstFrame" 2 "ConsecutiveFrame" 3 "FlowControl" ;
VAL_ 1607 FlowStatus 0 "ContinueToSend" 1 "Wait" 2 "Overflow" ;
VAL_ 1607 IsoTpFrameType 0 "SingleFrame" 1 "FirstFrame" 2 "ConsecutiveFrame" 3 "FlowControl" ;
VAL_ 1608 FlowStatus 0 "ContinueToSend" 1 "Wait" 2 "Overflow" ;
VAL_ 1608 IsoTpFrameType 0 "SingleFrame" 1 "FirstFrame" 2 "ConsecutiveFrame" 3 "FlowControl" ;
VAL_ 1609 FlowStatus 0 "ContinueToSend" 1 "Wait" 2 "Overflow" ;
VAL_ 1609 IsoTpFrameType 0 "SingleFrame" 1 "FirstFrame" 2 "ConsecutiveFrame" 3 "FlowControl" ;
VAL_ 1610 FlowStatus 0 "ContinueToSend" 1 "Wait" 2 "Overflow" ;
VAL_ 1610 IsoTpFrameType 0 "SingleFrame" 1 "FirstFrame" 2 "ConsecutiveFrame" 3 "FlowControl" ;
SG_MUL_VAL_ 1576 SingleFrameLength IsoTpFrameType 0-0;
SG_MUL_VAL_ 1576 FirstFrameLength IsoTpFrameType 1-1;
SG_MUL_VAL_ 1576 ConsecutiveSequence IsoTpFrameType 2-2;
SG_MUL_VAL_ 1576 FlowStatus IsoTpFrameType 3-3;
SG_MUL_VAL_ 1576 UnknownPciLow IsoTpFrameType 4-15;
SG_MUL_VAL_ 1576 BlockSize IsoTpFrameType 3-3;
SG_MUL_VAL_ 1576 SingleData1 IsoTpFrameType 0-0;
SG_MUL_VAL_ 1576 ConsecutiveData1 IsoTpFrameType 2-2;
SG_MUL_VAL_ 1576 UnknownData1 IsoTpFrameType 4-15;
SG_MUL_VAL_ 1576 SeparationTimeRaw IsoTpFrameType 3-3;
SG_MUL_VAL_ 1576 SingleData2 IsoTpFrameType 0-0;
SG_MUL_VAL_ 1576 ConsecutiveData2 IsoTpFrameType 2-2;
SG_MUL_VAL_ 1576 UnknownData2 IsoTpFrameType 4-15;
SG_MUL_VAL_ 1576 FirstData1 IsoTpFrameType 1-1;
SG_MUL_VAL_ 1576 SingleData3 IsoTpFrameType 0-0;
SG_MUL_VAL_ 1576 ConsecutiveData3 IsoTpFrameType 2-2;
SG_MUL_VAL_ 1576 UnknownData3 IsoTpFrameType 4-15;
SG_MUL_VAL_ 1576 FirstData2 IsoTpFrameType 1-1;
SG_MUL_VAL_ 1576 FlowPadding1 IsoTpFrameType 3-3;
SG_MUL_VAL_ 1576 SingleData4 IsoTpFrameType 0-0;
SG_MUL_VAL_ 1576 ConsecutiveData4 IsoTpFrameType 2-2;
SG_MUL_VAL_ 1576 UnknownData4 IsoTpFrameType 4-15;
SG_MUL_VAL_ 1576 FirstData3 IsoTpFrameType 1-1;
SG_MUL_VAL_ 1576 FlowPadding2 IsoTpFrameType 3-3;
SG_MUL_VAL_ 1576 SingleData5 IsoTpFrameType 0-0;
SG_MUL_VAL_ 1576 ConsecutiveData5 IsoTpFrameType 2-2;
SG_MUL_VAL_ 1576 UnknownData5 IsoTpFrameType 4-15;
SG_MUL_VAL_ 1576 FirstData4 IsoTpFrameType 1-1;
SG_MUL_VAL_ 1576 FlowPadding3 IsoTpFrameType 3-3;
SG_MUL_VAL_ 1576 SingleData6 IsoTpFrameType 0-0;
SG_MUL_VAL_ 1576 ConsecutiveData6 IsoTpFrameType 2-2;
SG_MUL_VAL_ 1576 UnknownData6 IsoTpFrameType 4-15;
SG_MUL_VAL_ 1576 FirstData5 IsoTpFrameType 1-1;
SG_MUL_VAL_ 1576 FlowPadding4 IsoTpFrameType 3-3;
SG_MUL_VAL_ 1576 SingleData7 IsoTpFrameType 0-0;
SG_MUL_VAL_ 1576 ConsecutiveData7 IsoTpFrameType 2-2;
SG_MUL_VAL_ 1576 UnknownData7 IsoTpFrameType 4-15;
SG_MUL_VAL_ 1576 FirstData6 IsoTpFrameType 1-1;
SG_MUL_VAL_ 1576 FlowPadding5 IsoTpFrameType 3-3;
SG_MUL_VAL_ 1601 SingleFrameLength IsoTpFrameType 0-0;
SG_MUL_VAL_ 1601 FirstFrameLength IsoTpFrameType 1-1;
SG_MUL_VAL_ 1601 ConsecutiveSequence IsoTpFrameType 2-2;
SG_MUL_VAL_ 1601 FlowStatus IsoTpFrameType 3-3;
SG_MUL_VAL_ 1601 UnknownPciLow IsoTpFrameType 4-15;
SG_MUL_VAL_ 1601 BlockSize IsoTpFrameType 3-3;
SG_MUL_VAL_ 1601 SingleData1 IsoTpFrameType 0-0;
SG_MUL_VAL_ 1601 ConsecutiveData1 IsoTpFrameType 2-2;
SG_MUL_VAL_ 1601 UnknownData1 IsoTpFrameType 4-15;
SG_MUL_VAL_ 1601 SeparationTimeRaw IsoTpFrameType 3-3;
SG_MUL_VAL_ 1601 SingleData2 IsoTpFrameType 0-0;
SG_MUL_VAL_ 1601 ConsecutiveData2 IsoTpFrameType 2-2;
SG_MUL_VAL_ 1601 UnknownData2 IsoTpFrameType 4-15;
SG_MUL_VAL_ 1601 FirstData1 IsoTpFrameType 1-1;
SG_MUL_VAL_ 1601 SingleData3 IsoTpFrameType 0-0;
SG_MUL_VAL_ 1601 ConsecutiveData3 IsoTpFrameType 2-2;
SG_MUL_VAL_ 1601 UnknownData3 IsoTpFrameType 4-15;
SG_MUL_VAL_ 1601 FirstData2 IsoTpFrameType 1-1;
SG_MUL_VAL_ 1601 FlowPadding1 IsoTpFrameType 3-3;
SG_MUL_VAL_ 1601 SingleData4 IsoTpFrameType 0-0;
SG_MUL_VAL_ 1601 ConsecutiveData4 IsoTpFrameType 2-2;
SG_MUL_VAL_ 1601 UnknownData4 IsoTpFrameType 4-15;
SG_MUL_VAL_ 1601 FirstData3 IsoTpFrameType 1-1;
SG_MUL_VAL_ 1601 FlowPadding2 IsoTpFrameType 3-3;
SG_MUL_VAL_ 1601 SingleData5 IsoTpFrameType 0-0;
SG_MUL_VAL_ 1601 ConsecutiveData5 IsoTpFrameType 2-2;
SG_MUL_VAL_ 1601 UnknownData5 IsoTpFrameType 4-15;
SG_MUL_VAL_ 1601 FirstData4 IsoTpFrameType 1-1;
SG_MUL_VAL_ 1601 FlowPadding3 IsoTpFrameType 3-3;
SG_MUL_VAL_ 1601 SingleData6 IsoTpFrameType 0-0;
SG_MUL_VAL_ 1601 ConsecutiveData6 IsoTpFrameType 2-2;
SG_MUL_VAL_ 1601 UnknownData6 IsoTpFrameType 4-15;
SG_MUL_VAL_ 1601 FirstData5 IsoTpFrameType 1-1;
SG_MUL_VAL_ 1601 FlowPadding4 IsoTpFrameType 3-3;
SG_MUL_VAL_ 1601 SingleData7 IsoTpFrameType 0-0;
SG_MUL_VAL_ 1601 ConsecutiveData7 IsoTpFrameType 2-2;
SG_MUL_VAL_ 1601 UnknownData7 IsoTpFrameType 4-15;
SG_MUL_VAL_ 1601 FirstData6 IsoTpFrameType 1-1;
SG_MUL_VAL_ 1601 FlowPadding5 IsoTpFrameType 3-3;
SG_MUL_VAL_ 1602 SingleFrameLength IsoTpFrameType 0-0;
SG_MUL_VAL_ 1602 FirstFrameLength IsoTpFrameType 1-1;
SG_MUL_VAL_ 1602 ConsecutiveSequence IsoTpFrameType 2-2;
SG_MUL_VAL_ 1602 FlowStatus IsoTpFrameType 3-3;
SG_MUL_VAL_ 1602 UnknownPciLow IsoTpFrameType 4-15;
SG_MUL_VAL_ 1602 BlockSize IsoTpFrameType 3-3;
SG_MUL_VAL_ 1602 SingleData1 IsoTpFrameType 0-0;
SG_MUL_VAL_ 1602 ConsecutiveData1 IsoTpFrameType 2-2;
SG_MUL_VAL_ 1602 UnknownData1 IsoTpFrameType 4-15;
SG_MUL_VAL_ 1602 SeparationTimeRaw IsoTpFrameType 3-3;
SG_MUL_VAL_ 1602 SingleData2 IsoTpFrameType 0-0;
SG_MUL_VAL_ 1602 ConsecutiveData2 IsoTpFrameType 2-2;
SG_MUL_VAL_ 1602 UnknownData2 IsoTpFrameType 4-15;
SG_MUL_VAL_ 1602 FirstData1 IsoTpFrameType 1-1;
SG_MUL_VAL_ 1602 SingleData3 IsoTpFrameType 0-0;
SG_MUL_VAL_ 1602 ConsecutiveData3 IsoTpFrameType 2-2;
SG_MUL_VAL_ 1602 UnknownData3 IsoTpFrameType 4-15;
SG_MUL_VAL_ 1602 FirstData2 IsoTpFrameType 1-1;
SG_MUL_VAL_ 1602 FlowPadding1 IsoTpFrameType 3-3;
SG_MUL_VAL_ 1602 SingleData4 IsoTpFrameType 0-0;
SG_MUL_VAL_ 1602 ConsecutiveData4 IsoTpFrameType 2-2;
SG_MUL_VAL_ 1602 UnknownData4 IsoTpFrameType 4-15;
SG_MUL_VAL_ 1602 FirstData3 IsoTpFrameType 1-1;
SG_MUL_VAL_ 1602 FlowPadding2 IsoTpFrameType 3-3;
SG_MUL_VAL_ 1602 SingleData5 IsoTpFrameType 0-0;
SG_MUL_VAL_ 1602 ConsecutiveData5 IsoTpFrameType 2-2;
SG_MUL_VAL_ 1602 UnknownData5 IsoTpFrameType 4-15;
SG_MUL_VAL_ 1602 FirstData4 IsoTpFrameType 1-1;
SG_MUL_VAL_ 1602 FlowPadding3 IsoTpFrameType 3-3;
SG_MUL_VAL_ 1602 SingleData6 IsoTpFrameType 0-0;
SG_MUL_VAL_ 1602 ConsecutiveData6 IsoTpFrameType 2-2;
SG_MUL_VAL_ 1602 UnknownData6 IsoTpFrameType 4-15;
SG_MUL_VAL_ 1602 FirstData5 IsoTpFrameType 1-1;
SG_MUL_VAL_ 1602 FlowPadding4 IsoTpFrameType 3-3;
SG_MUL_VAL_ 1602 SingleData7 IsoTpFrameType 0-0;
SG_MUL_VAL_ 1602 ConsecutiveData7 IsoTpFrameType 2-2;
SG_MUL_VAL_ 1602 UnknownData7 IsoTpFrameType 4-15;
SG_MUL_VAL_ 1602 FirstData6 IsoTpFrameType 1-1;
SG_MUL_VAL_ 1602 FlowPadding5 IsoTpFrameType 3-3;
SG_MUL_VAL_ 1603 SingleFrameLength IsoTpFrameType 0-0;
SG_MUL_VAL_ 1603 FirstFrameLength IsoTpFrameType 1-1;
SG_MUL_VAL_ 1603 ConsecutiveSequence IsoTpFrameType 2-2;
SG_MUL_VAL_ 1603 FlowStatus IsoTpFrameType 3-3;
SG_MUL_VAL_ 1603 UnknownPciLow IsoTpFrameType 4-15;
SG_MUL_VAL_ 1603 BlockSize IsoTpFrameType 3-3;
SG_MUL_VAL_ 1603 SingleData1 IsoTpFrameType 0-0;
SG_MUL_VAL_ 1603 ConsecutiveData1 IsoTpFrameType 2-2;
SG_MUL_VAL_ 1603 UnknownData1 IsoTpFrameType 4-15;
SG_MUL_VAL_ 1603 SeparationTimeRaw IsoTpFrameType 3-3;
SG_MUL_VAL_ 1603 SingleData2 IsoTpFrameType 0-0;
SG_MUL_VAL_ 1603 ConsecutiveData2 IsoTpFrameType 2-2;
SG_MUL_VAL_ 1603 UnknownData2 IsoTpFrameType 4-15;
SG_MUL_VAL_ 1603 FirstData1 IsoTpFrameType 1-1;
SG_MUL_VAL_ 1603 SingleData3 IsoTpFrameType 0-0;
SG_MUL_VAL_ 1603 ConsecutiveData3 IsoTpFrameType 2-2;
SG_MUL_VAL_ 1603 UnknownData3 IsoTpFrameType 4-15;
SG_MUL_VAL_ 1603 FirstData2 IsoTpFrameType 1-1;
SG_MUL_VAL_ 1603 FlowPadding1 IsoTpFrameType 3-3;
SG_MUL_VAL_ 1603 SingleData4 IsoTpFrameType 0-0;
SG_MUL_VAL_ 1603 ConsecutiveData4 IsoTpFrameType 2-2;
SG_MUL_VAL_ 1603 UnknownData4 IsoTpFrameType 4-15;
SG_MUL_VAL_ 1603 FirstData3 IsoTpFrameType 1-1;
SG_MUL_VAL_ 1603 FlowPadding2 IsoTpFrameType 3-3;
SG_MUL_VAL_ 1603 SingleData5 IsoTpFrameType 0-0;
SG_MUL_VAL_ 1603 ConsecutiveData5 IsoTpFrameType 2-2;
SG_MUL_VAL_ 1603 UnknownData5 IsoTpFrameType 4-15;
SG_MUL_VAL_ 1603 FirstData4 IsoTpFrameType 1-1;
SG_MUL_VAL_ 1603 FlowPadding3 IsoTpFrameType 3-3;
SG_MUL_VAL_ 1603 SingleData6 IsoTpFrameType 0-0;
SG_MUL_VAL_ 1603 ConsecutiveData6 IsoTpFrameType 2-2;
SG_MUL_VAL_ 1603 UnknownData6 IsoTpFrameType 4-15;
SG_MUL_VAL_ 1603 FirstData5 IsoTpFrameType 1-1;
SG_MUL_VAL_ 1603 FlowPadding4 IsoTpFrameType 3-3;
SG_MUL_VAL_ 1603 SingleData7 IsoTpFrameType 0-0;
SG_MUL_VAL_ 1603 ConsecutiveData7 IsoTpFrameType 2-2;
SG_MUL_VAL_ 1603 UnknownData7 IsoTpFrameType 4-15;
SG_MUL_VAL_ 1603 FirstData6 IsoTpFrameType 1-1;
SG_MUL_VAL_ 1603 FlowPadding5 IsoTpFrameType 3-3;
SG_MUL_VAL_ 1604 SingleFrameLength IsoTpFrameType 0-0;
SG_MUL_VAL_ 1604 FirstFrameLength IsoTpFrameType 1-1;
SG_MUL_VAL_ 1604 ConsecutiveSequence IsoTpFrameType 2-2;
SG_MUL_VAL_ 1604 FlowStatus IsoTpFrameType 3-3;
SG_MUL_VAL_ 1604 UnknownPciLow IsoTpFrameType 4-15;
SG_MUL_VAL_ 1604 BlockSize IsoTpFrameType 3-3;
SG_MUL_VAL_ 1604 SingleData1 IsoTpFrameType 0-0;
SG_MUL_VAL_ 1604 ConsecutiveData1 IsoTpFrameType 2-2;
SG_MUL_VAL_ 1604 UnknownData1 IsoTpFrameType 4-15;
SG_MUL_VAL_ 1604 SeparationTimeRaw IsoTpFrameType 3-3;
SG_MUL_VAL_ 1604 SingleData2 IsoTpFrameType 0-0;
SG_MUL_VAL_ 1604 ConsecutiveData2 IsoTpFrameType 2-2;
SG_MUL_VAL_ 1604 UnknownData2 IsoTpFrameType 4-15;
SG_MUL_VAL_ 1604 FirstData1 IsoTpFrameType 1-1;
SG_MUL_VAL_ 1604 SingleData3 IsoTpFrameType 0-0;
SG_MUL_VAL_ 1604 ConsecutiveData3 IsoTpFrameType 2-2;
SG_MUL_VAL_ 1604 UnknownData3 IsoTpFrameType 4-15;
SG_MUL_VAL_ 1604 FirstData2 IsoTpFrameType 1-1;
SG_MUL_VAL_ 1604 FlowPadding1 IsoTpFrameType 3-3;
SG_MUL_VAL_ 1604 SingleData4 IsoTpFrameType 0-0;
SG_MUL_VAL_ 1604 ConsecutiveData4 IsoTpFrameType 2-2;
SG_MUL_VAL_ 1604 UnknownData4 IsoTpFrameType 4-15;
SG_MUL_VAL_ 1604 FirstData3 IsoTpFrameType 1-1;
SG_MUL_VAL_ 1604 FlowPadding2 IsoTpFrameType 3-3;
SG_MUL_VAL_ 1604 SingleData5 IsoTpFrameType 0-0;
SG_MUL_VAL_ 1604 ConsecutiveData5 IsoTpFrameType 2-2;
SG_MUL_VAL_ 1604 UnknownData5 IsoTpFrameType 4-15;
SG_MUL_VAL_ 1604 FirstData4 IsoTpFrameType 1-1;
SG_MUL_VAL_ 1604 FlowPadding3 IsoTpFrameType 3-3;
SG_MUL_VAL_ 1604 SingleData6 IsoTpFrameType 0-0;
SG_MUL_VAL_ 1604 ConsecutiveData6 IsoTpFrameType 2-2;
SG_MUL_VAL_ 1604 UnknownData6 IsoTpFrameType 4-15;
SG_MUL_VAL_ 1604 FirstData5 IsoTpFrameType 1-1;
SG_MUL_VAL_ 1604 FlowPadding4 IsoTpFrameType 3-3;
SG_MUL_VAL_ 1604 SingleData7 IsoTpFrameType 0-0;
SG_MUL_VAL_ 1604 ConsecutiveData7 IsoTpFrameType 2-2;
SG_MUL_VAL_ 1604 UnknownData7 IsoTpFrameType 4-15;
SG_MUL_VAL_ 1604 FirstData6 IsoTpFrameType 1-1;
SG_MUL_VAL_ 1604 FlowPadding5 IsoTpFrameType 3-3;
SG_MUL_VAL_ 1605 SingleFrameLength IsoTpFrameType 0-0;
SG_MUL_VAL_ 1605 FirstFrameLength IsoTpFrameType 1-1;
SG_MUL_VAL_ 1605 ConsecutiveSequence IsoTpFrameType 2-2;
SG_MUL_VAL_ 1605 FlowStatus IsoTpFrameType 3-3;
SG_MUL_VAL_ 1605 UnknownPciLow IsoTpFrameType 4-15;
SG_MUL_VAL_ 1605 BlockSize IsoTpFrameType 3-3;
SG_MUL_VAL_ 1605 SingleData1 IsoTpFrameType 0-0;
SG_MUL_VAL_ 1605 ConsecutiveData1 IsoTpFrameType 2-2;
SG_MUL_VAL_ 1605 UnknownData1 IsoTpFrameType 4-15;
SG_MUL_VAL_ 1605 SeparationTimeRaw IsoTpFrameType 3-3;
SG_MUL_VAL_ 1605 SingleData2 IsoTpFrameType 0-0;
SG_MUL_VAL_ 1605 ConsecutiveData2 IsoTpFrameType 2-2;
SG_MUL_VAL_ 1605 UnknownData2 IsoTpFrameType 4-15;
SG_MUL_VAL_ 1605 FirstData1 IsoTpFrameType 1-1;
SG_MUL_VAL_ 1605 SingleData3 IsoTpFrameType 0-0;
SG_MUL_VAL_ 1605 ConsecutiveData3 IsoTpFrameType 2-2;
SG_MUL_VAL_ 1605 UnknownData3 IsoTpFrameType 4-15;
SG_MUL_VAL_ 1605 FirstData2 IsoTpFrameType 1-1;
SG_MUL_VAL_ 1605 FlowPadding1 IsoTpFrameType 3-3;
SG_MUL_VAL_ 1605 SingleData4 IsoTpFrameType 0-0;
SG_MUL_VAL_ 1605 ConsecutiveData4 IsoTpFrameType 2-2;
SG_MUL_VAL_ 1605 UnknownData4 IsoTpFrameType 4-15;
SG_MUL_VAL_ 1605 FirstData3 IsoTpFrameType 1-1;
SG_MUL_VAL_ 1605 FlowPadding2 IsoTpFrameType 3-3;
SG_MUL_VAL_ 1605 SingleData5 IsoTpFrameType 0-0;
SG_MUL_VAL_ 1605 ConsecutiveData5 IsoTpFrameType 2-2;
SG_MUL_VAL_ 1605 UnknownData5 IsoTpFrameType 4-15;
SG_MUL_VAL_ 1605 FirstData4 IsoTpFrameType 1-1;
SG_MUL_VAL_ 1605 FlowPadding3 IsoTpFrameType 3-3;
SG_MUL_VAL_ 1605 SingleData6 IsoTpFrameType 0-0;
SG_MUL_VAL_ 1605 ConsecutiveData6 IsoTpFrameType 2-2;
SG_MUL_VAL_ 1605 UnknownData6 IsoTpFrameType 4-15;
SG_MUL_VAL_ 1605 FirstData5 IsoTpFrameType 1-1;
SG_MUL_VAL_ 1605 FlowPadding4 IsoTpFrameType 3-3;
SG_MUL_VAL_ 1605 SingleData7 IsoTpFrameType 0-0;
SG_MUL_VAL_ 1605 ConsecutiveData7 IsoTpFrameType 2-2;
SG_MUL_VAL_ 1605 UnknownData7 IsoTpFrameType 4-15;
SG_MUL_VAL_ 1605 FirstData6 IsoTpFrameType 1-1;
SG_MUL_VAL_ 1605 FlowPadding5 IsoTpFrameType 3-3;
SG_MUL_VAL_ 1606 SingleFrameLength IsoTpFrameType 0-0;
SG_MUL_VAL_ 1606 FirstFrameLength IsoTpFrameType 1-1;
SG_MUL_VAL_ 1606 ConsecutiveSequence IsoTpFrameType 2-2;
SG_MUL_VAL_ 1606 FlowStatus IsoTpFrameType 3-3;
SG_MUL_VAL_ 1606 UnknownPciLow IsoTpFrameType 4-15;
SG_MUL_VAL_ 1606 BlockSize IsoTpFrameType 3-3;
SG_MUL_VAL_ 1606 SingleData1 IsoTpFrameType 0-0;
SG_MUL_VAL_ 1606 ConsecutiveData1 IsoTpFrameType 2-2;
SG_MUL_VAL_ 1606 UnknownData1 IsoTpFrameType 4-15;
SG_MUL_VAL_ 1606 SeparationTimeRaw IsoTpFrameType 3-3;
SG_MUL_VAL_ 1606 SingleData2 IsoTpFrameType 0-0;
SG_MUL_VAL_ 1606 ConsecutiveData2 IsoTpFrameType 2-2;
SG_MUL_VAL_ 1606 UnknownData2 IsoTpFrameType 4-15;
SG_MUL_VAL_ 1606 FirstData1 IsoTpFrameType 1-1;
SG_MUL_VAL_ 1606 SingleData3 IsoTpFrameType 0-0;
SG_MUL_VAL_ 1606 ConsecutiveData3 IsoTpFrameType 2-2;
SG_MUL_VAL_ 1606 UnknownData3 IsoTpFrameType 4-15;
SG_MUL_VAL_ 1606 FirstData2 IsoTpFrameType 1-1;
SG_MUL_VAL_ 1606 FlowPadding1 IsoTpFrameType 3-3;
SG_MUL_VAL_ 1606 SingleData4 IsoTpFrameType 0-0;
SG_MUL_VAL_ 1606 ConsecutiveData4 IsoTpFrameType 2-2;
SG_MUL_VAL_ 1606 UnknownData4 IsoTpFrameType 4-15;
SG_MUL_VAL_ 1606 FirstData3 IsoTpFrameType 1-1;
SG_MUL_VAL_ 1606 FlowPadding2 IsoTpFrameType 3-3;
SG_MUL_VAL_ 1606 SingleData5 IsoTpFrameType 0-0;
SG_MUL_VAL_ 1606 ConsecutiveData5 IsoTpFrameType 2-2;
SG_MUL_VAL_ 1606 UnknownData5 IsoTpFrameType 4-15;
SG_MUL_VAL_ 1606 FirstData4 IsoTpFrameType 1-1;
SG_MUL_VAL_ 1606 FlowPadding3 IsoTpFrameType 3-3;
SG_MUL_VAL_ 1606 SingleData6 IsoTpFrameType 0-0;
SG_MUL_VAL_ 1606 ConsecutiveData6 IsoTpFrameType 2-2;
SG_MUL_VAL_ 1606 UnknownData6 IsoTpFrameType 4-15;
SG_MUL_VAL_ 1606 FirstData5 IsoTpFrameType 1-1;
SG_MUL_VAL_ 1606 FlowPadding4 IsoTpFrameType 3-3;
SG_MUL_VAL_ 1606 SingleData7 IsoTpFrameType 0-0;
SG_MUL_VAL_ 1606 ConsecutiveData7 IsoTpFrameType 2-2;
SG_MUL_VAL_ 1606 UnknownData7 IsoTpFrameType 4-15;
SG_MUL_VAL_ 1606 FirstData6 IsoTpFrameType 1-1;
SG_MUL_VAL_ 1606 FlowPadding5 IsoTpFrameType 3-3;
SG_MUL_VAL_ 1607 SingleFrameLength IsoTpFrameType 0-0;
SG_MUL_VAL_ 1607 FirstFrameLength IsoTpFrameType 1-1;
SG_MUL_VAL_ 1607 ConsecutiveSequence IsoTpFrameType 2-2;
SG_MUL_VAL_ 1607 FlowStatus IsoTpFrameType 3-3;
SG_MUL_VAL_ 1607 UnknownPciLow IsoTpFrameType 4-15;
SG_MUL_VAL_ 1607 BlockSize IsoTpFrameType 3-3;
SG_MUL_VAL_ 1607 SingleData1 IsoTpFrameType 0-0;
SG_MUL_VAL_ 1607 ConsecutiveData1 IsoTpFrameType 2-2;
SG_MUL_VAL_ 1607 UnknownData1 IsoTpFrameType 4-15;
SG_MUL_VAL_ 1607 SeparationTimeRaw IsoTpFrameType 3-3;
SG_MUL_VAL_ 1607 SingleData2 IsoTpFrameType 0-0;
SG_MUL_VAL_ 1607 ConsecutiveData2 IsoTpFrameType 2-2;
SG_MUL_VAL_ 1607 UnknownData2 IsoTpFrameType 4-15;
SG_MUL_VAL_ 1607 FirstData1 IsoTpFrameType 1-1;
SG_MUL_VAL_ 1607 SingleData3 IsoTpFrameType 0-0;
SG_MUL_VAL_ 1607 ConsecutiveData3 IsoTpFrameType 2-2;
SG_MUL_VAL_ 1607 UnknownData3 IsoTpFrameType 4-15;
SG_MUL_VAL_ 1607 FirstData2 IsoTpFrameType 1-1;
SG_MUL_VAL_ 1607 FlowPadding1 IsoTpFrameType 3-3;
SG_MUL_VAL_ 1607 SingleData4 IsoTpFrameType 0-0;
SG_MUL_VAL_ 1607 ConsecutiveData4 IsoTpFrameType 2-2;
SG_MUL_VAL_ 1607 UnknownData4 IsoTpFrameType 4-15;
SG_MUL_VAL_ 1607 FirstData3 IsoTpFrameType 1-1;
SG_MUL_VAL_ 1607 FlowPadding2 IsoTpFrameType 3-3;
SG_MUL_VAL_ 1607 SingleData5 IsoTpFrameType 0-0;
SG_MUL_VAL_ 1607 ConsecutiveData5 IsoTpFrameType 2-2;
SG_MUL_VAL_ 1607 UnknownData5 IsoTpFrameType 4-15;
SG_MUL_VAL_ 1607 FirstData4 IsoTpFrameType 1-1;
SG_MUL_VAL_ 1607 FlowPadding3 IsoTpFrameType 3-3;
SG_MUL_VAL_ 1607 SingleData6 IsoTpFrameType 0-0;
SG_MUL_VAL_ 1607 ConsecutiveData6 IsoTpFrameType 2-2;
SG_MUL_VAL_ 1607 UnknownData6 IsoTpFrameType 4-15;
SG_MUL_VAL_ 1607 FirstData5 IsoTpFrameType 1-1;
SG_MUL_VAL_ 1607 FlowPadding4 IsoTpFrameType 3-3;
SG_MUL_VAL_ 1607 SingleData7 IsoTpFrameType 0-0;
SG_MUL_VAL_ 1607 ConsecutiveData7 IsoTpFrameType 2-2;
SG_MUL_VAL_ 1607 UnknownData7 IsoTpFrameType 4-15;
SG_MUL_VAL_ 1607 FirstData6 IsoTpFrameType 1-1;
SG_MUL_VAL_ 1607 FlowPadding5 IsoTpFrameType 3-3;
SG_MUL_VAL_ 1608 SingleFrameLength IsoTpFrameType 0-0;
SG_MUL_VAL_ 1608 FirstFrameLength IsoTpFrameType 1-1;
SG_MUL_VAL_ 1608 ConsecutiveSequence IsoTpFrameType 2-2;
SG_MUL_VAL_ 1608 FlowStatus IsoTpFrameType 3-3;
SG_MUL_VAL_ 1608 UnknownPciLow IsoTpFrameType 4-15;
SG_MUL_VAL_ 1608 BlockSize IsoTpFrameType 3-3;
SG_MUL_VAL_ 1608 SingleData1 IsoTpFrameType 0-0;
SG_MUL_VAL_ 1608 ConsecutiveData1 IsoTpFrameType 2-2;
SG_MUL_VAL_ 1608 UnknownData1 IsoTpFrameType 4-15;
SG_MUL_VAL_ 1608 SeparationTimeRaw IsoTpFrameType 3-3;
SG_MUL_VAL_ 1608 SingleData2 IsoTpFrameType 0-0;
SG_MUL_VAL_ 1608 ConsecutiveData2 IsoTpFrameType 2-2;
SG_MUL_VAL_ 1608 UnknownData2 IsoTpFrameType 4-15;
SG_MUL_VAL_ 1608 FirstData1 IsoTpFrameType 1-1;
SG_MUL_VAL_ 1608 SingleData3 IsoTpFrameType 0-0;
SG_MUL_VAL_ 1608 ConsecutiveData3 IsoTpFrameType 2-2;
SG_MUL_VAL_ 1608 UnknownData3 IsoTpFrameType 4-15;
SG_MUL_VAL_ 1608 FirstData2 IsoTpFrameType 1-1;
SG_MUL_VAL_ 1608 FlowPadding1 IsoTpFrameType 3-3;
SG_MUL_VAL_ 1608 SingleData4 IsoTpFrameType 0-0;
SG_MUL_VAL_ 1608 ConsecutiveData4 IsoTpFrameType 2-2;
SG_MUL_VAL_ 1608 UnknownData4 IsoTpFrameType 4-15;
SG_MUL_VAL_ 1608 FirstData3 IsoTpFrameType 1-1;
SG_MUL_VAL_ 1608 FlowPadding2 IsoTpFrameType 3-3;
SG_MUL_VAL_ 1608 SingleData5 IsoTpFrameType 0-0;
SG_MUL_VAL_ 1608 ConsecutiveData5 IsoTpFrameType 2-2;
SG_MUL_VAL_ 1608 UnknownData5 IsoTpFrameType 4-15;
SG_MUL_VAL_ 1608 FirstData4 IsoTpFrameType 1-1;
SG_MUL_VAL_ 1608 FlowPadding3 IsoTpFrameType 3-3;
SG_MUL_VAL_ 1608 SingleData6 IsoTpFrameType 0-0;
SG_MUL_VAL_ 1608 ConsecutiveData6 IsoTpFrameType 2-2;
SG_MUL_VAL_ 1608 UnknownData6 IsoTpFrameType 4-15;
SG_MUL_VAL_ 1608 FirstData5 IsoTpFrameType 1-1;
SG_MUL_VAL_ 1608 FlowPadding4 IsoTpFrameType 3-3;
SG_MUL_VAL_ 1608 SingleData7 IsoTpFrameType 0-0;
SG_MUL_VAL_ 1608 ConsecutiveData7 IsoTpFrameType 2-2;
SG_MUL_VAL_ 1608 UnknownData7 IsoTpFrameType 4-15;
SG_MUL_VAL_ 1608 FirstData6 IsoTpFrameType 1-1;
SG_MUL_VAL_ 1608 FlowPadding5 IsoTpFrameType 3-3;
SG_MUL_VAL_ 1609 SingleFrameLength IsoTpFrameType 0-0;
SG_MUL_VAL_ 1609 FirstFrameLength IsoTpFrameType 1-1;
SG_MUL_VAL_ 1609 ConsecutiveSequence IsoTpFrameType 2-2;
SG_MUL_VAL_ 1609 FlowStatus IsoTpFrameType 3-3;
SG_MUL_VAL_ 1609 UnknownPciLow IsoTpFrameType 4-15;
SG_MUL_VAL_ 1609 BlockSize IsoTpFrameType 3-3;
SG_MUL_VAL_ 1609 SingleData1 IsoTpFrameType 0-0;
SG_MUL_VAL_ 1609 ConsecutiveData1 IsoTpFrameType 2-2;
SG_MUL_VAL_ 1609 UnknownData1 IsoTpFrameType 4-15;
SG_MUL_VAL_ 1609 SeparationTimeRaw IsoTpFrameType 3-3;
SG_MUL_VAL_ 1609 SingleData2 IsoTpFrameType 0-0;
SG_MUL_VAL_ 1609 ConsecutiveData2 IsoTpFrameType 2-2;
SG_MUL_VAL_ 1609 UnknownData2 IsoTpFrameType 4-15;
SG_MUL_VAL_ 1609 FirstData1 IsoTpFrameType 1-1;
SG_MUL_VAL_ 1609 SingleData3 IsoTpFrameType 0-0;
SG_MUL_VAL_ 1609 ConsecutiveData3 IsoTpFrameType 2-2;
SG_MUL_VAL_ 1609 UnknownData3 IsoTpFrameType 4-15;
SG_MUL_VAL_ 1609 FirstData2 IsoTpFrameType 1-1;
SG_MUL_VAL_ 1609 FlowPadding1 IsoTpFrameType 3-3;
SG_MUL_VAL_ 1609 SingleData4 IsoTpFrameType 0-0;
SG_MUL_VAL_ 1609 ConsecutiveData4 IsoTpFrameType 2-2;
SG_MUL_VAL_ 1609 UnknownData4 IsoTpFrameType 4-15;
SG_MUL_VAL_ 1609 FirstData3 IsoTpFrameType 1-1;
SG_MUL_VAL_ 1609 FlowPadding2 IsoTpFrameType 3-3;
SG_MUL_VAL_ 1609 SingleData5 IsoTpFrameType 0-0;
SG_MUL_VAL_ 1609 ConsecutiveData5 IsoTpFrameType 2-2;
SG_MUL_VAL_ 1609 UnknownData5 IsoTpFrameType 4-15;
SG_MUL_VAL_ 1609 FirstData4 IsoTpFrameType 1-1;
SG_MUL_VAL_ 1609 FlowPadding3 IsoTpFrameType 3-3;
SG_MUL_VAL_ 1609 SingleData6 IsoTpFrameType 0-0;
SG_MUL_VAL_ 1609 ConsecutiveData6 IsoTpFrameType 2-2;
SG_MUL_VAL_ 1609 UnknownData6 IsoTpFrameType 4-15;
SG_MUL_VAL_ 1609 FirstData5 IsoTpFrameType 1-1;
SG_MUL_VAL_ 1609 FlowPadding4 IsoTpFrameType 3-3;
SG_MUL_VAL_ 1609 SingleData7 IsoTpFrameType 0-0;
SG_MUL_VAL_ 1609 ConsecutiveData7 IsoTpFrameType 2-2;
SG_MUL_VAL_ 1609 UnknownData7 IsoTpFrameType 4-15;
SG_MUL_VAL_ 1609 FirstData6 IsoTpFrameType 1-1;
SG_MUL_VAL_ 1609 FlowPadding5 IsoTpFrameType 3-3;
SG_MUL_VAL_ 1610 SingleFrameLength IsoTpFrameType 0-0;
SG_MUL_VAL_ 1610 FirstFrameLength IsoTpFrameType 1-1;
SG_MUL_VAL_ 1610 ConsecutiveSequence IsoTpFrameType 2-2;
SG_MUL_VAL_ 1610 FlowStatus IsoTpFrameType 3-3;
SG_MUL_VAL_ 1610 UnknownPciLow IsoTpFrameType 4-15;
SG_MUL_VAL_ 1610 BlockSize IsoTpFrameType 3-3;
SG_MUL_VAL_ 1610 SingleData1 IsoTpFrameType 0-0;
SG_MUL_VAL_ 1610 ConsecutiveData1 IsoTpFrameType 2-2;
SG_MUL_VAL_ 1610 UnknownData1 IsoTpFrameType 4-15;
SG_MUL_VAL_ 1610 SeparationTimeRaw IsoTpFrameType 3-3;
SG_MUL_VAL_ 1610 SingleData2 IsoTpFrameType 0-0;
SG_MUL_VAL_ 1610 ConsecutiveData2 IsoTpFrameType 2-2;
SG_MUL_VAL_ 1610 UnknownData2 IsoTpFrameType 4-15;
SG_MUL_VAL_ 1610 FirstData1 IsoTpFrameType 1-1;
SG_MUL_VAL_ 1610 SingleData3 IsoTpFrameType 0-0;
SG_MUL_VAL_ 1610 ConsecutiveData3 IsoTpFrameType 2-2;
SG_MUL_VAL_ 1610 UnknownData3 IsoTpFrameType 4-15;
SG_MUL_VAL_ 1610 FirstData2 IsoTpFrameType 1-1;
SG_MUL_VAL_ 1610 FlowPadding1 IsoTpFrameType 3-3;
SG_MUL_VAL_ 1610 SingleData4 IsoTpFrameType 0-0;
SG_MUL_VAL_ 1610 ConsecutiveData4 IsoTpFrameType 2-2;
SG_MUL_VAL_ 1610 UnknownData4 IsoTpFrameType 4-15;
SG_MUL_VAL_ 1610 FirstData3 IsoTpFrameType 1-1;
SG_MUL_VAL_ 1610 FlowPadding2 IsoTpFrameType 3-3;
SG_MUL_VAL_ 1610 SingleData5 IsoTpFrameType 0-0;
SG_MUL_VAL_ 1610 ConsecutiveData5 IsoTpFrameType 2-2;
SG_MUL_VAL_ 1610 UnknownData5 IsoTpFrameType 4-15;
SG_MUL_VAL_ 1610 FirstData4 IsoTpFrameType 1-1;
SG_MUL_VAL_ 1610 FlowPadding3 IsoTpFrameType 3-3;
SG_MUL_VAL_ 1610 SingleData6 IsoTpFrameType 0-0;
SG_MUL_VAL_ 1610 ConsecutiveData6 IsoTpFrameType 2-2;
SG_MUL_VAL_ 1610 UnknownData6 IsoTpFrameType 4-15;
SG_MUL_VAL_ 1610 FirstData5 IsoTpFrameType 1-1;
SG_MUL_VAL_ 1610 FlowPadding4 IsoTpFrameType 3-3;
SG_MUL_VAL_ 1610 SingleData7 IsoTpFrameType 0-0;
SG_MUL_VAL_ 1610 ConsecutiveData7 IsoTpFrameType 2-2;
SG_MUL_VAL_ 1610 UnknownData7 IsoTpFrameType 4-15;
SG_MUL_VAL_ 1610 FirstData6 IsoTpFrameType 1-1;
SG_MUL_VAL_ 1610 FlowPadding5 IsoTpFrameType 3-3;
